VERSION "HINBNNNYYNNNYYNNNNNNNNNNNNYNNNYYYNNYNNNNNN/4//%%/4/'%**4NNN///"

NS_ :

BS_:

BU_: VirtualNMTMaster Master LadderDrive ControlPanel SupportFront SupportRear TTGateway

BO_ 1421 SSDO_013: 8 SupportRear
 SG_ supported_drive_modes_6502 m0 : 32|32@1+ (1,0) [0|4294967295] "" Vector__XXX
 SG_ SubIndex_6502 m25858M : 24|8@1+ (1,0) [0|0] "" Vector__XXX
 SG_ motor_service_period_6407 m0 : 32|32@1+ (1,0) [0|4294967295] "" Vector__XXX
 SG_ SubIndex_6407 m25607M : 24|8@1+ (1,0) [0|0] "" Vector__XXX
 SG_ motor_type_6402 m0 : 32|16@1+ (1,0) [0|65535] "" Vector__XXX
 SG_ SubIndex_6402 m25602M : 24|8@1+ (1,0) [0|0] "" Vector__XXX
 SG_ bitmask_60FE_02 m2 : 32|32@1+ (1,0) [0|4294967295] "" Vector__XXX
 SG_ physical_outputs_60FE_01 m1 : 32|32@1+ (1,0) [0|4294967295] "" Vector__XXX
 SG_ NrOfObjects_60FE_00 m0 : 32|8@1+ (1,0) [0|255] "" Vector__XXX
 SG_ SubIndex_60FE m24830M : 24|8@1+ (1,0) [0|2] "" Vector__XXX
 SG_ digital_inputs_60FD m0 : 32|32@1+ (1,0) [0|4294967295] "" Vector__XXX
 SG_ SubIndex_60FD m24829M : 24|8@1+ (1,0) [0|0] "" Vector__XXX
 SG_ polarity_607E m0 : 32|8@1+ (1,0) [0|255] "" Vector__XXX
 SG_ SubIndex_607E m24702M : 24|8@1+ (1,0) [0|0] "" Vector__XXX
 SG_ position_window_6067 m0 : 32|32@1+ (1,0) [0|4294967295] "" Vector__XXX
 SG_ SubIndex_6067 m24679M : 24|8@1+ (1,0) [0|0] "" Vector__XXX
 SG_ position_actual_value_6064 m0 : 32|32@1- (1,0) [-2147483648|2147483647] "" Vector__XXX
 SG_ SubIndex_6064 m24676M : 24|8@1+ (1,0) [0|0] "" Vector__XXX
 SG_ position_actual_value_6063 m0 : 32|32@1- (1,0) [-2147483648|2147483647] "" Vector__XXX
 SG_ SubIndex_6063 m24675M : 24|8@1+ (1,0) [0|0] "" Vector__XXX
 SG_ position_demand_value_6062 m0 : 32|32@1- (1,0) [-2147483648|2147483647] "" Vector__XXX
 SG_ SubIndex_6062 m24674M : 24|8@1+ (1,0) [0|0] "" Vector__XXX
 SG_ modes_of_operation_display_6061 m0 : 32|8@1- (1,0) [-128|127] "" Vector__XXX
 SG_ SubIndex_6061 m24673M : 24|8@1+ (1,0) [0|0] "" Vector__XXX
 SG_ modes_of_operation_6060 m0 : 32|8@1- (1,0) [-128|127] "" Vector__XXX
 SG_ SubIndex_6060 m24672M : 24|8@1+ (1,0) [0|0] "" Vector__XXX
 SG_ fault_reaction_option_code_605E m0 : 32|16@1- (1,0) [-32768|32767] "" Vector__XXX
 SG_ SubIndex_605E m24670M : 24|8@1+ (1,0) [0|0] "" Vector__XXX
 SG_ stop_option_code_605D m0 : 32|16@1- (1,0) [-32768|32767] "" Vector__XXX
 SG_ SubIndex_605D m24669M : 24|8@1+ (1,0) [0|0] "" Vector__XXX
 SG_ disable_operation_option_co_0003 m0 : 32|16@1- (1,0) [-32768|32767] "" Vector__XXX
 SG_ SubIndex_605C m24668M : 24|8@1+ (1,0) [0|0] "" Vector__XXX
 SG_ shutdown_option_code_605B m0 : 32|16@1- (1,0) [-32768|32767] "" Vector__XXX
 SG_ SubIndex_605B m24667M : 24|8@1+ (1,0) [0|0] "" Vector__XXX
 SG_ quick_stop_option_code_605A m0 : 32|16@1- (1,0) [-32768|32767] "" Vector__XXX
 SG_ SubIndex_605A m24666M : 24|8@1+ (1,0) [0|0] "" Vector__XXX
 SG_ delta_time_6049_02 m2 : 32|16@1+ (1,0) [0|65535] "" Vector__XXX
 SG_ delta_speed_6049_01 m1 : 32|32@1+ (1,0) [0|4294967295] "" Vector__XXX
 SG_ NrOfObjects_6049_00 m0 : 32|8@1+ (1,0) [0|255] "" Vector__XXX
 SG_ SubIndex_6049 m24649M : 24|8@1+ (1,0) [0|2] "" Vector__XXX
 SG_ delta_time_6048_02 m2 : 32|16@1+ (1,0) [0|65535] "" Vector__XXX
 SG_ delta_speed_6048_01 m1 : 32|32@1+ (1,0) [0|4294967295] "" Vector__XXX
 SG_ NrOfObjects_6048_00 m0 : 32|8@1+ (1,0) [0|255] "" Vector__XXX
 SG_ SubIndex_6048 m24648M : 24|8@1+ (1,0) [0|2] "" Vector__XXX
 SG_ vl_velocity_max_amount_6046_02 m2 : 32|32@1+ (1,0) [0|4294967295] "" Vector__XXX
 SG_ vl_velocity_min_amount_6046_01 m1 : 32|32@1+ (1,0) [0|4294967295] "" Vector__XXX
 SG_ vl_velocity_min_max_amount__0003 m0 : 32|8@1+ (1,0) [0|255] "" Vector__XXX
 SG_ SubIndex_6046 m24646M : 24|8@1+ (1,0) [0|2] "" Vector__XXX
 SG_ vl_control_effort_6044 m0 : 32|16@1- (1,0) [-32768|32767] "" Vector__XXX
 SG_ SubIndex_6044 m24644M : 24|8@1+ (1,0) [0|0] "" Vector__XXX
 SG_ vl_velocity_demand_6043 m0 : 32|16@1- (1,0) [-32768|32767] "" Vector__XXX
 SG_ SubIndex_6043 m24643M : 24|8@1+ (1,0) [0|0] "" Vector__XXX
 SG_ vl_target_velocity_6042 m0 : 32|16@1- (1,0) [-32768|32767] "" Vector__XXX
 SG_ SubIndex_6042 m24642M : 24|8@1+ (1,0) [0|0] "" Vector__XXX
 SG_ statusword_6041 m0 : 32|16@1+ (1,0) [0|65535] "" Vector__XXX
 SG_ SubIndex_6041 m24641M : 24|8@1+ (1,0) [0|0] "" Vector__XXX
 SG_ controlword_6040 m0 : 32|16@1+ (1,0) [0|65535] "" Vector__XXX
 SG_ SubIndex_6040 m24640M : 24|8@1+ (1,0) [0|0] "" Vector__XXX
 SG_ error_code_603F m0 : 32|16@1+ (1,0) [0|65535] "" Vector__XXX
 SG_ SubIndex_603F m24639M : 24|8@1+ (1,0) [0|0] "" Vector__XXX
 SG_ abort_connection_option_cod_0003 m0 : 32|16@1- (1,0) [-32768|3] "" Vector__XXX
 SG_ SubIndex_6007 m24583M : 24|8@1+ (1,0) [0|0] "" Vector__XXX
 SG_ NrOfMappedObjects_1A06_00 m0 : 32|8@1+ (1,0) [0|8] "" Vector__XXX
 SG_ SubIndex_1A06 m6662M : 24|8@1+ (1,0) [0|0] "" Vector__XXX
 SG_ NrOfMappedObjects_1A05_00 m0 : 32|8@1+ (1,0) [0|8] "" Vector__XXX
 SG_ SubIndex_1A05 m6661M : 24|8@1+ (1,0) [0|0] "" Vector__XXX
 SG_ NrOfMappedObjects_1A04_00 m0 : 32|8@1+ (1,0) [0|8] "" Vector__XXX
 SG_ SubIndex_1A04 m6660M : 24|8@1+ (1,0) [0|0] "" Vector__XXX
 SG_ NrOfMappedObjects_1A03_00 m0 : 32|8@1+ (1,0) [0|8] "" Vector__XXX
 SG_ SubIndex_1A03 m6659M : 24|8@1+ (1,0) [0|0] "" Vector__XXX
 SG_ NrOfMappedObjects_1A02_00 m0 : 32|8@1+ (1,0) [0|8] "" Vector__XXX
 SG_ SubIndex_1A02 m6658M : 24|8@1+ (1,0) [0|0] "" Vector__XXX
 SG_ NrOfMappedObjects_1A01_00 m0 : 32|8@1+ (1,0) [0|8] "" Vector__XXX
 SG_ SubIndex_1A01 m6657M : 24|8@1+ (1,0) [0|0] "" Vector__XXX
 SG_ mappedObj2_1A00_02 m2 : 32|32@1+ (1,0) [0|4294967295] "" Vector__XXX
 SG_ mappedObj1_1A00_01 m1 : 32|32@1+ (1,0) [0|4294967295] "" Vector__XXX
 SG_ NrOfMappedObjects_1A00_00 m0 : 32|8@1+ (1,0) [0|8] "" Vector__XXX
 SG_ SubIndex_1A00 m6656M : 24|8@1+ (1,0) [0|2] "" Vector__XXX
 SG_ EventTimer_1806_05 m5 : 32|16@1+ (1,0) [0|65535] "" Vector__XXX
 SG_ TransmissionType_1806_02 m2 : 32|8@1+ (1,0) [0|255] "" Vector__XXX
 SG_ COB_ID_1806_01 m1 : 32|32@1+ (1,0) [128|4294967295] "" Vector__XXX
 SG_ NrOfEntries_1806_00 m0 : 32|8@1+ (1,0) [2|5] "" Vector__XXX
 SG_ SubIndex_1806 m6150M : 24|8@1+ (1,0) [0|5] "" Vector__XXX
 SG_ EventTimer_1805_05 m5 : 32|16@1+ (1,0) [0|65535] "" Vector__XXX
 SG_ TransmissionType_1805_02 m2 : 32|8@1+ (1,0) [0|255] "" Vector__XXX
 SG_ COB_ID_1805_01 m1 : 32|32@1+ (1,0) [128|4294967295] "" Vector__XXX
 SG_ NrOfEntries_1805_00 m0 : 32|8@1+ (1,0) [2|5] "" Vector__XXX
 SG_ SubIndex_1805 m6149M : 24|8@1+ (1,0) [0|5] "" Vector__XXX
 SG_ EventTimer_1804_05 m5 : 32|16@1+ (1,0) [0|65535] "" Vector__XXX
 SG_ TransmissionType_1804_02 m2 : 32|8@1+ (1,0) [0|255] "" Vector__XXX
 SG_ COB_ID_1804_01 m1 : 32|32@1+ (1,0) [128|4294967295] "" Vector__XXX
 SG_ NrOfEntries_1804_00 m0 : 32|8@1+ (1,0) [2|5] "" Vector__XXX
 SG_ SubIndex_1804 m6148M : 24|8@1+ (1,0) [0|5] "" Vector__XXX
 SG_ EventTimer_1803_05 m5 : 32|16@1+ (1,0) [0|65535] "" Vector__XXX
 SG_ TransmissionType_1803_02 m2 : 32|8@1+ (1,0) [0|255] "" Vector__XXX
 SG_ COB_ID_1803_01 m1 : 32|32@1+ (1,0) [128|4294967295] "" Vector__XXX
 SG_ NrOfEntries_1803_00 m0 : 32|8@1+ (1,0) [2|5] "" Vector__XXX
 SG_ SubIndex_1803 m6147M : 24|8@1+ (1,0) [0|5] "" Vector__XXX
 SG_ EventTimer_1802_05 m5 : 32|16@1+ (1,0) [0|65535] "" Vector__XXX
 SG_ TransmissionType_1802_02 m2 : 32|8@1+ (1,0) [0|255] "" Vector__XXX
 SG_ COB_ID_1802_01 m1 : 32|32@1+ (1,0) [128|4294967295] "" Vector__XXX
 SG_ NrOfEntries_1802_00 m0 : 32|8@1+ (1,0) [2|5] "" Vector__XXX
 SG_ SubIndex_1802 m6146M : 24|8@1+ (1,0) [0|5] "" Vector__XXX
 SG_ EventTimer_1801_05 m5 : 32|16@1+ (1,0) [0|65535] "" Vector__XXX
 SG_ TransmissionType_1801_02 m2 : 32|8@1+ (1,0) [0|255] "" Vector__XXX
 SG_ COB_ID_1801_01 m1 : 32|32@1+ (1,0) [128|4294967295] "" Vector__XXX
 SG_ NrOfEntries_1801_00 m0 : 32|8@1+ (1,0) [2|5] "" Vector__XXX
 SG_ SubIndex_1801 m6145M : 24|8@1+ (1,0) [0|5] "" Vector__XXX
 SG_ EventTimer_1800_05 m5 : 32|16@1+ (1,0) [0|65535] "" Vector__XXX
 SG_ TransmissionType_1800_02 m2 : 32|8@1+ (1,0) [0|255] "" Vector__XXX
 SG_ COB_ID_1800_01 m1 : 32|32@1+ (1,0) [128|4294967295] "" Vector__XXX
 SG_ NrOfEntries_1800_00 m0 : 32|8@1+ (1,0) [2|5] "" Vector__XXX
 SG_ SubIndex_1800 m6144M : 24|8@1+ (1,0) [0|5] "" Vector__XXX
 SG_ NrOfMappedObjects_1607_00 m0 : 32|8@1+ (1,0) [0|8] "" Vector__XXX
 SG_ SubIndex_1607 m5639M : 24|8@1+ (1,0) [0|0] "" Vector__XXX
 SG_ NrOfMappedObjects_1606_00 m0 : 32|8@1+ (1,0) [0|8] "" Vector__XXX
 SG_ SubIndex_1606 m5638M : 24|8@1+ (1,0) [0|0] "" Vector__XXX
 SG_ NrOfMappedObjects_1605_00 m0 : 32|8@1+ (1,0) [0|8] "" Vector__XXX
 SG_ SubIndex_1605 m5637M : 24|8@1+ (1,0) [0|0] "" Vector__XXX
 SG_ NrOfMappedObjects_1604_00 m0 : 32|8@1+ (1,0) [0|8] "" Vector__XXX
 SG_ SubIndex_1604 m5636M : 24|8@1+ (1,0) [0|0] "" Vector__XXX
 SG_ NrOfMappedObjects_1603_00 m0 : 32|8@1+ (1,0) [0|8] "" Vector__XXX
 SG_ SubIndex_1603 m5635M : 24|8@1+ (1,0) [0|0] "" Vector__XXX
 SG_ NrOfMappedObjects_1602_00 m0 : 32|8@1+ (1,0) [0|8] "" Vector__XXX
 SG_ SubIndex_1602 m5634M : 24|8@1+ (1,0) [0|0] "" Vector__XXX
 SG_ NrOfMappedObjects_1601_00 m0 : 32|8@1+ (1,0) [0|8] "" Vector__XXX
 SG_ SubIndex_1601 m5633M : 24|8@1+ (1,0) [0|0] "" Vector__XXX
 SG_ mappedObj2_1600_02 m2 : 32|32@1+ (1,0) [0|4294967295] "" Vector__XXX
 SG_ mappedObj1_1600_01 m1 : 32|32@1+ (1,0) [0|4294967295] "" Vector__XXX
 SG_ NrOfMappedObjects_1600_00 m0 : 32|8@1+ (1,0) [0|8] "" Vector__XXX
 SG_ SubIndex_1600 m5632M : 24|8@1+ (1,0) [0|2] "" Vector__XXX
 SG_ TransmissionType_1407_02 m2 : 32|8@1+ (1,0) [0|255] "" Vector__XXX
 SG_ COB_ID_1407_01 m1 : 32|32@1+ (1,0) [128|4294967295] "" Vector__XXX
 SG_ NrOfEntries_1407_00 m0 : 32|8@1+ (1,0) [2|5] "" Vector__XXX
 SG_ SubIndex_1407 m5127M : 24|8@1+ (1,0) [0|2] "" Vector__XXX
 SG_ TransmissionType_1406_02 m2 : 32|8@1+ (1,0) [0|255] "" Vector__XXX
 SG_ COB_ID_1406_01 m1 : 32|32@1+ (1,0) [128|4294967295] "" Vector__XXX
 SG_ NrOfEntries_1406_00 m0 : 32|8@1+ (1,0) [2|5] "" Vector__XXX
 SG_ SubIndex_1406 m5126M : 24|8@1+ (1,0) [0|2] "" Vector__XXX
 SG_ TransmissionType_1405_02 m2 : 32|8@1+ (1,0) [0|255] "" Vector__XXX
 SG_ COB_ID_1405_01 m1 : 32|32@1+ (1,0) [128|4294967295] "" Vector__XXX
 SG_ NrOfEntries_1405_00 m0 : 32|8@1+ (1,0) [2|5] "" Vector__XXX
 SG_ SubIndex_1405 m5125M : 24|8@1+ (1,0) [0|2] "" Vector__XXX
 SG_ TransmissionType_1404_02 m2 : 32|8@1+ (1,0) [0|255] "" Vector__XXX
 SG_ COB_ID_1404_01 m1 : 32|32@1+ (1,0) [128|4294967295] "" Vector__XXX
 SG_ NrOfEntries_1404_00 m0 : 32|8@1+ (1,0) [2|5] "" Vector__XXX
 SG_ SubIndex_1404 m5124M : 24|8@1+ (1,0) [0|2] "" Vector__XXX
 SG_ TransmissionType_1403_02 m2 : 32|8@1+ (1,0) [0|255] "" Vector__XXX
 SG_ COB_ID_1403_01 m1 : 32|32@1+ (1,0) [128|4294967295] "" Vector__XXX
 SG_ NrOfEntries_1403_00 m0 : 32|8@1+ (1,0) [2|5] "" Vector__XXX
 SG_ SubIndex_1403 m5123M : 24|8@1+ (1,0) [0|2] "" Vector__XXX
 SG_ TransmissionType_1402_02 m2 : 32|8@1+ (1,0) [0|255] "" Vector__XXX
 SG_ COB_ID_1402_01 m1 : 32|32@1+ (1,0) [128|4294967295] "" Vector__XXX
 SG_ NrOfEntries_1402_00 m0 : 32|8@1+ (1,0) [2|5] "" Vector__XXX
 SG_ SubIndex_1402 m5122M : 24|8@1+ (1,0) [0|2] "" Vector__XXX
 SG_ TransmissionType_1401_02 m2 : 32|8@1+ (1,0) [0|255] "" Vector__XXX
 SG_ COB_ID_1401_01 m1 : 32|32@1+ (1,0) [128|4294967295] "" Vector__XXX
 SG_ NrOfEntries_1401_00 m0 : 32|8@1+ (1,0) [2|5] "" Vector__XXX
 SG_ SubIndex_1401 m5121M : 24|8@1+ (1,0) [0|2] "" Vector__XXX
 SG_ TransmissionType_1400_02 m2 : 32|8@1+ (1,0) [0|255] "" Vector__XXX
 SG_ COB_ID_1400_01 m1 : 32|32@1+ (1,0) [128|4294967295] "" Vector__XXX
 SG_ NrOfEntries_1400_00 m0 : 32|8@1+ (1,0) [2|5] "" Vector__XXX
 SG_ SubIndex_1400 m5120M : 24|8@1+ (1,0) [0|2] "" Vector__XXX
 SG_ Serial_number_1018_04 m4 : 32|32@1+ (1,0) [0|4294967295] "" Vector__XXX
 SG_ Revision_number_1018_03 m3 : 32|32@1+ (1,0) [0|4294967295] "" Vector__XXX
 SG_ Product_Code_1018_02 m2 : 32|32@1+ (1,0) [0|4294967295] "" Vector__XXX
 SG_ Vendor_Id_1018_01 m1 : 32|32@1+ (1,0) [0|4294967295] "" Vector__XXX
 SG_ number_of_entries_1018_00 m0 : 32|8@1+ (1,0) [1|4] "" Vector__XXX
 SG_ SubIndex_1018 m4120M : 24|8@1+ (1,0) [0|4] "" Vector__XXX
 SG_ Producer_Heartbeat_Time_1017 m0 : 32|16@1+ (1,0) [0|65535] "" Vector__XXX
 SG_ SubIndex_1017 m4119M : 24|8@1+ (1,0) [0|0] "" Vector__XXX
 SG_ Consumer_Heartbeat_Time126_1016_ m126 : 32|32@1+ (1,0) [0|4294967295] "" Vector__XXX
 SG_ Consumer_Heartbeat_Time125_1016_ m125 : 32|32@1+ (1,0) [0|4294967295] "" Vector__XXX
 SG_ Consumer_Heartbeat_Time124_1016_ m124 : 32|32@1+ (1,0) [0|4294967295] "" Vector__XXX
 SG_ Consumer_Heartbeat_Time123_1016_ m123 : 32|32@1+ (1,0) [0|4294967295] "" Vector__XXX
 SG_ Consumer_Heartbeat_Time122_1016_ m122 : 32|32@1+ (1,0) [0|4294967295] "" Vector__XXX
 SG_ Consumer_Heartbeat_Time121_1016_ m121 : 32|32@1+ (1,0) [0|4294967295] "" Vector__XXX
 SG_ Consumer_Heartbeat_Time120_1016_ m120 : 32|32@1+ (1,0) [0|4294967295] "" Vector__XXX
 SG_ Consumer_Heartbeat_Time119_1016_ m119 : 32|32@1+ (1,0) [0|4294967295] "" Vector__XXX
 SG_ Consumer_Heartbeat_Time118_1016_ m118 : 32|32@1+ (1,0) [0|4294967295] "" Vector__XXX
 SG_ Consumer_Heartbeat_Time117_1016_ m117 : 32|32@1+ (1,0) [0|4294967295] "" Vector__XXX
 SG_ Consumer_Heartbeat_Time116_1016_ m116 : 32|32@1+ (1,0) [0|4294967295] "" Vector__XXX
 SG_ Consumer_Heartbeat_Time115_1016_ m115 : 32|32@1+ (1,0) [0|4294967295] "" Vector__XXX
 SG_ Consumer_Heartbeat_Time114_1016_ m114 : 32|32@1+ (1,0) [0|4294967295] "" Vector__XXX
 SG_ Consumer_Heartbeat_Time113_1016_ m113 : 32|32@1+ (1,0) [0|4294967295] "" Vector__XXX
 SG_ Consumer_Heartbeat_Time112_1016_ m112 : 32|32@1+ (1,0) [0|4294967295] "" Vector__XXX
 SG_ Consumer_Heartbeat_Time111_1016_ m111 : 32|32@1+ (1,0) [0|4294967295] "" Vector__XXX
 SG_ Consumer_Heartbeat_Time110_1016_ m110 : 32|32@1+ (1,0) [0|4294967295] "" Vector__XXX
 SG_ Consumer_Heartbeat_Time109_1016_ m109 : 32|32@1+ (1,0) [0|4294967295] "" Vector__XXX
 SG_ Consumer_Heartbeat_Time108_1016_ m108 : 32|32@1+ (1,0) [0|4294967295] "" Vector__XXX
 SG_ Consumer_Heartbeat_Time107_1016_ m107 : 32|32@1+ (1,0) [0|4294967295] "" Vector__XXX
 SG_ Consumer_Heartbeat_Time106_1016_ m106 : 32|32@1+ (1,0) [0|4294967295] "" Vector__XXX
 SG_ Consumer_Heartbeat_Time105_1016_ m105 : 32|32@1+ (1,0) [0|4294967295] "" Vector__XXX
 SG_ Consumer_Heartbeat_Time104_1016_ m104 : 32|32@1+ (1,0) [0|4294967295] "" Vector__XXX
 SG_ Consumer_Heartbeat_Time103_1016_ m103 : 32|32@1+ (1,0) [0|4294967295] "" Vector__XXX
 SG_ Consumer_Heartbeat_Time102_1016_ m102 : 32|32@1+ (1,0) [0|4294967295] "" Vector__XXX
 SG_ Consumer_Heartbeat_Time101_1016_ m101 : 32|32@1+ (1,0) [0|4294967295] "" Vector__XXX
 SG_ Consumer_Heartbeat_Time100_1016_ m100 : 32|32@1+ (1,0) [0|4294967295] "" Vector__XXX
 SG_ Consumer_Heartbeat_Time99_1016_6 m99 : 32|32@1+ (1,0) [0|4294967295] "" Vector__XXX
 SG_ Consumer_Heartbeat_Time98_1016_6 m98 : 32|32@1+ (1,0) [0|4294967295] "" Vector__XXX
 SG_ Consumer_Heartbeat_Time97_1016_6 m97 : 32|32@1+ (1,0) [0|4294967295] "" Vector__XXX
 SG_ Consumer_Heartbeat_Time96_1016_6 m96 : 32|32@1+ (1,0) [0|4294967295] "" Vector__XXX
 SG_ Consumer_Heartbeat_Time95_1016_5 m95 : 32|32@1+ (1,0) [0|4294967295] "" Vector__XXX
 SG_ Consumer_Heartbeat_Time94_1016_5 m94 : 32|32@1+ (1,0) [0|4294967295] "" Vector__XXX
 SG_ Consumer_Heartbeat_Time93_1016_5 m93 : 32|32@1+ (1,0) [0|4294967295] "" Vector__XXX
 SG_ Consumer_Heartbeat_Time92_1016_5 m92 : 32|32@1+ (1,0) [0|4294967295] "" Vector__XXX
 SG_ Consumer_Heartbeat_Time91_1016_5 m91 : 32|32@1+ (1,0) [0|4294967295] "" Vector__XXX
 SG_ Consumer_Heartbeat_Time90_1016_5 m90 : 32|32@1+ (1,0) [0|4294967295] "" Vector__XXX
 SG_ Consumer_Heartbeat_Time89_1016_5 m89 : 32|32@1+ (1,0) [0|4294967295] "" Vector__XXX
 SG_ Consumer_Heartbeat_Time88_1016_5 m88 : 32|32@1+ (1,0) [0|4294967295] "" Vector__XXX
 SG_ Consumer_Heartbeat_Time87_1016_5 m87 : 32|32@1+ (1,0) [0|4294967295] "" Vector__XXX
 SG_ Consumer_Heartbeat_Time86_1016_5 m86 : 32|32@1+ (1,0) [0|4294967295] "" Vector__XXX
 SG_ Consumer_Heartbeat_Time85_1016_5 m85 : 32|32@1+ (1,0) [0|4294967295] "" Vector__XXX
 SG_ Consumer_Heartbeat_Time84_1016_5 m84 : 32|32@1+ (1,0) [0|4294967295] "" Vector__XXX
 SG_ Consumer_Heartbeat_Time83_1016_5 m83 : 32|32@1+ (1,0) [0|4294967295] "" Vector__XXX
 SG_ Consumer_Heartbeat_Time82_1016_5 m82 : 32|32@1+ (1,0) [0|4294967295] "" Vector__XXX
 SG_ Consumer_Heartbeat_Time81_1016_5 m81 : 32|32@1+ (1,0) [0|4294967295] "" Vector__XXX
 SG_ Consumer_Heartbeat_Time80_1016_5 m80 : 32|32@1+ (1,0) [0|4294967295] "" Vector__XXX
 SG_ Consumer_Heartbeat_Time79_1016_4 m79 : 32|32@1+ (1,0) [0|4294967295] "" Vector__XXX
 SG_ Consumer_Heartbeat_Time78_1016_4 m78 : 32|32@1+ (1,0) [0|4294967295] "" Vector__XXX
 SG_ Consumer_Heartbeat_Time77_1016_4 m77 : 32|32@1+ (1,0) [0|4294967295] "" Vector__XXX
 SG_ Consumer_Heartbeat_Time76_1016_4 m76 : 32|32@1+ (1,0) [0|4294967295] "" Vector__XXX
 SG_ Consumer_Heartbeat_Time75_1016_4 m75 : 32|32@1+ (1,0) [0|4294967295] "" Vector__XXX
 SG_ Consumer_Heartbeat_Time74_1016_4 m74 : 32|32@1+ (1,0) [0|4294967295] "" Vector__XXX
 SG_ Consumer_Heartbeat_Time73_1016_4 m73 : 32|32@1+ (1,0) [0|4294967295] "" Vector__XXX
 SG_ Consumer_Heartbeat_Time72_1016_4 m72 : 32|32@1+ (1,0) [0|4294967295] "" Vector__XXX
 SG_ Consumer_Heartbeat_Time71_1016_4 m71 : 32|32@1+ (1,0) [0|4294967295] "" Vector__XXX
 SG_ Consumer_Heartbeat_Time70_1016_4 m70 : 32|32@1+ (1,0) [0|4294967295] "" Vector__XXX
 SG_ Consumer_Heartbeat_Time69_1016_4 m69 : 32|32@1+ (1,0) [0|4294967295] "" Vector__XXX
 SG_ Consumer_Heartbeat_Time68_1016_4 m68 : 32|32@1+ (1,0) [0|4294967295] "" Vector__XXX
 SG_ Consumer_Heartbeat_Time67_1016_4 m67 : 32|32@1+ (1,0) [0|4294967295] "" Vector__XXX
 SG_ Consumer_Heartbeat_Time66_1016_4 m66 : 32|32@1+ (1,0) [0|4294967295] "" Vector__XXX
 SG_ Consumer_Heartbeat_Time65_1016_4 m65 : 32|32@1+ (1,0) [0|4294967295] "" Vector__XXX
 SG_ Consumer_Heartbeat_Time64_1016_4 m64 : 32|32@1+ (1,0) [0|4294967295] "" Vector__XXX
 SG_ Consumer_Heartbeat_Time63_1016_3 m63 : 32|32@1+ (1,0) [0|4294967295] "" Vector__XXX
 SG_ Consumer_Heartbeat_Time62_1016_3 m62 : 32|32@1+ (1,0) [0|4294967295] "" Vector__XXX
 SG_ Consumer_Heartbeat_Time61_1016_3 m61 : 32|32@1+ (1,0) [0|4294967295] "" Vector__XXX
 SG_ Consumer_Heartbeat_Time60_1016_3 m60 : 32|32@1+ (1,0) [0|4294967295] "" Vector__XXX
 SG_ Consumer_Heartbeat_Time59_1016_3 m59 : 32|32@1+ (1,0) [0|4294967295] "" Vector__XXX
 SG_ Consumer_Heartbeat_Time58_1016_3 m58 : 32|32@1+ (1,0) [0|4294967295] "" Vector__XXX
 SG_ Consumer_Heartbeat_Time57_1016_3 m57 : 32|32@1+ (1,0) [0|4294967295] "" Vector__XXX
 SG_ Consumer_Heartbeat_Time56_1016_3 m56 : 32|32@1+ (1,0) [0|4294967295] "" Vector__XXX
 SG_ Consumer_Heartbeat_Time55_1016_3 m55 : 32|32@1+ (1,0) [0|4294967295] "" Vector__XXX
 SG_ Consumer_Heartbeat_Time54_1016_3 m54 : 32|32@1+ (1,0) [0|4294967295] "" Vector__XXX
 SG_ Consumer_Heartbeat_Time53_1016_3 m53 : 32|32@1+ (1,0) [0|4294967295] "" Vector__XXX
 SG_ Consumer_Heartbeat_Time52_1016_3 m52 : 32|32@1+ (1,0) [0|4294967295] "" Vector__XXX
 SG_ Consumer_Heartbeat_Time51_1016_3 m51 : 32|32@1+ (1,0) [0|4294967295] "" Vector__XXX
 SG_ Consumer_Heartbeat_Time50_1016_3 m50 : 32|32@1+ (1,0) [0|4294967295] "" Vector__XXX
 SG_ Consumer_Heartbeat_Time49_1016_3 m49 : 32|32@1+ (1,0) [0|4294967295] "" Vector__XXX
 SG_ Consumer_Heartbeat_Time48_1016_3 m48 : 32|32@1+ (1,0) [0|4294967295] "" Vector__XXX
 SG_ Consumer_Heartbeat_Time47_1016_2 m47 : 32|32@1+ (1,0) [0|4294967295] "" Vector__XXX
 SG_ Consumer_Heartbeat_Time46_1016_2 m46 : 32|32@1+ (1,0) [0|4294967295] "" Vector__XXX
 SG_ Consumer_Heartbeat_Time45_1016_2 m45 : 32|32@1+ (1,0) [0|4294967295] "" Vector__XXX
 SG_ Consumer_Heartbeat_Time44_1016_2 m44 : 32|32@1+ (1,0) [0|4294967295] "" Vector__XXX
 SG_ Consumer_Heartbeat_Time43_1016_2 m43 : 32|32@1+ (1,0) [0|4294967295] "" Vector__XXX
 SG_ Consumer_Heartbeat_Time42_1016_2 m42 : 32|32@1+ (1,0) [0|4294967295] "" Vector__XXX
 SG_ Consumer_Heartbeat_Time41_1016_2 m41 : 32|32@1+ (1,0) [0|4294967295] "" Vector__XXX
 SG_ Consumer_Heartbeat_Time40_1016_2 m40 : 32|32@1+ (1,0) [0|4294967295] "" Vector__XXX
 SG_ Consumer_Heartbeat_Time39_1016_2 m39 : 32|32@1+ (1,0) [0|4294967295] "" Vector__XXX
 SG_ Consumer_Heartbeat_Time38_1016_2 m38 : 32|32@1+ (1,0) [0|4294967295] "" Vector__XXX
 SG_ Consumer_Heartbeat_Time37_1016_2 m37 : 32|32@1+ (1,0) [0|4294967295] "" Vector__XXX
 SG_ Consumer_Heartbeat_Time36_1016_2 m36 : 32|32@1+ (1,0) [0|4294967295] "" Vector__XXX
 SG_ Consumer_Heartbeat_Time35_1016_2 m35 : 32|32@1+ (1,0) [0|4294967295] "" Vector__XXX
 SG_ Consumer_Heartbeat_Time34_1016_2 m34 : 32|32@1+ (1,0) [0|4294967295] "" Vector__XXX
 SG_ Consumer_Heartbeat_Time33_1016_2 m33 : 32|32@1+ (1,0) [0|4294967295] "" Vector__XXX
 SG_ Consumer_Heartbeat_Time32_1016_2 m32 : 32|32@1+ (1,0) [0|4294967295] "" Vector__XXX
 SG_ Consumer_Heartbeat_Time31_1016_1 m31 : 32|32@1+ (1,0) [0|4294967295] "" Vector__XXX
 SG_ Consumer_Heartbeat_Time30_1016_1 m30 : 32|32@1+ (1,0) [0|4294967295] "" Vector__XXX
 SG_ Consumer_Heartbeat_Time29_1016_1 m29 : 32|32@1+ (1,0) [0|4294967295] "" Vector__XXX
 SG_ Consumer_Heartbeat_Time28_1016_1 m28 : 32|32@1+ (1,0) [0|4294967295] "" Vector__XXX
 SG_ Consumer_Heartbeat_Time27_1016_1 m27 : 32|32@1+ (1,0) [0|4294967295] "" Vector__XXX
 SG_ Consumer_Heartbeat_Time26_1016_1 m26 : 32|32@1+ (1,0) [0|4294967295] "" Vector__XXX
 SG_ Consumer_Heartbeat_Time25_1016_1 m25 : 32|32@1+ (1,0) [0|4294967295] "" Vector__XXX
 SG_ Consumer_Heartbeat_Time24_1016_1 m24 : 32|32@1+ (1,0) [0|4294967295] "" Vector__XXX
 SG_ Consumer_Heartbeat_Time23_1016_1 m23 : 32|32@1+ (1,0) [0|4294967295] "" Vector__XXX
 SG_ Consumer_Heartbeat_Time22_1016_1 m22 : 32|32@1+ (1,0) [0|4294967295] "" Vector__XXX
 SG_ Consumer_Heartbeat_Time21_1016_1 m21 : 32|32@1+ (1,0) [0|4294967295] "" Vector__XXX
 SG_ Consumer_Heartbeat_Time20_1016_1 m20 : 32|32@1+ (1,0) [0|4294967295] "" Vector__XXX
 SG_ Consumer_Heartbeat_Time19_1016_1 m19 : 32|32@1+ (1,0) [0|4294967295] "" Vector__XXX
 SG_ Consumer_Heartbeat_Time18_1016_1 m18 : 32|32@1+ (1,0) [0|4294967295] "" Vector__XXX
 SG_ Consumer_Heartbeat_Time17_1016_1 m17 : 32|32@1+ (1,0) [0|4294967295] "" Vector__XXX
 SG_ Consumer_Heartbeat_Time16_1016_1 m16 : 32|32@1+ (1,0) [0|4294967295] "" Vector__XXX
 SG_ Consumer_Heartbeat_Time15_1016_0 m15 : 32|32@1+ (1,0) [0|4294967295] "" Vector__XXX
 SG_ Consumer_Heartbeat_Time14_1016_0 m14 : 32|32@1+ (1,0) [0|4294967295] "" Vector__XXX
 SG_ Consumer_Heartbeat_Time13_1016_0 m13 : 32|32@1+ (1,0) [0|4294967295] "" Vector__XXX
 SG_ Consumer_Heartbeat_Time12_1016_0 m12 : 32|32@1+ (1,0) [0|4294967295] "" Vector__XXX
 SG_ Consumer_Heartbeat_Time11_1016_0 m11 : 32|32@1+ (1,0) [0|4294967295] "" Vector__XXX
 SG_ Consumer_Heartbeat_Time10_1016_0 m10 : 32|32@1+ (1,0) [0|4294967295] "" Vector__XXX
 SG_ Consumer_Heartbeat_Time_1016_09 m9 : 32|32@1+ (1,0) [0|4294967295] "" Vector__XXX
 SG_ Consumer_Heartbeat_Time_1016_08 m8 : 32|32@1+ (1,0) [0|4294967295] "" Vector__XXX
 SG_ Consumer_Heartbeat_Time_1016_07 m7 : 32|32@1+ (1,0) [0|4294967295] "" Vector__XXX
 SG_ Consumer_Heartbeat_Time_1016_06 m6 : 32|32@1+ (1,0) [0|4294967295] "" Vector__XXX
 SG_ Consumer_Heartbeat_Time_1016_05 m5 : 32|32@1+ (1,0) [0|4294967295] "" Vector__XXX
 SG_ Consumer_Heartbeat_Time_1016_04 m4 : 32|32@1+ (1,0) [0|4294967295] "" Vector__XXX
 SG_ Consumer_Heartbeat_Time_1016_03 m3 : 32|32@1+ (1,0) [0|4294967295] "" Vector__XXX
 SG_ Consumer_Heartbeat_Time_1016_02 m2 : 32|32@1+ (1,0) [0|4294967295] "" Vector__XXX
 SG_ Consumer_Heartbeat_Time_1016_01 m1 : 32|32@1+ (1,0) [0|4294967295] "" Vector__XXX
 SG_ NrOfObjects_1016_00 m0 : 32|8@1+ (1,0) [0|255] "" Vector__XXX
 SG_ SubIndex_1016 m4118M : 24|8@1+ (1,0) [0|126] "" Vector__XXX
 SG_ Save_all_Parameters_1010_01 m1 : 32|32@1+ (1,0) [0|4294967295] "" Vector__XXX
 SG_ Number_of_Entries_1010_00 m0 : 32|8@1+ (1,0) [0|255] "" Vector__XXX
 SG_ SubIndex_1010 m4112M : 24|8@1+ (1,0) [0|1] "" Vector__XXX
 SG_ Life_Time_Factor_100D m0 : 32|8@1+ (1,0) [0|255] "" Vector__XXX
 SG_ SubIndex_100D m4109M : 24|8@1+ (1,0) [0|0] "" Vector__XXX
 SG_ Guard_Time_100C m0 : 32|16@1+ (1,0) [0|65535] "" Vector__XXX
 SG_ SubIndex_100C m4108M : 24|8@1+ (1,0) [0|0] "" Vector__XXX
 SG_ Sync_Window_Length_1007 m0 : 32|32@1+ (1,0) [0|4294967295] "" Vector__XXX
 SG_ SubIndex_1007 m4103M : 24|8@1+ (1,0) [0|0] "" Vector__XXX
 SG_ Communication_Cycle_Period_1006 m0 : 32|32@1+ (1,0) [0|4294967295] "" Vector__XXX
 SG_ SubIndex_1006 m4102M : 24|8@1+ (1,0) [0|0] "" Vector__XXX
 SG_ COB_ID_SYNC_1005 m0 : 32|32@1+ (1,0) [128|4294967295] "" Vector__XXX
 SG_ SubIndex_1005 m4101M : 24|8@1+ (1,0) [0|0] "" Vector__XXX
 SG_ Manufacturer_Status_Registe_0007 m0 : 32|32@1+ (1,0) [0|4294967295] "" Vector__XXX
 SG_ SubIndex_1002 m4098M : 24|8@1+ (1,0) [0|0] "" Vector__XXX
 SG_ Error_Register_1001 m0 : 32|8@1+ (1,0) [0|255] "" Vector__XXX
 SG_ SubIndex_1001 m4097M : 24|8@1+ (1,0) [0|0] "" Vector__XXX
 SG_ Device_Type_1000 m0 : 32|32@1+ (1,0) [0|4294967295] "" Vector__XXX
 SG_ SubIndex_1000 m4096M : 24|8@1+ (1,0) [0|0] "" Vector__XXX
 SG_ Index m1M : 8|16@1+ (1,0) [4096|25861] "" Vector__XXX
 SG_ TransferType m1M : 1|1@1+ (1,0) [0|1] "" Vector__XXX
 SG_ NotUsedBytes m1 : 2|2@1+ (1,0) [0|3] "" Vector__XXX
 SG_ SizeIndicator m1 : 0|1@1+ (1,0) [0|1] "" Vector__XXX
 SG_ SCS M : 5|3@1+ (1,0) [0|6] "" Vector__XXX

BO_ 1549 CSDO_013: 8 Vector__XXX
 SG_ supported_drive_modes_6502 m0 : 32|32@1+ (1,0) [0|4294967295] ""  SupportRear
 SG_ SubIndex_6502 m25858M : 24|8@1+ (1,0) [0|0] ""  SupportRear
 SG_ motor_service_period_6407 m0 : 32|32@1+ (1,0) [0|4294967295] ""  SupportRear
 SG_ SubIndex_6407 m25607M : 24|8@1+ (1,0) [0|0] ""  SupportRear
 SG_ motor_type_6402 m0 : 32|16@1+ (1,0) [0|65535] ""  SupportRear
 SG_ SubIndex_6402 m25602M : 24|8@1+ (1,0) [0|0] ""  SupportRear
 SG_ bitmask_60FE_02 m2 : 32|32@1+ (1,0) [0|4294967295] ""  SupportRear
 SG_ physical_outputs_60FE_01 m1 : 32|32@1+ (1,0) [0|4294967295] ""  SupportRear
 SG_ NrOfObjects_60FE_00 m0 : 32|8@1+ (1,0) [0|255] ""  SupportRear
 SG_ SubIndex_60FE m24830M : 24|8@1+ (1,0) [0|2] ""  SupportRear
 SG_ digital_inputs_60FD m0 : 32|32@1+ (1,0) [0|4294967295] ""  SupportRear
 SG_ SubIndex_60FD m24829M : 24|8@1+ (1,0) [0|0] ""  SupportRear
 SG_ polarity_607E m0 : 32|8@1+ (1,0) [0|255] ""  SupportRear
 SG_ SubIndex_607E m24702M : 24|8@1+ (1,0) [0|0] ""  SupportRear
 SG_ position_window_6067 m0 : 32|32@1+ (1,0) [0|4294967295] ""  SupportRear
 SG_ SubIndex_6067 m24679M : 24|8@1+ (1,0) [0|0] ""  SupportRear
 SG_ position_actual_value_6064 m0 : 32|32@1- (1,0) [-2147483648|2147483647] ""  SupportRear
 SG_ SubIndex_6064 m24676M : 24|8@1+ (1,0) [0|0] ""  SupportRear
 SG_ position_actual_value_6063 m0 : 32|32@1- (1,0) [-2147483648|2147483647] ""  SupportRear
 SG_ SubIndex_6063 m24675M : 24|8@1+ (1,0) [0|0] ""  SupportRear
 SG_ position_demand_value_6062 m0 : 32|32@1- (1,0) [-2147483648|2147483647] ""  SupportRear
 SG_ SubIndex_6062 m24674M : 24|8@1+ (1,0) [0|0] ""  SupportRear
 SG_ modes_of_operation_display_6061 m0 : 32|8@1- (1,0) [-128|127] ""  SupportRear
 SG_ SubIndex_6061 m24673M : 24|8@1+ (1,0) [0|0] ""  SupportRear
 SG_ modes_of_operation_6060 m0 : 32|8@1- (1,0) [-128|127] ""  SupportRear
 SG_ SubIndex_6060 m24672M : 24|8@1+ (1,0) [0|0] ""  SupportRear
 SG_ fault_reaction_option_code_605E m0 : 32|16@1- (1,0) [-32768|32767] ""  SupportRear
 SG_ SubIndex_605E m24670M : 24|8@1+ (1,0) [0|0] ""  SupportRear
 SG_ stop_option_code_605D m0 : 32|16@1- (1,0) [-32768|32767] ""  SupportRear
 SG_ SubIndex_605D m24669M : 24|8@1+ (1,0) [0|0] ""  SupportRear
 SG_ disable_operation_option_co_0004 m0 : 32|16@1- (1,0) [-32768|32767] ""  SupportRear
 SG_ SubIndex_605C m24668M : 24|8@1+ (1,0) [0|0] ""  SupportRear
 SG_ shutdown_option_code_605B m0 : 32|16@1- (1,0) [-32768|32767] ""  SupportRear
 SG_ SubIndex_605B m24667M : 24|8@1+ (1,0) [0|0] ""  SupportRear
 SG_ quick_stop_option_code_605A m0 : 32|16@1- (1,0) [-32768|32767] ""  SupportRear
 SG_ SubIndex_605A m24666M : 24|8@1+ (1,0) [0|0] ""  SupportRear
 SG_ delta_time_6049_02 m2 : 32|16@1+ (1,0) [0|65535] ""  SupportRear
 SG_ delta_speed_6049_01 m1 : 32|32@1+ (1,0) [0|4294967295] ""  SupportRear
 SG_ NrOfObjects_6049_00 m0 : 32|8@1+ (1,0) [0|255] ""  SupportRear
 SG_ SubIndex_6049 m24649M : 24|8@1+ (1,0) [0|2] ""  SupportRear
 SG_ delta_time_6048_02 m2 : 32|16@1+ (1,0) [0|65535] ""  SupportRear
 SG_ delta_speed_6048_01 m1 : 32|32@1+ (1,0) [0|4294967295] ""  SupportRear
 SG_ NrOfObjects_6048_00 m0 : 32|8@1+ (1,0) [0|255] ""  SupportRear
 SG_ SubIndex_6048 m24648M : 24|8@1+ (1,0) [0|2] ""  SupportRear
 SG_ vl_velocity_max_amount_6046_02 m2 : 32|32@1+ (1,0) [0|4294967295] ""  SupportRear
 SG_ vl_velocity_min_amount_6046_01 m1 : 32|32@1+ (1,0) [0|4294967295] ""  SupportRear
 SG_ vl_velocity_min_max_amount__0004 m0 : 32|8@1+ (1,0) [0|255] ""  SupportRear
 SG_ SubIndex_6046 m24646M : 24|8@1+ (1,0) [0|2] ""  SupportRear
 SG_ vl_control_effort_6044 m0 : 32|16@1- (1,0) [-32768|32767] ""  SupportRear
 SG_ SubIndex_6044 m24644M : 24|8@1+ (1,0) [0|0] ""  SupportRear
 SG_ vl_velocity_demand_6043 m0 : 32|16@1- (1,0) [-32768|32767] ""  SupportRear
 SG_ SubIndex_6043 m24643M : 24|8@1+ (1,0) [0|0] ""  SupportRear
 SG_ vl_target_velocity_6042 m0 : 32|16@1- (1,0) [-32768|32767] ""  SupportRear
 SG_ SubIndex_6042 m24642M : 24|8@1+ (1,0) [0|0] ""  SupportRear
 SG_ statusword_6041 m0 : 32|16@1+ (1,0) [0|65535] ""  SupportRear
 SG_ SubIndex_6041 m24641M : 24|8@1+ (1,0) [0|0] ""  SupportRear
 SG_ controlword_6040 m0 : 32|16@1+ (1,0) [0|65535] ""  SupportRear
 SG_ SubIndex_6040 m24640M : 24|8@1+ (1,0) [0|0] ""  SupportRear
 SG_ error_code_603F m0 : 32|16@1+ (1,0) [0|65535] ""  SupportRear
 SG_ SubIndex_603F m24639M : 24|8@1+ (1,0) [0|0] ""  SupportRear
 SG_ abort_connection_option_cod_0004 m0 : 32|16@1- (1,0) [-32768|3] ""  SupportRear
 SG_ SubIndex_6007 m24583M : 24|8@1+ (1,0) [0|0] ""  SupportRear
 SG_ NrOfMappedObjects_1A06_00 m0 : 32|8@1+ (1,0) [0|8] ""  SupportRear
 SG_ SubIndex_1A06 m6662M : 24|8@1+ (1,0) [0|0] ""  SupportRear
 SG_ NrOfMappedObjects_1A05_00 m0 : 32|8@1+ (1,0) [0|8] ""  SupportRear
 SG_ SubIndex_1A05 m6661M : 24|8@1+ (1,0) [0|0] ""  SupportRear
 SG_ NrOfMappedObjects_1A04_00 m0 : 32|8@1+ (1,0) [0|8] ""  SupportRear
 SG_ SubIndex_1A04 m6660M : 24|8@1+ (1,0) [0|0] ""  SupportRear
 SG_ NrOfMappedObjects_1A03_00 m0 : 32|8@1+ (1,0) [0|8] ""  SupportRear
 SG_ SubIndex_1A03 m6659M : 24|8@1+ (1,0) [0|0] ""  SupportRear
 SG_ NrOfMappedObjects_1A02_00 m0 : 32|8@1+ (1,0) [0|8] ""  SupportRear
 SG_ SubIndex_1A02 m6658M : 24|8@1+ (1,0) [0|0] ""  SupportRear
 SG_ NrOfMappedObjects_1A01_00 m0 : 32|8@1+ (1,0) [0|8] ""  SupportRear
 SG_ SubIndex_1A01 m6657M : 24|8@1+ (1,0) [0|0] ""  SupportRear
 SG_ mappedObj2_1A00_02 m2 : 32|32@1+ (1,0) [0|4294967295] ""  SupportRear
 SG_ mappedObj1_1A00_01 m1 : 32|32@1+ (1,0) [0|4294967295] ""  SupportRear
 SG_ NrOfMappedObjects_1A00_00 m0 : 32|8@1+ (1,0) [0|8] ""  SupportRear
 SG_ SubIndex_1A00 m6656M : 24|8@1+ (1,0) [0|2] ""  SupportRear
 SG_ EventTimer_1806_05 m5 : 32|16@1+ (1,0) [0|65535] ""  SupportRear
 SG_ TransmissionType_1806_02 m2 : 32|8@1+ (1,0) [0|255] ""  SupportRear
 SG_ COB_ID_1806_01 m1 : 32|32@1+ (1,0) [128|4294967295] ""  SupportRear
 SG_ NrOfEntries_1806_00 m0 : 32|8@1+ (1,0) [2|5] ""  SupportRear
 SG_ SubIndex_1806 m6150M : 24|8@1+ (1,0) [0|5] ""  SupportRear
 SG_ EventTimer_1805_05 m5 : 32|16@1+ (1,0) [0|65535] ""  SupportRear
 SG_ TransmissionType_1805_02 m2 : 32|8@1+ (1,0) [0|255] ""  SupportRear
 SG_ COB_ID_1805_01 m1 : 32|32@1+ (1,0) [128|4294967295] ""  SupportRear
 SG_ NrOfEntries_1805_00 m0 : 32|8@1+ (1,0) [2|5] ""  SupportRear
 SG_ SubIndex_1805 m6149M : 24|8@1+ (1,0) [0|5] ""  SupportRear
 SG_ EventTimer_1804_05 m5 : 32|16@1+ (1,0) [0|65535] ""  SupportRear
 SG_ TransmissionType_1804_02 m2 : 32|8@1+ (1,0) [0|255] ""  SupportRear
 SG_ COB_ID_1804_01 m1 : 32|32@1+ (1,0) [128|4294967295] ""  SupportRear
 SG_ NrOfEntries_1804_00 m0 : 32|8@1+ (1,0) [2|5] ""  SupportRear
 SG_ SubIndex_1804 m6148M : 24|8@1+ (1,0) [0|5] ""  SupportRear
 SG_ EventTimer_1803_05 m5 : 32|16@1+ (1,0) [0|65535] ""  SupportRear
 SG_ TransmissionType_1803_02 m2 : 32|8@1+ (1,0) [0|255] ""  SupportRear
 SG_ COB_ID_1803_01 m1 : 32|32@1+ (1,0) [128|4294967295] ""  SupportRear
 SG_ NrOfEntries_1803_00 m0 : 32|8@1+ (1,0) [2|5] ""  SupportRear
 SG_ SubIndex_1803 m6147M : 24|8@1+ (1,0) [0|5] ""  SupportRear
 SG_ EventTimer_1802_05 m5 : 32|16@1+ (1,0) [0|65535] ""  SupportRear
 SG_ TransmissionType_1802_02 m2 : 32|8@1+ (1,0) [0|255] ""  SupportRear
 SG_ COB_ID_1802_01 m1 : 32|32@1+ (1,0) [128|4294967295] ""  SupportRear
 SG_ NrOfEntries_1802_00 m0 : 32|8@1+ (1,0) [2|5] ""  SupportRear
 SG_ SubIndex_1802 m6146M : 24|8@1+ (1,0) [0|5] ""  SupportRear
 SG_ EventTimer_1801_05 m5 : 32|16@1+ (1,0) [0|65535] ""  SupportRear
 SG_ TransmissionType_1801_02 m2 : 32|8@1+ (1,0) [0|255] ""  SupportRear
 SG_ COB_ID_1801_01 m1 : 32|32@1+ (1,0) [128|4294967295] ""  SupportRear
 SG_ NrOfEntries_1801_00 m0 : 32|8@1+ (1,0) [2|5] ""  SupportRear
 SG_ SubIndex_1801 m6145M : 24|8@1+ (1,0) [0|5] ""  SupportRear
 SG_ EventTimer_1800_05 m5 : 32|16@1+ (1,0) [0|65535] ""  SupportRear
 SG_ TransmissionType_1800_02 m2 : 32|8@1+ (1,0) [0|255] ""  SupportRear
 SG_ COB_ID_1800_01 m1 : 32|32@1+ (1,0) [128|4294967295] ""  SupportRear
 SG_ NrOfEntries_1800_00 m0 : 32|8@1+ (1,0) [2|5] ""  SupportRear
 SG_ SubIndex_1800 m6144M : 24|8@1+ (1,0) [0|5] ""  SupportRear
 SG_ NrOfMappedObjects_1607_00 m0 : 32|8@1+ (1,0) [0|8] ""  SupportRear
 SG_ SubIndex_1607 m5639M : 24|8@1+ (1,0) [0|0] ""  SupportRear
 SG_ NrOfMappedObjects_1606_00 m0 : 32|8@1+ (1,0) [0|8] ""  SupportRear
 SG_ SubIndex_1606 m5638M : 24|8@1+ (1,0) [0|0] ""  SupportRear
 SG_ NrOfMappedObjects_1605_00 m0 : 32|8@1+ (1,0) [0|8] ""  SupportRear
 SG_ SubIndex_1605 m5637M : 24|8@1+ (1,0) [0|0] ""  SupportRear
 SG_ NrOfMappedObjects_1604_00 m0 : 32|8@1+ (1,0) [0|8] ""  SupportRear
 SG_ SubIndex_1604 m5636M : 24|8@1+ (1,0) [0|0] ""  SupportRear
 SG_ NrOfMappedObjects_1603_00 m0 : 32|8@1+ (1,0) [0|8] ""  SupportRear
 SG_ SubIndex_1603 m5635M : 24|8@1+ (1,0) [0|0] ""  SupportRear
 SG_ NrOfMappedObjects_1602_00 m0 : 32|8@1+ (1,0) [0|8] ""  SupportRear
 SG_ SubIndex_1602 m5634M : 24|8@1+ (1,0) [0|0] ""  SupportRear
 SG_ NrOfMappedObjects_1601_00 m0 : 32|8@1+ (1,0) [0|8] ""  SupportRear
 SG_ SubIndex_1601 m5633M : 24|8@1+ (1,0) [0|0] ""  SupportRear
 SG_ mappedObj2_1600_02 m2 : 32|32@1+ (1,0) [0|4294967295] ""  SupportRear
 SG_ mappedObj1_1600_01 m1 : 32|32@1+ (1,0) [0|4294967295] ""  SupportRear
 SG_ NrOfMappedObjects_1600_00 m0 : 32|8@1+ (1,0) [0|8] ""  SupportRear
 SG_ SubIndex_1600 m5632M : 24|8@1+ (1,0) [0|2] ""  SupportRear
 SG_ TransmissionType_1407_02 m2 : 32|8@1+ (1,0) [0|255] ""  SupportRear
 SG_ COB_ID_1407_01 m1 : 32|32@1+ (1,0) [128|4294967295] ""  SupportRear
 SG_ NrOfEntries_1407_00 m0 : 32|8@1+ (1,0) [2|5] ""  SupportRear
 SG_ SubIndex_1407 m5127M : 24|8@1+ (1,0) [0|2] ""  SupportRear
 SG_ TransmissionType_1406_02 m2 : 32|8@1+ (1,0) [0|255] ""  SupportRear
 SG_ COB_ID_1406_01 m1 : 32|32@1+ (1,0) [128|4294967295] ""  SupportRear
 SG_ NrOfEntries_1406_00 m0 : 32|8@1+ (1,0) [2|5] ""  SupportRear
 SG_ SubIndex_1406 m5126M : 24|8@1+ (1,0) [0|2] ""  SupportRear
 SG_ TransmissionType_1405_02 m2 : 32|8@1+ (1,0) [0|255] ""  SupportRear
 SG_ COB_ID_1405_01 m1 : 32|32@1+ (1,0) [128|4294967295] ""  SupportRear
 SG_ NrOfEntries_1405_00 m0 : 32|8@1+ (1,0) [2|5] ""  SupportRear
 SG_ SubIndex_1405 m5125M : 24|8@1+ (1,0) [0|2] ""  SupportRear
 SG_ TransmissionType_1404_02 m2 : 32|8@1+ (1,0) [0|255] ""  SupportRear
 SG_ COB_ID_1404_01 m1 : 32|32@1+ (1,0) [128|4294967295] ""  SupportRear
 SG_ NrOfEntries_1404_00 m0 : 32|8@1+ (1,0) [2|5] ""  SupportRear
 SG_ SubIndex_1404 m5124M : 24|8@1+ (1,0) [0|2] ""  SupportRear
 SG_ TransmissionType_1403_02 m2 : 32|8@1+ (1,0) [0|255] ""  SupportRear
 SG_ COB_ID_1403_01 m1 : 32|32@1+ (1,0) [128|4294967295] ""  SupportRear
 SG_ NrOfEntries_1403_00 m0 : 32|8@1+ (1,0) [2|5] ""  SupportRear
 SG_ SubIndex_1403 m5123M : 24|8@1+ (1,0) [0|2] ""  SupportRear
 SG_ TransmissionType_1402_02 m2 : 32|8@1+ (1,0) [0|255] ""  SupportRear
 SG_ COB_ID_1402_01 m1 : 32|32@1+ (1,0) [128|4294967295] ""  SupportRear
 SG_ NrOfEntries_1402_00 m0 : 32|8@1+ (1,0) [2|5] ""  SupportRear
 SG_ SubIndex_1402 m5122M : 24|8@1+ (1,0) [0|2] ""  SupportRear
 SG_ TransmissionType_1401_02 m2 : 32|8@1+ (1,0) [0|255] ""  SupportRear
 SG_ COB_ID_1401_01 m1 : 32|32@1+ (1,0) [128|4294967295] ""  SupportRear
 SG_ NrOfEntries_1401_00 m0 : 32|8@1+ (1,0) [2|5] ""  SupportRear
 SG_ SubIndex_1401 m5121M : 24|8@1+ (1,0) [0|2] ""  SupportRear
 SG_ TransmissionType_1400_02 m2 : 32|8@1+ (1,0) [0|255] ""  SupportRear
 SG_ COB_ID_1400_01 m1 : 32|32@1+ (1,0) [128|4294967295] ""  SupportRear
 SG_ NrOfEntries_1400_00 m0 : 32|8@1+ (1,0) [2|5] ""  SupportRear
 SG_ SubIndex_1400 m5120M : 24|8@1+ (1,0) [0|2] ""  SupportRear
 SG_ Serial_number_1018_04 m4 : 32|32@1+ (1,0) [0|4294967295] ""  SupportRear
 SG_ Revision_number_1018_03 m3 : 32|32@1+ (1,0) [0|4294967295] ""  SupportRear
 SG_ Product_Code_1018_02 m2 : 32|32@1+ (1,0) [0|4294967295] ""  SupportRear
 SG_ Vendor_Id_1018_01 m1 : 32|32@1+ (1,0) [0|4294967295] ""  SupportRear
 SG_ number_of_entries_1018_00 m0 : 32|8@1+ (1,0) [1|4] ""  SupportRear
 SG_ SubIndex_1018 m4120M : 24|8@1+ (1,0) [0|4] ""  SupportRear
 SG_ Producer_Heartbeat_Time_1017 m0 : 32|16@1+ (1,0) [0|65535] ""  SupportRear
 SG_ SubIndex_1017 m4119M : 24|8@1+ (1,0) [0|0] ""  SupportRear
 SG_ Consumer_Heartbeat_Time126__0000 m126 : 32|32@1+ (1,0) [0|4294967295] ""  SupportRear
 SG_ Consumer_Heartbeat_Time125__0000 m125 : 32|32@1+ (1,0) [0|4294967295] ""  SupportRear
 SG_ Consumer_Heartbeat_Time124__0000 m124 : 32|32@1+ (1,0) [0|4294967295] ""  SupportRear
 SG_ Consumer_Heartbeat_Time123__0000 m123 : 32|32@1+ (1,0) [0|4294967295] ""  SupportRear
 SG_ Consumer_Heartbeat_Time122__0000 m122 : 32|32@1+ (1,0) [0|4294967295] ""  SupportRear
 SG_ Consumer_Heartbeat_Time121__0000 m121 : 32|32@1+ (1,0) [0|4294967295] ""  SupportRear
 SG_ Consumer_Heartbeat_Time120__0000 m120 : 32|32@1+ (1,0) [0|4294967295] ""  SupportRear
 SG_ Consumer_Heartbeat_Time119__0000 m119 : 32|32@1+ (1,0) [0|4294967295] ""  SupportRear
 SG_ Consumer_Heartbeat_Time118__0000 m118 : 32|32@1+ (1,0) [0|4294967295] ""  SupportRear
 SG_ Consumer_Heartbeat_Time117__0000 m117 : 32|32@1+ (1,0) [0|4294967295] ""  SupportRear
 SG_ Consumer_Heartbeat_Time116__0000 m116 : 32|32@1+ (1,0) [0|4294967295] ""  SupportRear
 SG_ Consumer_Heartbeat_Time115__0000 m115 : 32|32@1+ (1,0) [0|4294967295] ""  SupportRear
 SG_ Consumer_Heartbeat_Time114__0000 m114 : 32|32@1+ (1,0) [0|4294967295] ""  SupportRear
 SG_ Consumer_Heartbeat_Time113__0000 m113 : 32|32@1+ (1,0) [0|4294967295] ""  SupportRear
 SG_ Consumer_Heartbeat_Time112__0000 m112 : 32|32@1+ (1,0) [0|4294967295] ""  SupportRear
 SG_ Consumer_Heartbeat_Time111__0000 m111 : 32|32@1+ (1,0) [0|4294967295] ""  SupportRear
 SG_ Consumer_Heartbeat_Time110__0000 m110 : 32|32@1+ (1,0) [0|4294967295] ""  SupportRear
 SG_ Consumer_Heartbeat_Time109__0000 m109 : 32|32@1+ (1,0) [0|4294967295] ""  SupportRear
 SG_ Consumer_Heartbeat_Time108__0000 m108 : 32|32@1+ (1,0) [0|4294967295] ""  SupportRear
 SG_ Consumer_Heartbeat_Time107__0000 m107 : 32|32@1+ (1,0) [0|4294967295] ""  SupportRear
 SG_ Consumer_Heartbeat_Time106__0000 m106 : 32|32@1+ (1,0) [0|4294967295] ""  SupportRear
 SG_ Consumer_Heartbeat_Time105__0000 m105 : 32|32@1+ (1,0) [0|4294967295] ""  SupportRear
 SG_ Consumer_Heartbeat_Time104__0000 m104 : 32|32@1+ (1,0) [0|4294967295] ""  SupportRear
 SG_ Consumer_Heartbeat_Time103__0000 m103 : 32|32@1+ (1,0) [0|4294967295] ""  SupportRear
 SG_ Consumer_Heartbeat_Time102__0000 m102 : 32|32@1+ (1,0) [0|4294967295] ""  SupportRear
 SG_ Consumer_Heartbeat_Time101__0000 m101 : 32|32@1+ (1,0) [0|4294967295] ""  SupportRear
 SG_ Consumer_Heartbeat_Time100__0000 m100 : 32|32@1+ (1,0) [0|4294967295] ""  SupportRear
 SG_ Consumer_Heartbeat_Time99_1_0000 m99 : 32|32@1+ (1,0) [0|4294967295] ""  SupportRear
 SG_ Consumer_Heartbeat_Time98_1_0000 m98 : 32|32@1+ (1,0) [0|4294967295] ""  SupportRear
 SG_ Consumer_Heartbeat_Time97_1_0000 m97 : 32|32@1+ (1,0) [0|4294967295] ""  SupportRear
 SG_ Consumer_Heartbeat_Time96_1_0000 m96 : 32|32@1+ (1,0) [0|4294967295] ""  SupportRear
 SG_ Consumer_Heartbeat_Time95_1_0000 m95 : 32|32@1+ (1,0) [0|4294967295] ""  SupportRear
 SG_ Consumer_Heartbeat_Time94_1_0000 m94 : 32|32@1+ (1,0) [0|4294967295] ""  SupportRear
 SG_ Consumer_Heartbeat_Time93_1_0000 m93 : 32|32@1+ (1,0) [0|4294967295] ""  SupportRear
 SG_ Consumer_Heartbeat_Time92_1_0000 m92 : 32|32@1+ (1,0) [0|4294967295] ""  SupportRear
 SG_ Consumer_Heartbeat_Time91_1_0000 m91 : 32|32@1+ (1,0) [0|4294967295] ""  SupportRear
 SG_ Consumer_Heartbeat_Time90_1_0000 m90 : 32|32@1+ (1,0) [0|4294967295] ""  SupportRear
 SG_ Consumer_Heartbeat_Time89_1_0000 m89 : 32|32@1+ (1,0) [0|4294967295] ""  SupportRear
 SG_ Consumer_Heartbeat_Time88_1_0000 m88 : 32|32@1+ (1,0) [0|4294967295] ""  SupportRear
 SG_ Consumer_Heartbeat_Time87_1_0000 m87 : 32|32@1+ (1,0) [0|4294967295] ""  SupportRear
 SG_ Consumer_Heartbeat_Time86_1_0000 m86 : 32|32@1+ (1,0) [0|4294967295] ""  SupportRear
 SG_ Consumer_Heartbeat_Time85_1_0000 m85 : 32|32@1+ (1,0) [0|4294967295] ""  SupportRear
 SG_ Consumer_Heartbeat_Time84_1_0000 m84 : 32|32@1+ (1,0) [0|4294967295] ""  SupportRear
 SG_ Consumer_Heartbeat_Time83_1_0000 m83 : 32|32@1+ (1,0) [0|4294967295] ""  SupportRear
 SG_ Consumer_Heartbeat_Time82_1_0000 m82 : 32|32@1+ (1,0) [0|4294967295] ""  SupportRear
 SG_ Consumer_Heartbeat_Time81_1_0000 m81 : 32|32@1+ (1,0) [0|4294967295] ""  SupportRear
 SG_ Consumer_Heartbeat_Time80_1_0000 m80 : 32|32@1+ (1,0) [0|4294967295] ""  SupportRear
 SG_ Consumer_Heartbeat_Time79_1_0000 m79 : 32|32@1+ (1,0) [0|4294967295] ""  SupportRear
 SG_ Consumer_Heartbeat_Time78_1_0000 m78 : 32|32@1+ (1,0) [0|4294967295] ""  SupportRear
 SG_ Consumer_Heartbeat_Time77_1_0000 m77 : 32|32@1+ (1,0) [0|4294967295] ""  SupportRear
 SG_ Consumer_Heartbeat_Time76_1_0000 m76 : 32|32@1+ (1,0) [0|4294967295] ""  SupportRear
 SG_ Consumer_Heartbeat_Time75_1_0000 m75 : 32|32@1+ (1,0) [0|4294967295] ""  SupportRear
 SG_ Consumer_Heartbeat_Time74_1_0000 m74 : 32|32@1+ (1,0) [0|4294967295] ""  SupportRear
 SG_ Consumer_Heartbeat_Time73_1_0000 m73 : 32|32@1+ (1,0) [0|4294967295] ""  SupportRear
 SG_ Consumer_Heartbeat_Time72_1_0000 m72 : 32|32@1+ (1,0) [0|4294967295] ""  SupportRear
 SG_ Consumer_Heartbeat_Time71_1_0000 m71 : 32|32@1+ (1,0) [0|4294967295] ""  SupportRear
 SG_ Consumer_Heartbeat_Time70_1_0000 m70 : 32|32@1+ (1,0) [0|4294967295] ""  SupportRear
 SG_ Consumer_Heartbeat_Time69_1_0000 m69 : 32|32@1+ (1,0) [0|4294967295] ""  SupportRear
 SG_ Consumer_Heartbeat_Time68_1_0000 m68 : 32|32@1+ (1,0) [0|4294967295] ""  SupportRear
 SG_ Consumer_Heartbeat_Time67_1_0000 m67 : 32|32@1+ (1,0) [0|4294967295] ""  SupportRear
 SG_ Consumer_Heartbeat_Time66_1_0000 m66 : 32|32@1+ (1,0) [0|4294967295] ""  SupportRear
 SG_ Consumer_Heartbeat_Time65_1_0000 m65 : 32|32@1+ (1,0) [0|4294967295] ""  SupportRear
 SG_ Consumer_Heartbeat_Time64_1_0000 m64 : 32|32@1+ (1,0) [0|4294967295] ""  SupportRear
 SG_ Consumer_Heartbeat_Time63_1_0000 m63 : 32|32@1+ (1,0) [0|4294967295] ""  SupportRear
 SG_ Consumer_Heartbeat_Time62_1_0000 m62 : 32|32@1+ (1,0) [0|4294967295] ""  SupportRear
 SG_ Consumer_Heartbeat_Time61_1_0000 m61 : 32|32@1+ (1,0) [0|4294967295] ""  SupportRear
 SG_ Consumer_Heartbeat_Time60_1_0000 m60 : 32|32@1+ (1,0) [0|4294967295] ""  SupportRear
 SG_ Consumer_Heartbeat_Time59_1_0000 m59 : 32|32@1+ (1,0) [0|4294967295] ""  SupportRear
 SG_ Consumer_Heartbeat_Time58_1_0000 m58 : 32|32@1+ (1,0) [0|4294967295] ""  SupportRear
 SG_ Consumer_Heartbeat_Time57_1_0000 m57 : 32|32@1+ (1,0) [0|4294967295] ""  SupportRear
 SG_ Consumer_Heartbeat_Time56_1_0000 m56 : 32|32@1+ (1,0) [0|4294967295] ""  SupportRear
 SG_ Consumer_Heartbeat_Time55_1_0000 m55 : 32|32@1+ (1,0) [0|4294967295] ""  SupportRear
 SG_ Consumer_Heartbeat_Time54_1_0000 m54 : 32|32@1+ (1,0) [0|4294967295] ""  SupportRear
 SG_ Consumer_Heartbeat_Time53_1_0000 m53 : 32|32@1+ (1,0) [0|4294967295] ""  SupportRear
 SG_ Consumer_Heartbeat_Time52_1_0000 m52 : 32|32@1+ (1,0) [0|4294967295] ""  SupportRear
 SG_ Consumer_Heartbeat_Time51_1_0000 m51 : 32|32@1+ (1,0) [0|4294967295] ""  SupportRear
 SG_ Consumer_Heartbeat_Time50_1_0000 m50 : 32|32@1+ (1,0) [0|4294967295] ""  SupportRear
 SG_ Consumer_Heartbeat_Time49_1_0000 m49 : 32|32@1+ (1,0) [0|4294967295] ""  SupportRear
 SG_ Consumer_Heartbeat_Time48_1_0000 m48 : 32|32@1+ (1,0) [0|4294967295] ""  SupportRear
 SG_ Consumer_Heartbeat_Time47_1_0000 m47 : 32|32@1+ (1,0) [0|4294967295] ""  SupportRear
 SG_ Consumer_Heartbeat_Time46_1_0000 m46 : 32|32@1+ (1,0) [0|4294967295] ""  SupportRear
 SG_ Consumer_Heartbeat_Time45_1_0000 m45 : 32|32@1+ (1,0) [0|4294967295] ""  SupportRear
 SG_ Consumer_Heartbeat_Time44_1_0000 m44 : 32|32@1+ (1,0) [0|4294967295] ""  SupportRear
 SG_ Consumer_Heartbeat_Time43_1_0000 m43 : 32|32@1+ (1,0) [0|4294967295] ""  SupportRear
 SG_ Consumer_Heartbeat_Time42_1_0000 m42 : 32|32@1+ (1,0) [0|4294967295] ""  SupportRear
 SG_ Consumer_Heartbeat_Time41_1_0000 m41 : 32|32@1+ (1,0) [0|4294967295] ""  SupportRear
 SG_ Consumer_Heartbeat_Time40_1_0000 m40 : 32|32@1+ (1,0) [0|4294967295] ""  SupportRear
 SG_ Consumer_Heartbeat_Time39_1_0000 m39 : 32|32@1+ (1,0) [0|4294967295] ""  SupportRear
 SG_ Consumer_Heartbeat_Time38_1_0000 m38 : 32|32@1+ (1,0) [0|4294967295] ""  SupportRear
 SG_ Consumer_Heartbeat_Time37_1_0000 m37 : 32|32@1+ (1,0) [0|4294967295] ""  SupportRear
 SG_ Consumer_Heartbeat_Time36_1_0000 m36 : 32|32@1+ (1,0) [0|4294967295] ""  SupportRear
 SG_ Consumer_Heartbeat_Time35_1_0000 m35 : 32|32@1+ (1,0) [0|4294967295] ""  SupportRear
 SG_ Consumer_Heartbeat_Time34_1_0000 m34 : 32|32@1+ (1,0) [0|4294967295] ""  SupportRear
 SG_ Consumer_Heartbeat_Time33_1_0000 m33 : 32|32@1+ (1,0) [0|4294967295] ""  SupportRear
 SG_ Consumer_Heartbeat_Time32_1_0000 m32 : 32|32@1+ (1,0) [0|4294967295] ""  SupportRear
 SG_ Consumer_Heartbeat_Time31_1_0000 m31 : 32|32@1+ (1,0) [0|4294967295] ""  SupportRear
 SG_ Consumer_Heartbeat_Time30_1_0000 m30 : 32|32@1+ (1,0) [0|4294967295] ""  SupportRear
 SG_ Consumer_Heartbeat_Time29_1_0000 m29 : 32|32@1+ (1,0) [0|4294967295] ""  SupportRear
 SG_ Consumer_Heartbeat_Time28_1_0000 m28 : 32|32@1+ (1,0) [0|4294967295] ""  SupportRear
 SG_ Consumer_Heartbeat_Time27_1_0000 m27 : 32|32@1+ (1,0) [0|4294967295] ""  SupportRear
 SG_ Consumer_Heartbeat_Time26_1_0000 m26 : 32|32@1+ (1,0) [0|4294967295] ""  SupportRear
 SG_ Consumer_Heartbeat_Time25_1_0000 m25 : 32|32@1+ (1,0) [0|4294967295] ""  SupportRear
 SG_ Consumer_Heartbeat_Time24_1_0000 m24 : 32|32@1+ (1,0) [0|4294967295] ""  SupportRear
 SG_ Consumer_Heartbeat_Time23_1_0000 m23 : 32|32@1+ (1,0) [0|4294967295] ""  SupportRear
 SG_ Consumer_Heartbeat_Time22_1_0000 m22 : 32|32@1+ (1,0) [0|4294967295] ""  SupportRear
 SG_ Consumer_Heartbeat_Time21_1_0000 m21 : 32|32@1+ (1,0) [0|4294967295] ""  SupportRear
 SG_ Consumer_Heartbeat_Time20_1_0000 m20 : 32|32@1+ (1,0) [0|4294967295] ""  SupportRear
 SG_ Consumer_Heartbeat_Time19_1_0000 m19 : 32|32@1+ (1,0) [0|4294967295] ""  SupportRear
 SG_ Consumer_Heartbeat_Time18_1_0000 m18 : 32|32@1+ (1,0) [0|4294967295] ""  SupportRear
 SG_ Consumer_Heartbeat_Time17_1_0000 m17 : 32|32@1+ (1,0) [0|4294967295] ""  SupportRear
 SG_ Consumer_Heartbeat_Time16_1_0000 m16 : 32|32@1+ (1,0) [0|4294967295] ""  SupportRear
 SG_ Consumer_Heartbeat_Time15_1_0000 m15 : 32|32@1+ (1,0) [0|4294967295] ""  SupportRear
 SG_ Consumer_Heartbeat_Time14_1_0000 m14 : 32|32@1+ (1,0) [0|4294967295] ""  SupportRear
 SG_ Consumer_Heartbeat_Time13_1_0000 m13 : 32|32@1+ (1,0) [0|4294967295] ""  SupportRear
 SG_ Consumer_Heartbeat_Time12_1_0000 m12 : 32|32@1+ (1,0) [0|4294967295] ""  SupportRear
 SG_ Consumer_Heartbeat_Time11_1_0000 m11 : 32|32@1+ (1,0) [0|4294967295] ""  SupportRear
 SG_ Consumer_Heartbeat_Time10_1_0000 m10 : 32|32@1+ (1,0) [0|4294967295] ""  SupportRear
 SG_ Consumer_Heartbeat_Time_1016_09 m9 : 32|32@1+ (1,0) [0|4294967295] ""  SupportRear
 SG_ Consumer_Heartbeat_Time_1016_08 m8 : 32|32@1+ (1,0) [0|4294967295] ""  SupportRear
 SG_ Consumer_Heartbeat_Time_1016_07 m7 : 32|32@1+ (1,0) [0|4294967295] ""  SupportRear
 SG_ Consumer_Heartbeat_Time_1016_06 m6 : 32|32@1+ (1,0) [0|4294967295] ""  SupportRear
 SG_ Consumer_Heartbeat_Time_1016_05 m5 : 32|32@1+ (1,0) [0|4294967295] ""  SupportRear
 SG_ Consumer_Heartbeat_Time_1016_04 m4 : 32|32@1+ (1,0) [0|4294967295] ""  SupportRear
 SG_ Consumer_Heartbeat_Time_1016_03 m3 : 32|32@1+ (1,0) [0|4294967295] ""  SupportRear
 SG_ Consumer_Heartbeat_Time_1016_02 m2 : 32|32@1+ (1,0) [0|4294967295] ""  SupportRear
 SG_ Consumer_Heartbeat_Time_1016_01 m1 : 32|32@1+ (1,0) [0|4294967295] ""  SupportRear
 SG_ NrOfObjects_1016_00 m0 : 32|8@1+ (1,0) [0|255] ""  SupportRear
 SG_ SubIndex_1016 m4118M : 24|8@1+ (1,0) [0|126] ""  SupportRear
 SG_ Save_all_Parameters_1010_01 m1 : 32|32@1+ (1,0) [0|4294967295] ""  SupportRear
 SG_ Number_of_Entries_1010_00 m0 : 32|8@1+ (1,0) [0|255] ""  SupportRear
 SG_ SubIndex_1010 m4112M : 24|8@1+ (1,0) [0|1] ""  SupportRear
 SG_ Life_Time_Factor_100D m0 : 32|8@1+ (1,0) [0|255] ""  SupportRear
 SG_ SubIndex_100D m4109M : 24|8@1+ (1,0) [0|0] ""  SupportRear
 SG_ Guard_Time_100C m0 : 32|16@1+ (1,0) [0|65535] ""  SupportRear
 SG_ SubIndex_100C m4108M : 24|8@1+ (1,0) [0|0] ""  SupportRear
 SG_ Sync_Window_Length_1007 m0 : 32|32@1+ (1,0) [0|4294967295] ""  SupportRear
 SG_ SubIndex_1007 m4103M : 24|8@1+ (1,0) [0|0] ""  SupportRear
 SG_ Communication_Cycle_Period_1006 m0 : 32|32@1+ (1,0) [0|4294967295] ""  SupportRear
 SG_ SubIndex_1006 m4102M : 24|8@1+ (1,0) [0|0] ""  SupportRear
 SG_ COB_ID_SYNC_1005 m0 : 32|32@1+ (1,0) [128|4294967295] ""  SupportRear
 SG_ SubIndex_1005 m4101M : 24|8@1+ (1,0) [0|0] ""  SupportRear
 SG_ Manufacturer_Status_Registe_0008 m0 : 32|32@1+ (1,0) [0|4294967295] ""  SupportRear
 SG_ SubIndex_1002 m4098M : 24|8@1+ (1,0) [0|0] ""  SupportRear
 SG_ Error_Register_1001 m0 : 32|8@1+ (1,0) [0|255] ""  SupportRear
 SG_ SubIndex_1001 m4097M : 24|8@1+ (1,0) [0|0] ""  SupportRear
 SG_ Device_Type_1000 m0 : 32|32@1+ (1,0) [0|4294967295] ""  SupportRear
 SG_ SubIndex_1000 m4096M : 24|8@1+ (1,0) [0|0] ""  SupportRear
 SG_ Index m1M : 8|16@1+ (1,0) [4096|25861] ""  SupportRear
 SG_ TransferType m1M : 1|1@1+ (1,0) [0|1] ""  SupportRear
 SG_ NotUsedBytes m1 : 2|2@1+ (1,0) [0|3] ""  SupportRear
 SG_ SizeIndicator m1 : 0|1@1+ (1,0) [0|1] ""  SupportRear
 SG_ CCS M : 5|3@1+ (1,0) [0|6] ""  SupportRear

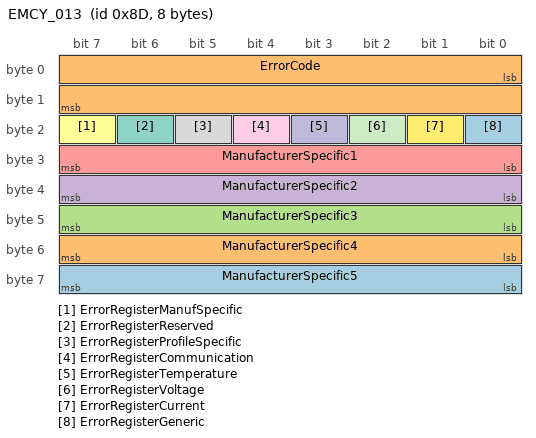
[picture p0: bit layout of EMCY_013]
BO_ 141 EMCY_013: 8 SupportRear
 SG_ ManufacturerSpecific5 : 56|8@1+ (1,0) [0|0] "" Vector__XXX
 SG_ ManufacturerSpecific4 : 48|8@1+ (1,0) [0|0] "" Vector__XXX
 SG_ ManufacturerSpecific3 : 40|8@1+ (1,0) [0|0] "" Vector__XXX
 SG_ ManufacturerSpecific2 : 32|8@1+ (1,0) [0|0] "" Vector__XXX
 SG_ ManufacturerSpecific1 : 24|8@1+ (1,0) [0|0] "" Vector__XXX
 SG_ ErrorRegisterManufSpecific : 23|1@1+ (1,0) [0|0] "" Vector__XXX
 SG_ ErrorRegisterReserved : 22|1@1+ (1,0) [0|0] "" Vector__XXX
 SG_ ErrorRegisterProfileSpecific : 21|1@1+ (1,0) [0|0] "" Vector__XXX
 SG_ ErrorRegisterCommunication : 20|1@1+ (1,0) [0|0] "" Vector__XXX
 SG_ ErrorRegisterTemperature : 19|1@1+ (1,0) [0|0] "" Vector__XXX
 SG_ ErrorRegisterVoltage : 18|1@1+ (1,0) [0|0] "" Vector__XXX
 SG_ ErrorRegisterCurrent : 17|1@1+ (1,0) [0|0] "" Vector__XXX
 SG_ ErrorRegisterGeneric : 16|1@1+ (1,0) [0|0] "" Vector__XXX
 SG_ ErrorCode : 0|16@1+ (1,0) [0|0] "" Vector__XXX

BO_ 1794 HBGuard_002: 1 TTGateway
 SG_ Toggle : 7|1@1+ (1,0) [0|0] "" Vector__XXX
 SG_ State : 0|7@1+ (1,0) [0|0] "" Vector__XXX

BA_DEF_ BO_  "GenMsgSendType" ENUM  "Cyclic","SendType1","SendType2","SendType3","SendType4","SendType5","SendType6","SendType7","SendType8","SendType9";
BA_DEF_ BO_  "GenMsgCycleTime" INT 0 0;
BA_DEF_ SG_  "GenSigStartValue" INT 0 0;
BA_DEF_ BO_  "CO_MsgCategory" INT 0 0;
BA_DEF_ SG_  "SystemSignalLongSymbol" STRING ;
BA_DEF_DEF_  "GenMsgSendType" "";
BA_DEF_DEF_  "GenMsgCycleTime" 0;
BA_DEF_DEF_  "GenSigStartValue" 0;
BA_DEF_DEF_  "CO_MsgCategory" 0;
BA_DEF_DEF_  "SystemSignalLongSymbol" "";
BA_ "CO_MsgCategory" BO_ 1421 410;
BA_ "CO_MsgCategory" BO_ 1549 405;
BA_ "CO_MsgCategory" BO_ 141 205;
BA_ "CO_MsgCategory" BO_ 1794 505;
BA_ "GenSigStartValue" SG_ 1421 supported_drive_modes_6502 2;
BA_ "GenSigStartValue" SG_ 1421 motor_service_period_6407 1000;
BA_ "GenSigStartValue" SG_ 1421 NrOfObjects_60FE_00 2;
BA_ "SystemSignalLongSymbol" SG_ 1421 disable_operation_option_co_0003 "disable_operation_option_code_605C";
BA_ "GenSigStartValue" SG_ 1421 delta_time_6049_02 1;
BA_ "GenSigStartValue" SG_ 1421 delta_speed_6049_01 1000;
BA_ "GenSigStartValue" SG_ 1421 NrOfObjects_6049_00 2;
BA_ "GenSigStartValue" SG_ 1421 delta_time_6048_02 1;
BA_ "GenSigStartValue" SG_ 1421 delta_speed_6048_01 500;
BA_ "GenSigStartValue" SG_ 1421 NrOfObjects_6048_00 2;
BA_ "GenSigStartValue" SG_ 1421 vl_velocity_max_amount_6046_02 1000;
BA_ "GenSigStartValue" SG_ 1421 vl_velocity_min_max_amount__0003 2;
BA_ "SystemSignalLongSymbol" SG_ 1421 vl_velocity_min_max_amount__0003 "vl_velocity_min_max_amount_highest_subindex_6046_00";
BA_ "SystemSignalLongSymbol" SG_ 1421 abort_connection_option_cod_0003 "abort_connection_option_code_6007";
BA_ "GenSigStartValue" SG_ 1421 mappedObj2_1A00_02 1615003664;
BA_ "GenSigStartValue" SG_ 1421 mappedObj1_1A00_01 1614872592;
BA_ "GenSigStartValue" SG_ 1421 NrOfMappedObjects_1A00_00 2;
BA_ "GenSigStartValue" SG_ 1421 TransmissionType_1806_02 255;
BA_ "GenSigStartValue" SG_ 1421 COB_ID_1806_01 2147484959;
BA_ "GenSigStartValue" SG_ 1421 NrOfEntries_1806_00 5;
BA_ "GenSigStartValue" SG_ 1421 TransmissionType_1805_02 255;
BA_ "GenSigStartValue" SG_ 1421 COB_ID_1805_01 2147484960;
BA_ "GenSigStartValue" SG_ 1421 NrOfEntries_1805_00 5;
BA_ "GenSigStartValue" SG_ 1421 TransmissionType_1804_02 255;
BA_ "GenSigStartValue" SG_ 1421 COB_ID_1804_01 2147484961;
BA_ "GenSigStartValue" SG_ 1421 NrOfEntries_1804_00 5;
BA_ "GenSigStartValue" SG_ 1421 TransmissionType_1803_02 255;
BA_ "GenSigStartValue" SG_ 1421 COB_ID_1803_01 2147484813;
BA_ "GenSigStartValue" SG_ 1421 NrOfEntries_1803_00 5;
BA_ "GenSigStartValue" SG_ 1421 TransmissionType_1802_02 255;
BA_ "GenSigStartValue" SG_ 1421 COB_ID_1802_01 2147484557;
BA_ "GenSigStartValue" SG_ 1421 NrOfEntries_1802_00 5;
BA_ "GenSigStartValue" SG_ 1421 TransmissionType_1801_02 255;
BA_ "GenSigStartValue" SG_ 1421 COB_ID_1801_01 2147484301;
BA_ "GenSigStartValue" SG_ 1421 NrOfEntries_1801_00 5;
BA_ "GenSigStartValue" SG_ 1421 TransmissionType_1800_02 255;
BA_ "GenSigStartValue" SG_ 1421 COB_ID_1800_01 1281;
BA_ "GenSigStartValue" SG_ 1421 NrOfEntries_1800_00 5;
BA_ "GenSigStartValue" SG_ 1421 mappedObj2_1600_02 1614807056;
BA_ "GenSigStartValue" SG_ 1421 mappedObj1_1600_01 1614938128;
BA_ "GenSigStartValue" SG_ 1421 NrOfMappedObjects_1600_00 2;
BA_ "GenSigStartValue" SG_ 1421 TransmissionType_1407_02 255;
BA_ "GenSigStartValue" SG_ 1421 COB_ID_1407_01 2147484955;
BA_ "GenSigStartValue" SG_ 1421 NrOfEntries_1407_00 2;
BA_ "GenSigStartValue" SG_ 1421 TransmissionType_1406_02 255;
BA_ "GenSigStartValue" SG_ 1421 COB_ID_1406_01 2147484956;
BA_ "GenSigStartValue" SG_ 1421 NrOfEntries_1406_00 2;
BA_ "GenSigStartValue" SG_ 1421 TransmissionType_1405_02 255;
BA_ "GenSigStartValue" SG_ 1421 COB_ID_1405_01 2147484957;
BA_ "GenSigStartValue" SG_ 1421 NrOfEntries_1405_00 2;
BA_ "GenSigStartValue" SG_ 1421 TransmissionType_1404_02 255;
BA_ "GenSigStartValue" SG_ 1421 COB_ID_1404_01 2147484958;
BA_ "GenSigStartValue" SG_ 1421 NrOfEntries_1404_00 2;
BA_ "GenSigStartValue" SG_ 1421 TransmissionType_1403_02 255;
BA_ "GenSigStartValue" SG_ 1421 COB_ID_1403_01 2147484941;
BA_ "GenSigStartValue" SG_ 1421 NrOfEntries_1403_00 2;
BA_ "GenSigStartValue" SG_ 1421 TransmissionType_1402_02 255;
BA_ "GenSigStartValue" SG_ 1421 COB_ID_1402_01 2147484685;
BA_ "GenSigStartValue" SG_ 1421 NrOfEntries_1402_00 2;
BA_ "GenSigStartValue" SG_ 1421 TransmissionType_1401_02 255;
BA_ "GenSigStartValue" SG_ 1421 COB_ID_1401_01 2147484429;
BA_ "GenSigStartValue" SG_ 1421 NrOfEntries_1401_00 2;
BA_ "GenSigStartValue" SG_ 1421 TransmissionType_1400_02 255;
BA_ "GenSigStartValue" SG_ 1421 COB_ID_1400_01 897;
BA_ "GenSigStartValue" SG_ 1421 NrOfEntries_1400_00 2;
BA_ "GenSigStartValue" SG_ 1421 Serial_number_1018_04 1;
BA_ "GenSigStartValue" SG_ 1421 Revision_number_1018_03 1;
BA_ "GenSigStartValue" SG_ 1421 Product_Code_1018_02 1565;
BA_ "GenSigStartValue" SG_ 1421 Vendor_Id_1018_01 5;
BA_ "GenSigStartValue" SG_ 1421 number_of_entries_1018_00 4;
BA_ "GenSigStartValue" SG_ 1421 Producer_Heartbeat_Time_1017 1000;
BA_ "SystemSignalLongSymbol" SG_ 1421 Consumer_Heartbeat_Time126_1016_ "Consumer_Heartbeat_Time126_1016_7E";
BA_ "SystemSignalLongSymbol" SG_ 1421 Consumer_Heartbeat_Time125_1016_ "Consumer_Heartbeat_Time125_1016_7D";
BA_ "SystemSignalLongSymbol" SG_ 1421 Consumer_Heartbeat_Time124_1016_ "Consumer_Heartbeat_Time124_1016_7C";
BA_ "SystemSignalLongSymbol" SG_ 1421 Consumer_Heartbeat_Time123_1016_ "Consumer_Heartbeat_Time123_1016_7B";
BA_ "SystemSignalLongSymbol" SG_ 1421 Consumer_Heartbeat_Time122_1016_ "Consumer_Heartbeat_Time122_1016_7A";
BA_ "SystemSignalLongSymbol" SG_ 1421 Consumer_Heartbeat_Time121_1016_ "Consumer_Heartbeat_Time121_1016_79";
BA_ "SystemSignalLongSymbol" SG_ 1421 Consumer_Heartbeat_Time120_1016_ "Consumer_Heartbeat_Time120_1016_78";
BA_ "SystemSignalLongSymbol" SG_ 1421 Consumer_Heartbeat_Time119_1016_ "Consumer_Heartbeat_Time119_1016_77";
BA_ "SystemSignalLongSymbol" SG_ 1421 Consumer_Heartbeat_Time118_1016_ "Consumer_Heartbeat_Time118_1016_76";
BA_ "SystemSignalLongSymbol" SG_ 1421 Consumer_Heartbeat_Time117_1016_ "Consumer_Heartbeat_Time117_1016_75";
BA_ "SystemSignalLongSymbol" SG_ 1421 Consumer_Heartbeat_Time116_1016_ "Consumer_Heartbeat_Time116_1016_74";
BA_ "SystemSignalLongSymbol" SG_ 1421 Consumer_Heartbeat_Time115_1016_ "Consumer_Heartbeat_Time115_1016_73";
BA_ "SystemSignalLongSymbol" SG_ 1421 Consumer_Heartbeat_Time114_1016_ "Consumer_Heartbeat_Time114_1016_72";
BA_ "SystemSignalLongSymbol" SG_ 1421 Consumer_Heartbeat_Time113_1016_ "Consumer_Heartbeat_Time113_1016_71";
BA_ "SystemSignalLongSymbol" SG_ 1421 Consumer_Heartbeat_Time112_1016_ "Consumer_Heartbeat_Time112_1016_70";
BA_ "SystemSignalLongSymbol" SG_ 1421 Consumer_Heartbeat_Time111_1016_ "Consumer_Heartbeat_Time111_1016_6F";
BA_ "SystemSignalLongSymbol" SG_ 1421 Consumer_Heartbeat_Time110_1016_ "Consumer_Heartbeat_Time110_1016_6E";
BA_ "SystemSignalLongSymbol" SG_ 1421 Consumer_Heartbeat_Time109_1016_ "Consumer_Heartbeat_Time109_1016_6D";
BA_ "SystemSignalLongSymbol" SG_ 1421 Consumer_Heartbeat_Time108_1016_ "Consumer_Heartbeat_Time108_1016_6C";
BA_ "SystemSignalLongSymbol" SG_ 1421 Consumer_Heartbeat_Time107_1016_ "Consumer_Heartbeat_Time107_1016_6B";
BA_ "SystemSignalLongSymbol" SG_ 1421 Consumer_Heartbeat_Time106_1016_ "Consumer_Heartbeat_Time106_1016_6A";
BA_ "SystemSignalLongSymbol" SG_ 1421 Consumer_Heartbeat_Time105_1016_ "Consumer_Heartbeat_Time105_1016_69";
BA_ "SystemSignalLongSymbol" SG_ 1421 Consumer_Heartbeat_Time104_1016_ "Consumer_Heartbeat_Time104_1016_68";
BA_ "SystemSignalLongSymbol" SG_ 1421 Consumer_Heartbeat_Time103_1016_ "Consumer_Heartbeat_Time103_1016_67";
BA_ "SystemSignalLongSymbol" SG_ 1421 Consumer_Heartbeat_Time102_1016_ "Consumer_Heartbeat_Time102_1016_66";
BA_ "SystemSignalLongSymbol" SG_ 1421 Consumer_Heartbeat_Time101_1016_ "Consumer_Heartbeat_Time101_1016_65";
BA_ "SystemSignalLongSymbol" SG_ 1421 Consumer_Heartbeat_Time100_1016_ "Consumer_Heartbeat_Time100_1016_64";
BA_ "SystemSignalLongSymbol" SG_ 1421 Consumer_Heartbeat_Time99_1016_6 "Consumer_Heartbeat_Time99_1016_63";
BA_ "SystemSignalLongSymbol" SG_ 1421 Consumer_Heartbeat_Time98_1016_6 "Consumer_Heartbeat_Time98_1016_62";
BA_ "SystemSignalLongSymbol" SG_ 1421 Consumer_Heartbeat_Time97_1016_6 "Consumer_Heartbeat_Time97_1016_61";
BA_ "SystemSignalLongSymbol" SG_ 1421 Consumer_Heartbeat_Time96_1016_6 "Consumer_Heartbeat_Time96_1016_60";
BA_ "SystemSignalLongSymbol" SG_ 1421 Consumer_Heartbeat_Time95_1016_5 "Consumer_Heartbeat_Time95_1016_5F";
BA_ "SystemSignalLongSymbol" SG_ 1421 Consumer_Heartbeat_Time94_1016_5 "Consumer_Heartbeat_Time94_1016_5E";
BA_ "SystemSignalLongSymbol" SG_ 1421 Consumer_Heartbeat_Time93_1016_5 "Consumer_Heartbeat_Time93_1016_5D";
BA_ "SystemSignalLongSymbol" SG_ 1421 Consumer_Heartbeat_Time92_1016_5 "Consumer_Heartbeat_Time92_1016_5C";
BA_ "SystemSignalLongSymbol" SG_ 1421 Consumer_Heartbeat_Time91_1016_5 "Consumer_Heartbeat_Time91_1016_5B";
BA_ "SystemSignalLongSymbol" SG_ 1421 Consumer_Heartbeat_Time90_1016_5 "Consumer_Heartbeat_Time90_1016_5A";
BA_ "SystemSignalLongSymbol" SG_ 1421 Consumer_Heartbeat_Time89_1016_5 "Consumer_Heartbeat_Time89_1016_59";
BA_ "SystemSignalLongSymbol" SG_ 1421 Consumer_Heartbeat_Time88_1016_5 "Consumer_Heartbeat_Time88_1016_58";
BA_ "SystemSignalLongSymbol" SG_ 1421 Consumer_Heartbeat_Time87_1016_5 "Consumer_Heartbeat_Time87_1016_57";
BA_ "SystemSignalLongSymbol" SG_ 1421 Consumer_Heartbeat_Time86_1016_5 "Consumer_Heartbeat_Time86_1016_56";
BA_ "SystemSignalLongSymbol" SG_ 1421 Consumer_Heartbeat_Time85_1016_5 "Consumer_Heartbeat_Time85_1016_55";
BA_ "SystemSignalLongSymbol" SG_ 1421 Consumer_Heartbeat_Time84_1016_5 "Consumer_Heartbeat_Time84_1016_54";
BA_ "SystemSignalLongSymbol" SG_ 1421 Consumer_Heartbeat_Time83_1016_5 "Consumer_Heartbeat_Time83_1016_53";
BA_ "SystemSignalLongSymbol" SG_ 1421 Consumer_Heartbeat_Time82_1016_5 "Consumer_Heartbeat_Time82_1016_52";
BA_ "SystemSignalLongSymbol" SG_ 1421 Consumer_Heartbeat_Time81_1016_5 "Consumer_Heartbeat_Time81_1016_51";
BA_ "SystemSignalLongSymbol" SG_ 1421 Consumer_Heartbeat_Time80_1016_5 "Consumer_Heartbeat_Time80_1016_50";
BA_ "SystemSignalLongSymbol" SG_ 1421 Consumer_Heartbeat_Time79_1016_4 "Consumer_Heartbeat_Time79_1016_4F";
BA_ "SystemSignalLongSymbol" SG_ 1421 Consumer_Heartbeat_Time78_1016_4 "Consumer_Heartbeat_Time78_1016_4E";
BA_ "SystemSignalLongSymbol" SG_ 1421 Consumer_Heartbeat_Time77_1016_4 "Consumer_Heartbeat_Time77_1016_4D";
BA_ "SystemSignalLongSymbol" SG_ 1421 Consumer_Heartbeat_Time76_1016_4 "Consumer_Heartbeat_Time76_1016_4C";
BA_ "SystemSignalLongSymbol" SG_ 1421 Consumer_Heartbeat_Time75_1016_4 "Consumer_Heartbeat_Time75_1016_4B";
BA_ "SystemSignalLongSymbol" SG_ 1421 Consumer_Heartbeat_Time74_1016_4 "Consumer_Heartbeat_Time74_1016_4A";
BA_ "SystemSignalLongSymbol" SG_ 1421 Consumer_Heartbeat_Time73_1016_4 "Consumer_Heartbeat_Time73_1016_49";
BA_ "SystemSignalLongSymbol" SG_ 1421 Consumer_Heartbeat_Time72_1016_4 "Consumer_Heartbeat_Time72_1016_48";
BA_ "SystemSignalLongSymbol" SG_ 1421 Consumer_Heartbeat_Time71_1016_4 "Consumer_Heartbeat_Time71_1016_47";
BA_ "SystemSignalLongSymbol" SG_ 1421 Consumer_Heartbeat_Time70_1016_4 "Consumer_Heartbeat_Time70_1016_46";
BA_ "SystemSignalLongSymbol" SG_ 1421 Consumer_Heartbeat_Time69_1016_4 "Consumer_Heartbeat_Time69_1016_45";
BA_ "SystemSignalLongSymbol" SG_ 1421 Consumer_Heartbeat_Time68_1016_4 "Consumer_Heartbeat_Time68_1016_44";
BA_ "SystemSignalLongSymbol" SG_ 1421 Consumer_Heartbeat_Time67_1016_4 "Consumer_Heartbeat_Time67_1016_43";
BA_ "SystemSignalLongSymbol" SG_ 1421 Consumer_Heartbeat_Time66_1016_4 "Consumer_Heartbeat_Time66_1016_42";
BA_ "SystemSignalLongSymbol" SG_ 1421 Consumer_Heartbeat_Time65_1016_4 "Consumer_Heartbeat_Time65_1016_41";
BA_ "SystemSignalLongSymbol" SG_ 1421 Consumer_Heartbeat_Time64_1016_4 "Consumer_Heartbeat_Time64_1016_40";
BA_ "SystemSignalLongSymbol" SG_ 1421 Consumer_Heartbeat_Time63_1016_3 "Consumer_Heartbeat_Time63_1016_3F";
BA_ "SystemSignalLongSymbol" SG_ 1421 Consumer_Heartbeat_Time62_1016_3 "Consumer_Heartbeat_Time62_1016_3E";
BA_ "SystemSignalLongSymbol" SG_ 1421 Consumer_Heartbeat_Time61_1016_3 "Consumer_Heartbeat_Time61_1016_3D";
BA_ "SystemSignalLongSymbol" SG_ 1421 Consumer_Heartbeat_Time60_1016_3 "Consumer_Heartbeat_Time60_1016_3C";
BA_ "SystemSignalLongSymbol" SG_ 1421 Consumer_Heartbeat_Time59_1016_3 "Consumer_Heartbeat_Time59_1016_3B";
BA_ "SystemSignalLongSymbol" SG_ 1421 Consumer_Heartbeat_Time58_1016_3 "Consumer_Heartbeat_Time58_1016_3A";
BA_ "SystemSignalLongSymbol" SG_ 1421 Consumer_Heartbeat_Time57_1016_3 "Consumer_Heartbeat_Time57_1016_39";
BA_ "SystemSignalLongSymbol" SG_ 1421 Consumer_Heartbeat_Time56_1016_3 "Consumer_Heartbeat_Time56_1016_38";
BA_ "SystemSignalLongSymbol" SG_ 1421 Consumer_Heartbeat_Time55_1016_3 "Consumer_Heartbeat_Time55_1016_37";
BA_ "SystemSignalLongSymbol" SG_ 1421 Consumer_Heartbeat_Time54_1016_3 "Consumer_Heartbeat_Time54_1016_36";
BA_ "SystemSignalLongSymbol" SG_ 1421 Consumer_Heartbeat_Time53_1016_3 "Consumer_Heartbeat_Time53_1016_35";
BA_ "SystemSignalLongSymbol" SG_ 1421 Consumer_Heartbeat_Time52_1016_3 "Consumer_Heartbeat_Time52_1016_34";
BA_ "SystemSignalLongSymbol" SG_ 1421 Consumer_Heartbeat_Time51_1016_3 "Consumer_Heartbeat_Time51_1016_33";
BA_ "SystemSignalLongSymbol" SG_ 1421 Consumer_Heartbeat_Time50_1016_3 "Consumer_Heartbeat_Time50_1016_32";
BA_ "SystemSignalLongSymbol" SG_ 1421 Consumer_Heartbeat_Time49_1016_3 "Consumer_Heartbeat_Time49_1016_31";
BA_ "SystemSignalLongSymbol" SG_ 1421 Consumer_Heartbeat_Time48_1016_3 "Consumer_Heartbeat_Time48_1016_30";
BA_ "SystemSignalLongSymbol" SG_ 1421 Consumer_Heartbeat_Time47_1016_2 "Consumer_Heartbeat_Time47_1016_2F";
BA_ "SystemSignalLongSymbol" SG_ 1421 Consumer_Heartbeat_Time46_1016_2 "Consumer_Heartbeat_Time46_1016_2E";
BA_ "SystemSignalLongSymbol" SG_ 1421 Consumer_Heartbeat_Time45_1016_2 "Consumer_Heartbeat_Time45_1016_2D";
BA_ "SystemSignalLongSymbol" SG_ 1421 Consumer_Heartbeat_Time44_1016_2 "Consumer_Heartbeat_Time44_1016_2C";
BA_ "SystemSignalLongSymbol" SG_ 1421 Consumer_Heartbeat_Time43_1016_2 "Consumer_Heartbeat_Time43_1016_2B";
BA_ "SystemSignalLongSymbol" SG_ 1421 Consumer_Heartbeat_Time42_1016_2 "Consumer_Heartbeat_Time42_1016_2A";
BA_ "SystemSignalLongSymbol" SG_ 1421 Consumer_Heartbeat_Time41_1016_2 "Consumer_Heartbeat_Time41_1016_29";
BA_ "SystemSignalLongSymbol" SG_ 1421 Consumer_Heartbeat_Time40_1016_2 "Consumer_Heartbeat_Time40_1016_28";
BA_ "SystemSignalLongSymbol" SG_ 1421 Consumer_Heartbeat_Time39_1016_2 "Consumer_Heartbeat_Time39_1016_27";
BA_ "SystemSignalLongSymbol" SG_ 1421 Consumer_Heartbeat_Time38_1016_2 "Consumer_Heartbeat_Time38_1016_26";
BA_ "SystemSignalLongSymbol" SG_ 1421 Consumer_Heartbeat_Time37_1016_2 "Consumer_Heartbeat_Time37_1016_25";
BA_ "SystemSignalLongSymbol" SG_ 1421 Consumer_Heartbeat_Time36_1016_2 "Consumer_Heartbeat_Time36_1016_24";
BA_ "SystemSignalLongSymbol" SG_ 1421 Consumer_Heartbeat_Time35_1016_2 "Consumer_Heartbeat_Time35_1016_23";
BA_ "SystemSignalLongSymbol" SG_ 1421 Consumer_Heartbeat_Time34_1016_2 "Consumer_Heartbeat_Time34_1016_22";
BA_ "SystemSignalLongSymbol" SG_ 1421 Consumer_Heartbeat_Time33_1016_2 "Consumer_Heartbeat_Time33_1016_21";
BA_ "SystemSignalLongSymbol" SG_ 1421 Consumer_Heartbeat_Time32_1016_2 "Consumer_Heartbeat_Time32_1016_20";
BA_ "SystemSignalLongSymbol" SG_ 1421 Consumer_Heartbeat_Time31_1016_1 "Consumer_Heartbeat_Time31_1016_1F";
BA_ "SystemSignalLongSymbol" SG_ 1421 Consumer_Heartbeat_Time30_1016_1 "Consumer_Heartbeat_Time30_1016_1E";
BA_ "SystemSignalLongSymbol" SG_ 1421 Consumer_Heartbeat_Time29_1016_1 "Consumer_Heartbeat_Time29_1016_1D";
BA_ "SystemSignalLongSymbol" SG_ 1421 Consumer_Heartbeat_Time28_1016_1 "Consumer_Heartbeat_Time28_1016_1C";
BA_ "SystemSignalLongSymbol" SG_ 1421 Consumer_Heartbeat_Time27_1016_1 "Consumer_Heartbeat_Time27_1016_1B";
BA_ "SystemSignalLongSymbol" SG_ 1421 Consumer_Heartbeat_Time26_1016_1 "Consumer_Heartbeat_Time26_1016_1A";
BA_ "SystemSignalLongSymbol" SG_ 1421 Consumer_Heartbeat_Time25_1016_1 "Consumer_Heartbeat_Time25_1016_19";
BA_ "SystemSignalLongSymbol" SG_ 1421 Consumer_Heartbeat_Time24_1016_1 "Consumer_Heartbeat_Time24_1016_18";
BA_ "SystemSignalLongSymbol" SG_ 1421 Consumer_Heartbeat_Time23_1016_1 "Consumer_Heartbeat_Time23_1016_17";
BA_ "SystemSignalLongSymbol" SG_ 1421 Consumer_Heartbeat_Time22_1016_1 "Consumer_Heartbeat_Time22_1016_16";
BA_ "SystemSignalLongSymbol" SG_ 1421 Consumer_Heartbeat_Time21_1016_1 "Consumer_Heartbeat_Time21_1016_15";
BA_ "SystemSignalLongSymbol" SG_ 1421 Consumer_Heartbeat_Time20_1016_1 "Consumer_Heartbeat_Time20_1016_14";
BA_ "SystemSignalLongSymbol" SG_ 1421 Consumer_Heartbeat_Time19_1016_1 "Consumer_Heartbeat_Time19_1016_13";
BA_ "SystemSignalLongSymbol" SG_ 1421 Consumer_Heartbeat_Time18_1016_1 "Consumer_Heartbeat_Time18_1016_12";
BA_ "SystemSignalLongSymbol" SG_ 1421 Consumer_Heartbeat_Time17_1016_1 "Consumer_Heartbeat_Time17_1016_11";
BA_ "SystemSignalLongSymbol" SG_ 1421 Consumer_Heartbeat_Time16_1016_1 "Consumer_Heartbeat_Time16_1016_10";
BA_ "SystemSignalLongSymbol" SG_ 1421 Consumer_Heartbeat_Time15_1016_0 "Consumer_Heartbeat_Time15_1016_0F";
BA_ "SystemSignalLongSymbol" SG_ 1421 Consumer_Heartbeat_Time14_1016_0 "Consumer_Heartbeat_Time14_1016_0E";
BA_ "SystemSignalLongSymbol" SG_ 1421 Consumer_Heartbeat_Time13_1016_0 "Consumer_Heartbeat_Time13_1016_0D";
BA_ "SystemSignalLongSymbol" SG_ 1421 Consumer_Heartbeat_Time12_1016_0 "Consumer_Heartbeat_Time12_1016_0C";
BA_ "SystemSignalLongSymbol" SG_ 1421 Consumer_Heartbeat_Time11_1016_0 "Consumer_Heartbeat_Time11_1016_0B";
BA_ "SystemSignalLongSymbol" SG_ 1421 Consumer_Heartbeat_Time10_1016_0 "Consumer_Heartbeat_Time10_1016_0A";
BA_ "GenSigStartValue" SG_ 1421 NrOfObjects_1016_00 126;
BA_ "GenSigStartValue" SG_ 1421 Number_of_Entries_1010_00 1;
BA_ "GenSigStartValue" SG_ 1421 Sync_Window_Length_1007 100;
BA_ "GenSigStartValue" SG_ 1421 Communication_Cycle_Period_1006 200000;
BA_ "GenSigStartValue" SG_ 1421 COB_ID_SYNC_1005 2147483776;
BA_ "SystemSignalLongSymbol" SG_ 1421 Manufacturer_Status_Registe_0007 "Manufacturer_Status_Register_1002";
BA_ "GenSigStartValue" SG_ 1421 Device_Type_1000 402;
BA_ "GenSigStartValue" SG_ 1421 Index 4096;
BA_ "GenSigStartValue" SG_ 1549 supported_drive_modes_6502 2;
BA_ "GenSigStartValue" SG_ 1549 motor_service_period_6407 1000;
BA_ "GenSigStartValue" SG_ 1549 NrOfObjects_60FE_00 2;
BA_ "SystemSignalLongSymbol" SG_ 1549 disable_operation_option_co_0004 "disable_operation_option_code_605C";
BA_ "GenSigStartValue" SG_ 1549 delta_time_6049_02 1;
BA_ "GenSigStartValue" SG_ 1549 delta_speed_6049_01 1000;
BA_ "GenSigStartValue" SG_ 1549 NrOfObjects_6049_00 2;
BA_ "GenSigStartValue" SG_ 1549 delta_time_6048_02 1;
BA_ "GenSigStartValue" SG_ 1549 delta_speed_6048_01 500;
BA_ "GenSigStartValue" SG_ 1549 NrOfObjects_6048_00 2;
BA_ "GenSigStartValue" SG_ 1549 vl_velocity_max_amount_6046_02 1000;
BA_ "GenSigStartValue" SG_ 1549 vl_velocity_min_max_amount__0004 2;
BA_ "SystemSignalLongSymbol" SG_ 1549 vl_velocity_min_max_amount__0004 "vl_velocity_min_max_amount_highest_subindex_6046_00";
BA_ "SystemSignalLongSymbol" SG_ 1549 abort_connection_option_cod_0004 "abort_connection_option_code_6007";
BA_ "GenSigStartValue" SG_ 1549 mappedObj2_1A00_02 1615003664;
BA_ "GenSigStartValue" SG_ 1549 mappedObj1_1A00_01 1614872592;
BA_ "GenSigStartValue" SG_ 1549 NrOfMappedObjects_1A00_00 2;
BA_ "GenSigStartValue" SG_ 1549 TransmissionType_1806_02 255;
BA_ "GenSigStartValue" SG_ 1549 COB_ID_1806_01 2147484959;
BA_ "GenSigStartValue" SG_ 1549 NrOfEntries_1806_00 5;
BA_ "GenSigStartValue" SG_ 1549 TransmissionType_1805_02 255;
BA_ "GenSigStartValue" SG_ 1549 COB_ID_1805_01 2147484960;
BA_ "GenSigStartValue" SG_ 1549 NrOfEntries_1805_00 5;
BA_ "GenSigStartValue" SG_ 1549 TransmissionType_1804_02 255;
BA_ "GenSigStartValue" SG_ 1549 COB_ID_1804_01 2147484961;
BA_ "GenSigStartValue" SG_ 1549 NrOfEntries_1804_00 5;
BA_ "GenSigStartValue" SG_ 1549 TransmissionType_1803_02 255;
BA_ "GenSigStartValue" SG_ 1549 COB_ID_1803_01 2147484813;
BA_ "GenSigStartValue" SG_ 1549 NrOfEntries_1803_00 5;
BA_ "GenSigStartValue" SG_ 1549 TransmissionType_1802_02 255;
BA_ "GenSigStartValue" SG_ 1549 COB_ID_1802_01 2147484557;
BA_ "GenSigStartValue" SG_ 1549 NrOfEntries_1802_00 5;
BA_ "GenSigStartValue" SG_ 1549 TransmissionType_1801_02 255;
BA_ "GenSigStartValue" SG_ 1549 COB_ID_1801_01 2147484301;
BA_ "GenSigStartValue" SG_ 1549 NrOfEntries_1801_00 5;
BA_ "GenSigStartValue" SG_ 1549 TransmissionType_1800_02 255;
BA_ "GenSigStartValue" SG_ 1549 COB_ID_1800_01 1281;
BA_ "GenSigStartValue" SG_ 1549 NrOfEntries_1800_00 5;
BA_ "GenSigStartValue" SG_ 1549 mappedObj2_1600_02 1614807056;
BA_ "GenSigStartValue" SG_ 1549 mappedObj1_1600_01 1614938128;
BA_ "GenSigStartValue" SG_ 1549 NrOfMappedObjects_1600_00 2;
BA_ "GenSigStartValue" SG_ 1549 TransmissionType_1407_02 255;
BA_ "GenSigStartValue" SG_ 1549 COB_ID_1407_01 2147484955;
BA_ "GenSigStartValue" SG_ 1549 NrOfEntries_1407_00 2;
BA_ "GenSigStartValue" SG_ 1549 TransmissionType_1406_02 255;
BA_ "GenSigStartValue" SG_ 1549 COB_ID_1406_01 2147484956;
BA_ "GenSigStartValue" SG_ 1549 NrOfEntries_1406_00 2;
BA_ "GenSigStartValue" SG_ 1549 TransmissionType_1405_02 255;
BA_ "GenSigStartValue" SG_ 1549 COB_ID_1405_01 2147484957;
BA_ "GenSigStartValue" SG_ 1549 NrOfEntries_1405_00 2;
BA_ "GenSigStartValue" SG_ 1549 TransmissionType_1404_02 255;
BA_ "GenSigStartValue" SG_ 1549 COB_ID_1404_01 2147484958;
BA_ "GenSigStartValue" SG_ 1549 NrOfEntries_1404_00 2;
BA_ "GenSigStartValue" SG_ 1549 TransmissionType_1403_02 255;
BA_ "GenSigStartValue" SG_ 1549 COB_ID_1403_01 2147484941;
BA_ "GenSigStartValue" SG_ 1549 NrOfEntries_1403_00 2;
BA_ "GenSigStartValue" SG_ 1549 TransmissionType_1402_02 255;
BA_ "GenSigStartValue" SG_ 1549 COB_ID_1402_01 2147484685;
BA_ "GenSigStartValue" SG_ 1549 NrOfEntries_1402_00 2;
BA_ "GenSigStartValue" SG_ 1549 TransmissionType_1401_02 255;
BA_ "GenSigStartValue" SG_ 1549 COB_ID_1401_01 2147484429;
BA_ "GenSigStartValue" SG_ 1549 NrOfEntries_1401_00 2;
BA_ "GenSigStartValue" SG_ 1549 TransmissionType_1400_02 255;
BA_ "GenSigStartValue" SG_ 1549 COB_ID_1400_01 897;
BA_ "GenSigStartValue" SG_ 1549 NrOfEntries_1400_00 2;
BA_ "GenSigStartValue" SG_ 1549 Serial_number_1018_04 1;
BA_ "GenSigStartValue" SG_ 1549 Revision_number_1018_03 1;
BA_ "GenSigStartValue" SG_ 1549 Product_Code_1018_02 1565;
BA_ "GenSigStartValue" SG_ 1549 Vendor_Id_1018_01 5;
BA_ "GenSigStartValue" SG_ 1549 number_of_entries_1018_00 4;
BA_ "GenSigStartValue" SG_ 1549 Producer_Heartbeat_Time_1017 1000;
BA_ "SystemSignalLongSymbol" SG_ 1549 Consumer_Heartbeat_Time126__0000 "Consumer_Heartbeat_Time126_1016_7E";
BA_ "SystemSignalLongSymbol" SG_ 1549 Consumer_Heartbeat_Time125__0000 "Consumer_Heartbeat_Time125_1016_7D";
BA_ "SystemSignalLongSymbol" SG_ 1549 Consumer_Heartbeat_Time124__0000 "Consumer_Heartbeat_Time124_1016_7C";
BA_ "SystemSignalLongSymbol" SG_ 1549 Consumer_Heartbeat_Time123__0000 "Consumer_Heartbeat_Time123_1016_7B";
BA_ "SystemSignalLongSymbol" SG_ 1549 Consumer_Heartbeat_Time122__0000 "Consumer_Heartbeat_Time122_1016_7A";
BA_ "SystemSignalLongSymbol" SG_ 1549 Consumer_Heartbeat_Time121__0000 "Consumer_Heartbeat_Time121_1016_79";
BA_ "SystemSignalLongSymbol" SG_ 1549 Consumer_Heartbeat_Time120__0000 "Consumer_Heartbeat_Time120_1016_78";
BA_ "SystemSignalLongSymbol" SG_ 1549 Consumer_Heartbeat_Time119__0000 "Consumer_Heartbeat_Time119_1016_77";
BA_ "SystemSignalLongSymbol" SG_ 1549 Consumer_Heartbeat_Time118__0000 "Consumer_Heartbeat_Time118_1016_76";
BA_ "SystemSignalLongSymbol" SG_ 1549 Consumer_Heartbeat_Time117__0000 "Consumer_Heartbeat_Time117_1016_75";
BA_ "SystemSignalLongSymbol" SG_ 1549 Consumer_Heartbeat_Time116__0000 "Consumer_Heartbeat_Time116_1016_74";
BA_ "SystemSignalLongSymbol" SG_ 1549 Consumer_Heartbeat_Time115__0000 "Consumer_Heartbeat_Time115_1016_73";
BA_ "SystemSignalLongSymbol" SG_ 1549 Consumer_Heartbeat_Time114__0000 "Consumer_Heartbeat_Time114_1016_72";
BA_ "SystemSignalLongSymbol" SG_ 1549 Consumer_Heartbeat_Time113__0000 "Consumer_Heartbeat_Time113_1016_71";
BA_ "SystemSignalLongSymbol" SG_ 1549 Consumer_Heartbeat_Time112__0000 "Consumer_Heartbeat_Time112_1016_70";
BA_ "SystemSignalLongSymbol" SG_ 1549 Consumer_Heartbeat_Time111__0000 "Consumer_Heartbeat_Time111_1016_6F";
BA_ "SystemSignalLongSymbol" SG_ 1549 Consumer_Heartbeat_Time110__0000 "Consumer_Heartbeat_Time110_1016_6E";
BA_ "SystemSignalLongSymbol" SG_ 1549 Consumer_Heartbeat_Time109__0000 "Consumer_Heartbeat_Time109_1016_6D";
BA_ "SystemSignalLongSymbol" SG_ 1549 Consumer_Heartbeat_Time108__0000 "Consumer_Heartbeat_Time108_1016_6C";
BA_ "SystemSignalLongSymbol" SG_ 1549 Consumer_Heartbeat_Time107__0000 "Consumer_Heartbeat_Time107_1016_6B";
BA_ "SystemSignalLongSymbol" SG_ 1549 Consumer_Heartbeat_Time106__0000 "Consumer_Heartbeat_Time106_1016_6A";
BA_ "SystemSignalLongSymbol" SG_ 1549 Consumer_Heartbeat_Time105__0000 "Consumer_Heartbeat_Time105_1016_69";
BA_ "SystemSignalLongSymbol" SG_ 1549 Consumer_Heartbeat_Time104__0000 "Consumer_Heartbeat_Time104_1016_68";
BA_ "SystemSignalLongSymbol" SG_ 1549 Consumer_Heartbeat_Time103__0000 "Consumer_Heartbeat_Time103_1016_67";
BA_ "SystemSignalLongSymbol" SG_ 1549 Consumer_Heartbeat_Time102__0000 "Consumer_Heartbeat_Time102_1016_66";
BA_ "SystemSignalLongSymbol" SG_ 1549 Consumer_Heartbeat_Time101__0000 "Consumer_Heartbeat_Time101_1016_65";
BA_ "SystemSignalLongSymbol" SG_ 1549 Consumer_Heartbeat_Time100__0000 "Consumer_Heartbeat_Time100_1016_64";
BA_ "SystemSignalLongSymbol" SG_ 1549 Consumer_Heartbeat_Time99_1_0000 "Consumer_Heartbeat_Time99_1016_63";
BA_ "SystemSignalLongSymbol" SG_ 1549 Consumer_Heartbeat_Time98_1_0000 "Consumer_Heartbeat_Time98_1016_62";
BA_ "SystemSignalLongSymbol" SG_ 1549 Consumer_Heartbeat_Time97_1_0000 "Consumer_Heartbeat_Time97_1016_61";
BA_ "SystemSignalLongSymbol" SG_ 1549 Consumer_Heartbeat_Time96_1_0000 "Consumer_Heartbeat_Time96_1016_60";
BA_ "SystemSignalLongSymbol" SG_ 1549 Consumer_Heartbeat_Time95_1_0000 "Consumer_Heartbeat_Time95_1016_5F";
BA_ "SystemSignalLongSymbol" SG_ 1549 Consumer_Heartbeat_Time94_1_0000 "Consumer_Heartbeat_Time94_1016_5E";
BA_ "SystemSignalLongSymbol" SG_ 1549 Consumer_Heartbeat_Time93_1_0000 "Consumer_Heartbeat_Time93_1016_5D";
BA_ "SystemSignalLongSymbol" SG_ 1549 Consumer_Heartbeat_Time92_1_0000 "Consumer_Heartbeat_Time92_1016_5C";
BA_ "SystemSignalLongSymbol" SG_ 1549 Consumer_Heartbeat_Time91_1_0000 "Consumer_Heartbeat_Time91_1016_5B";
BA_ "SystemSignalLongSymbol" SG_ 1549 Consumer_Heartbeat_Time90_1_0000 "Consumer_Heartbeat_Time90_1016_5A";
BA_ "SystemSignalLongSymbol" SG_ 1549 Consumer_Heartbeat_Time89_1_0000 "Consumer_Heartbeat_Time89_1016_59";
BA_ "SystemSignalLongSymbol" SG_ 1549 Consumer_Heartbeat_Time88_1_0000 "Consumer_Heartbeat_Time88_1016_58";
BA_ "SystemSignalLongSymbol" SG_ 1549 Consumer_Heartbeat_Time87_1_0000 "Consumer_Heartbeat_Time87_1016_57";
BA_ "SystemSignalLongSymbol" SG_ 1549 Consumer_Heartbeat_Time86_1_0000 "Consumer_Heartbeat_Time86_1016_56";
BA_ "SystemSignalLongSymbol" SG_ 1549 Consumer_Heartbeat_Time85_1_0000 "Consumer_Heartbeat_Time85_1016_55";
BA_ "SystemSignalLongSymbol" SG_ 1549 Consumer_Heartbeat_Time84_1_0000 "Consumer_Heartbeat_Time84_1016_54";
BA_ "SystemSignalLongSymbol" SG_ 1549 Consumer_Heartbeat_Time83_1_0000 "Consumer_Heartbeat_Time83_1016_53";
BA_ "SystemSignalLongSymbol" SG_ 1549 Consumer_Heartbeat_Time82_1_0000 "Consumer_Heartbeat_Time82_1016_52";
BA_ "SystemSignalLongSymbol" SG_ 1549 Consumer_Heartbeat_Time81_1_0000 "Consumer_Heartbeat_Time81_1016_51";
BA_ "SystemSignalLongSymbol" SG_ 1549 Consumer_Heartbeat_Time80_1_0000 "Consumer_Heartbeat_Time80_1016_50";
BA_ "SystemSignalLongSymbol" SG_ 1549 Consumer_Heartbeat_Time79_1_0000 "Consumer_Heartbeat_Time79_1016_4F";
BA_ "SystemSignalLongSymbol" SG_ 1549 Consumer_Heartbeat_Time78_1_0000 "Consumer_Heartbeat_Time78_1016_4E";
BA_ "SystemSignalLongSymbol" SG_ 1549 Consumer_Heartbeat_Time77_1_0000 "Consumer_Heartbeat_Time77_1016_4D";
BA_ "SystemSignalLongSymbol" SG_ 1549 Consumer_Heartbeat_Time76_1_0000 "Consumer_Heartbeat_Time76_1016_4C";
BA_ "SystemSignalLongSymbol" SG_ 1549 Consumer_Heartbeat_Time75_1_0000 "Consumer_Heartbeat_Time75_1016_4B";
BA_ "SystemSignalLongSymbol" SG_ 1549 Consumer_Heartbeat_Time74_1_0000 "Consumer_Heartbeat_Time74_1016_4A";
BA_ "SystemSignalLongSymbol" SG_ 1549 Consumer_Heartbeat_Time73_1_0000 "Consumer_Heartbeat_Time73_1016_49";
BA_ "SystemSignalLongSymbol" SG_ 1549 Consumer_Heartbeat_Time72_1_0000 "Consumer_Heartbeat_Time72_1016_48";
BA_ "SystemSignalLongSymbol" SG_ 1549 Consumer_Heartbeat_Time71_1_0000 "Consumer_Heartbeat_Time71_1016_47";
BA_ "SystemSignalLongSymbol" SG_ 1549 Consumer_Heartbeat_Time70_1_0000 "Consumer_Heartbeat_Time70_1016_46";
BA_ "SystemSignalLongSymbol" SG_ 1549 Consumer_Heartbeat_Time69_1_0000 "Consumer_Heartbeat_Time69_1016_45";
BA_ "SystemSignalLongSymbol" SG_ 1549 Consumer_Heartbeat_Time68_1_0000 "Consumer_Heartbeat_Time68_1016_44";
BA_ "SystemSignalLongSymbol" SG_ 1549 Consumer_Heartbeat_Time67_1_0000 "Consumer_Heartbeat_Time67_1016_43";
BA_ "SystemSignalLongSymbol" SG_ 1549 Consumer_Heartbeat_Time66_1_0000 "Consumer_Heartbeat_Time66_1016_42";
BA_ "SystemSignalLongSymbol" SG_ 1549 Consumer_Heartbeat_Time65_1_0000 "Consumer_Heartbeat_Time65_1016_41";
BA_ "SystemSignalLongSymbol" SG_ 1549 Consumer_Heartbeat_Time64_1_0000 "Consumer_Heartbeat_Time64_1016_40";
BA_ "SystemSignalLongSymbol" SG_ 1549 Consumer_Heartbeat_Time63_1_0000 "Consumer_Heartbeat_Time63_1016_3F";
BA_ "SystemSignalLongSymbol" SG_ 1549 Consumer_Heartbeat_Time62_1_0000 "Consumer_Heartbeat_Time62_1016_3E";
BA_ "SystemSignalLongSymbol" SG_ 1549 Consumer_Heartbeat_Time61_1_0000 "Consumer_Heartbeat_Time61_1016_3D";
BA_ "SystemSignalLongSymbol" SG_ 1549 Consumer_Heartbeat_Time60_1_0000 "Consumer_Heartbeat_Time60_1016_3C";
BA_ "SystemSignalLongSymbol" SG_ 1549 Consumer_Heartbeat_Time59_1_0000 "Consumer_Heartbeat_Time59_1016_3B";
BA_ "SystemSignalLongSymbol" SG_ 1549 Consumer_Heartbeat_Time58_1_0000 "Consumer_Heartbeat_Time58_1016_3A";
BA_ "SystemSignalLongSymbol" SG_ 1549 Consumer_Heartbeat_Time57_1_0000 "Consumer_Heartbeat_Time57_1016_39";
BA_ "SystemSignalLongSymbol" SG_ 1549 Consumer_Heartbeat_Time56_1_0000 "Consumer_Heartbeat_Time56_1016_38";
BA_ "SystemSignalLongSymbol" SG_ 1549 Consumer_Heartbeat_Time55_1_0000 "Consumer_Heartbeat_Time55_1016_37";
BA_ "SystemSignalLongSymbol" SG_ 1549 Consumer_Heartbeat_Time54_1_0000 "Consumer_Heartbeat_Time54_1016_36";
BA_ "SystemSignalLongSymbol" SG_ 1549 Consumer_Heartbeat_Time53_1_0000 "Consumer_Heartbeat_Time53_1016_35";
BA_ "SystemSignalLongSymbol" SG_ 1549 Consumer_Heartbeat_Time52_1_0000 "Consumer_Heartbeat_Time52_1016_34";
BA_ "SystemSignalLongSymbol" SG_ 1549 Consumer_Heartbeat_Time51_1_0000 "Consumer_Heartbeat_Time51_1016_33";
BA_ "SystemSignalLongSymbol" SG_ 1549 Consumer_Heartbeat_Time50_1_0000 "Consumer_Heartbeat_Time50_1016_32";
BA_ "SystemSignalLongSymbol" SG_ 1549 Consumer_Heartbeat_Time49_1_0000 "Consumer_Heartbeat_Time49_1016_31";
BA_ "SystemSignalLongSymbol" SG_ 1549 Consumer_Heartbeat_Time48_1_0000 "Consumer_Heartbeat_Time48_1016_30";
BA_ "SystemSignalLongSymbol" SG_ 1549 Consumer_Heartbeat_Time47_1_0000 "Consumer_Heartbeat_Time47_1016_2F";
BA_ "SystemSignalLongSymbol" SG_ 1549 Consumer_Heartbeat_Time46_1_0000 "Consumer_Heartbeat_Time46_1016_2E";
BA_ "SystemSignalLongSymbol" SG_ 1549 Consumer_Heartbeat_Time45_1_0000 "Consumer_Heartbeat_Time45_1016_2D";
BA_ "SystemSignalLongSymbol" SG_ 1549 Consumer_Heartbeat_Time44_1_0000 "Consumer_Heartbeat_Time44_1016_2C";
BA_ "SystemSignalLongSymbol" SG_ 1549 Consumer_Heartbeat_Time43_1_0000 "Consumer_Heartbeat_Time43_1016_2B";
BA_ "SystemSignalLongSymbol" SG_ 1549 Consumer_Heartbeat_Time42_1_0000 "Consumer_Heartbeat_Time42_1016_2A";
BA_ "SystemSignalLongSymbol" SG_ 1549 Consumer_Heartbeat_Time41_1_0000 "Consumer_Heartbeat_Time41_1016_29";
BA_ "SystemSignalLongSymbol" SG_ 1549 Consumer_Heartbeat_Time40_1_0000 "Consumer_Heartbeat_Time40_1016_28";
BA_ "SystemSignalLongSymbol" SG_ 1549 Consumer_Heartbeat_Time39_1_0000 "Consumer_Heartbeat_Time39_1016_27";
BA_ "SystemSignalLongSymbol" SG_ 1549 Consumer_Heartbeat_Time38_1_0000 "Consumer_Heartbeat_Time38_1016_26";
BA_ "SystemSignalLongSymbol" SG_ 1549 Consumer_Heartbeat_Time37_1_0000 "Consumer_Heartbeat_Time37_1016_25";
BA_ "SystemSignalLongSymbol" SG_ 1549 Consumer_Heartbeat_Time36_1_0000 "Consumer_Heartbeat_Time36_1016_24";
BA_ "SystemSignalLongSymbol" SG_ 1549 Consumer_Heartbeat_Time35_1_0000 "Consumer_Heartbeat_Time35_1016_23";
BA_ "SystemSignalLongSymbol" SG_ 1549 Consumer_Heartbeat_Time34_1_0000 "Consumer_Heartbeat_Time34_1016_22";
BA_ "SystemSignalLongSymbol" SG_ 1549 Consumer_Heartbeat_Time33_1_0000 "Consumer_Heartbeat_Time33_1016_21";
BA_ "SystemSignalLongSymbol" SG_ 1549 Consumer_Heartbeat_Time32_1_0000 "Consumer_Heartbeat_Time32_1016_20";
BA_ "SystemSignalLongSymbol" SG_ 1549 Consumer_Heartbeat_Time31_1_0000 "Consumer_Heartbeat_Time31_1016_1F";
BA_ "SystemSignalLongSymbol" SG_ 1549 Consumer_Heartbeat_Time30_1_0000 "Consumer_Heartbeat_Time30_1016_1E";
BA_ "SystemSignalLongSymbol" SG_ 1549 Consumer_Heartbeat_Time29_1_0000 "Consumer_Heartbeat_Time29_1016_1D";
BA_ "SystemSignalLongSymbol" SG_ 1549 Consumer_Heartbeat_Time28_1_0000 "Consumer_Heartbeat_Time28_1016_1C";
BA_ "SystemSignalLongSymbol" SG_ 1549 Consumer_Heartbeat_Time27_1_0000 "Consumer_Heartbeat_Time27_1016_1B";
BA_ "SystemSignalLongSymbol" SG_ 1549 Consumer_Heartbeat_Time26_1_0000 "Consumer_Heartbeat_Time26_1016_1A";
BA_ "SystemSignalLongSymbol" SG_ 1549 Consumer_Heartbeat_Time25_1_0000 "Consumer_Heartbeat_Time25_1016_19";
BA_ "SystemSignalLongSymbol" SG_ 1549 Consumer_Heartbeat_Time24_1_0000 "Consumer_Heartbeat_Time24_1016_18";
BA_ "SystemSignalLongSymbol" SG_ 1549 Consumer_Heartbeat_Time23_1_0000 "Consumer_Heartbeat_Time23_1016_17";
BA_ "SystemSignalLongSymbol" SG_ 1549 Consumer_Heartbeat_Time22_1_0000 "Consumer_Heartbeat_Time22_1016_16";
BA_ "SystemSignalLongSymbol" SG_ 1549 Consumer_Heartbeat_Time21_1_0000 "Consumer_Heartbeat_Time21_1016_15";
BA_ "SystemSignalLongSymbol" SG_ 1549 Consumer_Heartbeat_Time20_1_0000 "Consumer_Heartbeat_Time20_1016_14";
BA_ "SystemSignalLongSymbol" SG_ 1549 Consumer_Heartbeat_Time19_1_0000 "Consumer_Heartbeat_Time19_1016_13";
BA_ "SystemSignalLongSymbol" SG_ 1549 Consumer_Heartbeat_Time18_1_0000 "Consumer_Heartbeat_Time18_1016_12";
BA_ "SystemSignalLongSymbol" SG_ 1549 Consumer_Heartbeat_Time17_1_0000 "Consumer_Heartbeat_Time17_1016_11";
BA_ "SystemSignalLongSymbol" SG_ 1549 Consumer_Heartbeat_Time16_1_0000 "Consumer_Heartbeat_Time16_1016_10";
BA_ "SystemSignalLongSymbol" SG_ 1549 Consumer_Heartbeat_Time15_1_0000 "Consumer_Heartbeat_Time15_1016_0F";
BA_ "SystemSignalLongSymbol" SG_ 1549 Consumer_Heartbeat_Time14_1_0000 "Consumer_Heartbeat_Time14_1016_0E";
BA_ "SystemSignalLongSymbol" SG_ 1549 Consumer_Heartbeat_Time13_1_0000 "Consumer_Heartbeat_Time13_1016_0D";
BA_ "SystemSignalLongSymbol" SG_ 1549 Consumer_Heartbeat_Time12_1_0000 "Consumer_Heartbeat_Time12_1016_0C";
BA_ "SystemSignalLongSymbol" SG_ 1549 Consumer_Heartbeat_Time11_1_0000 "Consumer_Heartbeat_Time11_1016_0B";
BA_ "SystemSignalLongSymbol" SG_ 1549 Consumer_Heartbeat_Time10_1_0000 "Consumer_Heartbeat_Time10_1016_0A";
BA_ "GenSigStartValue" SG_ 1549 NrOfObjects_1016_00 126;
BA_ "GenSigStartValue" SG_ 1549 Number_of_Entries_1010_00 1;
BA_ "GenSigStartValue" SG_ 1549 Sync_Window_Length_1007 100;
BA_ "GenSigStartValue" SG_ 1549 Communication_Cycle_Period_1006 200000;
BA_ "GenSigStartValue" SG_ 1549 COB_ID_SYNC_1005 2147483776;
BA_ "SystemSignalLongSymbol" SG_ 1549 Manufacturer_Status_Registe_0008 "Manufacturer_Status_Register_1002";
BA_ "GenSigStartValue" SG_ 1549 Device_Type_1000 402;
BA_ "GenSigStartValue" SG_ 1549 Index 4096;
VAL_ 1421 SubIndex_6502 0 "supported_drive_modes" ;
VAL_ 1421 SubIndex_6407 0 "motor_service_period" ;
VAL_ 1421 SubIndex_6402 0 "motor_type" ;
VAL_ 1421 SubIndex_60FE 2 "bitmask" 1 "physical_outputs" 0 "NrOfObjects" ;
VAL_ 1421 SubIndex_60FD 0 "digital_inputs" ;
VAL_ 1421 SubIndex_607E 0 "polarity" ;
VAL_ 1421 SubIndex_6067 0 "position_window" ;
VAL_ 1421 SubIndex_6064 0 "position_actual_value" ;
VAL_ 1421 SubIndex_6063 0 "position_actual_value" ;
VAL_ 1421 SubIndex_6062 0 "position_demand_value" ;
VAL_ 1421 SubIndex_6061 0 "modes_of_operation_display" ;
VAL_ 1421 SubIndex_6060 0 "modes_of_operation" ;
VAL_ 1421 SubIndex_605E 0 "fault_reaction_option_code" ;
VAL_ 1421 SubIndex_605D 0 "stop_option_code" ;
VAL_ 1421 SubIndex_605C 0 "disable_operation_option_code" ;
VAL_ 1421 SubIndex_605B 0 "shutdown_option_code" ;
VAL_ 1421 SubIndex_605A 0 "quick_stop_option_code" ;
VAL_ 1421 SubIndex_6049 2 "delta_time" 1 "delta_speed" 0 "NrOfObjects" ;
VAL_ 1421 SubIndex_6048 2 "delta_time" 1 "delta_speed" 0 "NrOfObjects" ;
VAL_ 1421 SubIndex_6046 2 "vl_velocity_max_amount" 1 "vl_velocity_min_amount" 0 "vl_velocity_min_max_amount_highest_subindex" ;
VAL_ 1421 SubIndex_6044 0 "vl_control_effort" ;
VAL_ 1421 SubIndex_6043 0 "vl_velocity_demand" ;
VAL_ 1421 SubIndex_6042 0 "vl_target_velocity" ;
VAL_ 1421 SubIndex_6041 0 "statusword" ;
VAL_ 1421 SubIndex_6040 0 "controlword" ;
VAL_ 1421 SubIndex_603F 0 "error_code" ;
VAL_ 1421 SubIndex_6007 0 "abort_connection_option_code" ;
VAL_ 1421 SubIndex_1A06 0 "NrOfMappedObjects" ;
VAL_ 1421 SubIndex_1A05 0 "NrOfMappedObjects" ;
VAL_ 1421 SubIndex_1A04 0 "NrOfMappedObjects" ;
VAL_ 1421 SubIndex_1A03 0 "NrOfMappedObjects" ;
VAL_ 1421 SubIndex_1A02 0 "NrOfMappedObjects" ;
VAL_ 1421 SubIndex_1A01 0 "NrOfMappedObjects" ;
VAL_ 1421 SubIndex_1A00 2 "mappedObj2" 1 "mappedObj1" 0 "NrOfMappedObjects" ;
VAL_ 1421 SubIndex_1806 5 "EventTimer" 2 "TransmissionType" 1 "COB-ID" 0 "NrOfEntries" ;
VAL_ 1421 SubIndex_1805 5 "EventTimer" 2 "TransmissionType" 1 "COB-ID" 0 "NrOfEntries" ;
VAL_ 1421 SubIndex_1804 5 "EventTimer" 2 "TransmissionType" 1 "COB-ID" 0 "NrOfEntries" ;
VAL_ 1421 SubIndex_1803 5 "EventTimer" 2 "TransmissionType" 1 "COB-ID" 0 "NrOfEntries" ;
VAL_ 1421 SubIndex_1802 5 "EventTimer" 2 "TransmissionType" 1 "COB-ID" 0 "NrOfEntries" ;
VAL_ 1421 SubIndex_1801 5 "EventTimer" 2 "TransmissionType" 1 "COB-ID" 0 "NrOfEntries" ;
VAL_ 1421 SubIndex_1800 5 "EventTimer" 2 "TransmissionType" 1 "COB-ID" 0 "NrOfEntries" ;
VAL_ 1421 SubIndex_1607 0 "NrOfMappedObjects" ;
VAL_ 1421 SubIndex_1606 0 "NrOfMappedObjects" ;
VAL_ 1421 SubIndex_1605 0 "NrOfMappedObjects" ;
VAL_ 1421 SubIndex_1604 0 "NrOfMappedObjects" ;
VAL_ 1421 SubIndex_1603 0 "NrOfMappedObjects" ;
VAL_ 1421 SubIndex_1602 0 "NrOfMappedObjects" ;
VAL_ 1421 SubIndex_1601 0 "NrOfMappedObjects" ;
VAL_ 1421 SubIndex_1600 2 "mappedObj2" 1 "mappedObj1" 0 "NrOfMappedObjects" ;
VAL_ 1421 SubIndex_1407 2 "TransmissionType" 1 "COB-ID" 0 "NrOfEntries" ;
VAL_ 1421 SubIndex_1406 2 "TransmissionType" 1 "COB-ID" 0 "NrOfEntries" ;
VAL_ 1421 SubIndex_1405 2 "TransmissionType" 1 "COB-ID" 0 "NrOfEntries" ;
VAL_ 1421 SubIndex_1404 2 "TransmissionType" 1 "COB-ID" 0 "NrOfEntries" ;
VAL_ 1421 SubIndex_1403 2 "TransmissionType" 1 "COB-ID" 0 "NrOfEntries" ;
VAL_ 1421 SubIndex_1402 2 "TransmissionType" 1 "COB-ID" 0 "NrOfEntries" ;
VAL_ 1421 SubIndex_1401 2 "TransmissionType" 1 "COB-ID" 0 "NrOfEntries" ;
VAL_ 1421 SubIndex_1400 2 "TransmissionType" 1 "COB-ID" 0 "NrOfEntries" ;
VAL_ 1421 SubIndex_1018 4 "Serial number" 3 "Revision number" 2 "Product Code" 1 "Vendor Id" 0 "number of entries" ;
VAL_ 1421 SubIndex_1017 0 "Producer Heartbeat Time" ;
VAL_ 1421 SubIndex_1016 126 "Consumer Heartbeat Time126" 125 "Consumer Heartbeat Time125" 124 "Consumer Heartbeat Time124" 123 "Consumer Heartbeat Time123" 122 "Consumer Heartbeat Time122" 121 "Consumer Heartbeat Time121" 120 "Consumer Heartbeat Time120" 119 "Consumer Heartbeat Time119" 118 "Consumer Heartbeat Time118" 117 "Consumer Heartbeat Time117" 116 "Consumer Heartbeat Time116" 115 "Consumer Heartbeat Time115" 114 "Consumer Heartbeat Time114" 113 "Consumer Heartbeat Time113" 112 "Consumer Heartbeat Time112" 111 "Consumer Heartbeat Time111" 110 "Consumer Heartbeat Time110" 109 "Consumer Heartbeat Time109" 108 "Consumer Heartbeat Time108" 107 "Consumer Heartbeat Time107" 106 "Consumer Heartbeat Time106" 105 "Consumer Heartbeat Time105" 104 "Consumer Heartbeat Time104" 103 "Consumer Heartbeat Time103" 102 "Consumer Heartbeat Time102" 101 "Consumer Heartbeat Time101" 100 "Consumer Heartbeat Time100" 99 "Consumer Heartbeat Time99" 98 "Consumer Heartbeat Time98" 97 "Consumer Heartbeat Time97" 96 "Consumer Heartbeat Time96" 95 "Consumer Heartbeat Time95" 94 "Consumer Heartbeat Time94" 93 "Consumer Heartbeat Time93" 92 "Consumer Heartbeat Time92" 91 "Consumer Heartbeat Time91" 90 "Consumer Heartbeat Time90" 89 "Consumer Heartbeat Time89" 88 "Consumer Heartbeat Time88" 87 "Consumer Heartbeat Time87" 86 "Consumer Heartbeat Time86" 85 "Consumer Heartbeat Time85" 84 "Consumer Heartbeat Time84" 83 "Consumer Heartbeat Time83" 82 "Consumer Heartbeat Time82" 81 "Consumer Heartbeat Time81" 80 "Consumer Heartbeat Time80" 79 "Consumer Heartbeat Time79" 78 "Consumer Heartbeat Time78" 77 "Consumer Heartbeat Time77" 76 "Consumer Heartbeat Time76" 75 "Consumer Heartbeat Time75" 74 "Consumer Heartbeat Time74" 73 "Consumer Heartbeat Time73" 72 "Consumer Heartbeat Time72" 71 "Consumer Heartbeat Time71" 70 "Consumer Heartbeat Time70" 69 "Consumer Heartbeat Time69" 68 "Consumer Heartbeat Time68" 67 "Consumer Heartbeat Time67" 66 "Consumer Heartbeat Time66" 65 "Consumer Heartbeat Time65" 64 "Consumer Heartbeat Time64" 63 "Consumer Heartbeat Time63" 62 "Consumer Heartbeat Time62" 61 "Consumer Heartbeat Time61" 60 "Consumer Heartbeat Time60" 59 "Consumer Heartbeat Time59" 58 "Consumer Heartbeat Time58" 57 "Consumer Heartbeat Time57" 56 "Consumer Heartbeat Time56" 55 "Consumer Heartbeat Time55" 54 "Consumer Heartbeat Time54" 53 "Consumer Heartbeat Time53" 52 "Consumer Heartbeat Time52" 51 "Consumer Heartbeat Time51" 50 "Consumer Heartbeat Time50" 49 "Consumer Heartbeat Time49" 48 "Consumer Heartbeat Time48" 47 "Consumer Heartbeat Time47" 46 "Consumer Heartbeat Time46" 45 "Consumer Heartbeat Time45" 44 "Consumer Heartbeat Time44" 43 "Consumer Heartbeat Time43" 42 "Consumer Heartbeat Time42" 41 "Consumer Heartbeat Time41" 40 "Consumer Heartbeat Time40" 39 "Consumer Heartbeat Time39" 38 "Consumer Heartbeat Time38" 37 "Consumer Heartbeat Time37" 36 "Consumer Heartbeat Time36" 35 "Consumer Heartbeat Time35" 34 "Consumer Heartbeat Time34" 33 "Consumer Heartbeat Time33" 32 "Consumer Heartbeat Time32" 31 "Consumer Heartbeat Time31" 30 "Consumer Heartbeat Time30" 29 "Consumer Heartbeat Time29" 28 "Consumer Heartbeat Time28" 27 "Consumer Heartbeat Time27" 26 "Consumer Heartbeat Time26" 25 "Consumer Heartbeat Time25" 24 "Consumer Heartbeat Time24" 23 "Consumer Heartbeat Time23" 22 "Consumer Heartbeat Time22" 21 "Consumer Heartbeat Time21" 20 "Consumer Heartbeat Time20" 19 "Consumer Heartbeat Time19" 18 "Consumer Heartbeat Time18" 17 "Consumer Heartbeat Time17" 16 "Consumer Heartbeat Time16" 15 "Consumer Heartbeat Time15" 14 "Consumer Heartbeat Time14" 13 "Consumer Heartbeat Time13" 12 "Consumer Heartbeat Time12" 11 "Consumer Heartbeat Time11" 10 "Consumer Heartbeat Time10" 9 "Consumer Heartbeat Time" 8 "Consumer Heartbeat Time" 7 "Consumer Heartbeat Time" 6 "Consumer Heartbeat Time" 5 "Consumer Heartbeat Time" 4 "Consumer Heartbeat Time" 3 "Consumer Heartbeat Time" 2 "Consumer Heartbeat Time" 1 "Consumer Heartbeat Time" 0 "NrOfObjects" ;
VAL_ 1421 SubIndex_1010 1 "Save all Parameters" 0 "Number of Entries" ;
VAL_ 1421 SubIndex_100D 0 "Life Time Factor" ;
VAL_ 1421 SubIndex_100C 0 "Guard Time" ;
VAL_ 1421 SubIndex_1007 0 "Sync_Window Length" ;
VAL_ 1421 SubIndex_1006 0 "Communication Cycle Period" ;
VAL_ 1421 SubIndex_1005 0 "COB-ID SYNC" ;
VAL_ 1421 SubIndex_1002 0 "Manufacturer Status Register" ;
VAL_ 1421 SubIndex_1001 0 "Error Register" ;
VAL_ 1421 SubIndex_1000 0 "Device Type" ;
VAL_ 1421 Index 25858 "supported_drive_modes" 25607 "motor_service_period" 25602 "motor_type" 24830 "digital_outputs" 24829 "digital_inputs" 24702 "polarity" 24679 "position_window" 24676 "position_actual_value" 24675 "position_actual_value" 24674 "position_demand_value" 24673 "modes_of_operation_display" 24672 "modes_of_operation" 24670 "fault_reaction_option_code" 24669 "stop_option_code" 24668 "disable_operation_option_code" 24667 "shutdown_option_code" 24666 "quick_stop_option_code" 24649 "vl_velocity_deceleration" 24648 "vl_velocity_acceleration" 24646 "vl_velocity_min_max_amount" 24644 "vl_control_effort" 24643 "vl_velocity_demand" 24642 "vl_target_velocity" 24641 "statusword" 24640 "controlword" 24639 "error_code" 24583 "abort_connection_option_code" 6662 "TxPDOMapping" 6661 "TxPDOMapping" 6660 "TxPDOMapping" 6659 "TxPDOMapping" 6658 "TxPDOMapping" 6657 "TxPDOMapping" 6656 "TxPDOMapping" 6150 "TxPDOComPar" 6149 "TxPDOComPar" 6148 "TxPDOComPar" 6147 "TxPDOComPar" 6146 "TxPDOComPar" 6145 "TxPDOComPar" 6144 "TxPDOComPar" 5639 "RxPDOMapping" 5638 "RxPDOMapping" 5637 "RxPDOMapping" 5636 "RxPDOMapping" 5635 "RxPDOMapping" 5634 "RxPDOMapping" 5633 "RxPDOMapping" 5632 "RxPDOMapping" 5127 "RxPDOComPar" 5126 "RxPDOComPar" 5125 "RxPDOComPar" 5124 "RxPDOComPar" 5123 "RxPDOComPar" 5122 "RxPDOComPar" 5121 "RxPDOComPar" 5120 "RxPDOComPar" 4120 "Identity Object" 4119 "Producer Heartbeat Time" 4118 "Consumer Heartbeat Time" 4112 "Store Parameter Field" 4109 "Life Time Factor" 4108 "Guard Time" 4103 "Sync_Window Length" 4102 "Communication Cycle Period" 4101 "COB-ID SYNC" 4098 "Manufacturer Status Register" 4097 "Error Register" 4096 "Device Type" ;
VAL_ 1421 TransferType 1 "Expedited transfer" 0 "Normal transfer" ;
VAL_ 1421 SizeIndicator 1 "Size is indicated" 0 "Size is not indicated" ;
VAL_ 1421 SCS 2 "Upload" 1 "Download" ;
VAL_ 1549 SubIndex_6502 0 "supported_drive_modes" ;
VAL_ 1549 SubIndex_6407 0 "motor_service_period" ;
VAL_ 1549 SubIndex_6402 0 "motor_type" ;
VAL_ 1549 SubIndex_60FE 2 "bitmask" 1 "physical_outputs" 0 "NrOfObjects" ;
VAL_ 1549 SubIndex_60FD 0 "digital_inputs" ;
VAL_ 1549 SubIndex_607E 0 "polarity" ;
VAL_ 1549 SubIndex_6067 0 "position_window" ;
VAL_ 1549 SubIndex_6064 0 "position_actual_value" ;
VAL_ 1549 SubIndex_6063 0 "position_actual_value" ;
VAL_ 1549 SubIndex_6062 0 "position_demand_value" ;
VAL_ 1549 SubIndex_6061 0 "modes_of_operation_display" ;
VAL_ 1549 SubIndex_6060 0 "modes_of_operation" ;
VAL_ 1549 SubIndex_605E 0 "fault_reaction_option_code" ;
VAL_ 1549 SubIndex_605D 0 "stop_option_code" ;
VAL_ 1549 SubIndex_605C 0 "disable_operation_option_code" ;
VAL_ 1549 SubIndex_605B 0 "shutdown_option_code" ;
VAL_ 1549 SubIndex_605A 0 "quick_stop_option_code" ;
VAL_ 1549 SubIndex_6049 2 "delta_time" 1 "delta_speed" 0 "NrOfObjects" ;
VAL_ 1549 SubIndex_6048 2 "delta_time" 1 "delta_speed" 0 "NrOfObjects" ;
VAL_ 1549 SubIndex_6046 2 "vl_velocity_max_amount" 1 "vl_velocity_min_amount" 0 "vl_velocity_min_max_amount_highest_subindex" ;
VAL_ 1549 SubIndex_6044 0 "vl_control_effort" ;
VAL_ 1549 SubIndex_6043 0 "vl_velocity_demand" ;
VAL_ 1549 SubIndex_6042 0 "vl_target_velocity" ;
VAL_ 1549 SubIndex_6041 0 "statusword" ;
VAL_ 1549 SubIndex_6040 0 "controlword" ;
VAL_ 1549 SubIndex_603F 0 "error_code" ;
VAL_ 1549 SubIndex_6007 0 "abort_connection_option_code" ;
VAL_ 1549 SubIndex_1A06 0 "NrOfMappedObjects" ;
VAL_ 1549 SubIndex_1A05 0 "NrOfMappedObjects" ;
VAL_ 1549 SubIndex_1A04 0 "NrOfMappedObjects" ;
VAL_ 1549 SubIndex_1A03 0 "NrOfMappedObjects" ;
VAL_ 1549 SubIndex_1A02 0 "NrOfMappedObjects" ;
VAL_ 1549 SubIndex_1A01 0 "NrOfMappedObjects" ;
VAL_ 1549 SubIndex_1A00 2 "mappedObj2" 1 "mappedObj1" 0 "NrOfMappedObjects" ;
VAL_ 1549 SubIndex_1806 5 "EventTimer" 2 "TransmissionType" 1 "COB-ID" 0 "NrOfEntries" ;
VAL_ 1549 SubIndex_1805 5 "EventTimer" 2 "TransmissionType" 1 "COB-ID" 0 "NrOfEntries" ;
VAL_ 1549 SubIndex_1804 5 "EventTimer" 2 "TransmissionType" 1 "COB-ID" 0 "NrOfEntries" ;
VAL_ 1549 SubIndex_1803 5 "EventTimer" 2 "TransmissionType" 1 "COB-ID" 0 "NrOfEntries" ;
VAL_ 1549 SubIndex_1802 5 "EventTimer" 2 "TransmissionType" 1 "COB-ID" 0 "NrOfEntries" ;
VAL_ 1549 SubIndex_1801 5 "EventTimer" 2 "TransmissionType" 1 "COB-ID" 0 "NrOfEntries" ;
VAL_ 1549 SubIndex_1800 5 "EventTimer" 2 "TransmissionType" 1 "COB-ID" 0 "NrOfEntries" ;
VAL_ 1549 SubIndex_1607 0 "NrOfMappedObjects" ;
VAL_ 1549 SubIndex_1606 0 "NrOfMappedObjects" ;
VAL_ 1549 SubIndex_1605 0 "NrOfMappedObjects" ;
VAL_ 1549 SubIndex_1604 0 "NrOfMappedObjects" ;
VAL_ 1549 SubIndex_1603 0 "NrOfMappedObjects" ;
VAL_ 1549 SubIndex_1602 0 "NrOfMappedObjects" ;
VAL_ 1549 SubIndex_1601 0 "NrOfMappedObjects" ;
VAL_ 1549 SubIndex_1600 2 "mappedObj2" 1 "mappedObj1" 0 "NrOfMappedObjects" ;
VAL_ 1549 SubIndex_1407 2 "TransmissionType" 1 "COB-ID" 0 "NrOfEntries" ;
VAL_ 1549 SubIndex_1406 2 "TransmissionType" 1 "COB-ID" 0 "NrOfEntries" ;
VAL_ 1549 SubIndex_1405 2 "TransmissionType" 1 "COB-ID" 0 "NrOfEntries" ;
VAL_ 1549 SubIndex_1404 2 "TransmissionType" 1 "COB-ID" 0 "NrOfEntries" ;
VAL_ 1549 SubIndex_1403 2 "TransmissionType" 1 "COB-ID" 0 "NrOfEntries" ;
VAL_ 1549 SubIndex_1402 2 "TransmissionType" 1 "COB-ID" 0 "NrOfEntries" ;
VAL_ 1549 SubIndex_1401 2 "TransmissionType" 1 "COB-ID" 0 "NrOfEntries" ;
VAL_ 1549 SubIndex_1400 2 "TransmissionType" 1 "COB-ID" 0 "NrOfEntries" ;
VAL_ 1549 SubIndex_1018 4 "Serial number" 3 "Revision number" 2 "Product Code" 1 "Vendor Id" 0 "number of entries" ;
VAL_ 1549 SubIndex_1017 0 "Producer Heartbeat Time" ;
VAL_ 1549 SubIndex_1016 126 "Consumer Heartbeat Time126" 125 "Consumer Heartbeat Time125" 124 "Consumer Heartbeat Time124" 123 "Consumer Heartbeat Time123" 122 "Consumer Heartbeat Time122" 121 "Consumer Heartbeat Time121" 120 "Consumer Heartbeat Time120" 119 "Consumer Heartbeat Time119" 118 "Consumer Heartbeat Time118" 117 "Consumer Heartbeat Time117" 116 "Consumer Heartbeat Time116" 115 "Consumer Heartbeat Time115" 114 "Consumer Heartbeat Time114" 113 "Consumer Heartbeat Time113" 112 "Consumer Heartbeat Time112" 111 "Consumer Heartbeat Time111" 110 "Consumer Heartbeat Time110" 109 "Consumer Heartbeat Time109" 108 "Consumer Heartbeat Time108" 107 "Consumer Heartbeat Time107" 106 "Consumer Heartbeat Time106" 105 "Consumer Heartbeat Time105" 104 "Consumer Heartbeat Time104" 103 "Consumer Heartbeat Time103" 102 "Consumer Heartbeat Time102" 101 "Consumer Heartbeat Time101" 100 "Consumer Heartbeat Time100" 99 "Consumer Heartbeat Time99" 98 "Consumer Heartbeat Time98" 97 "Consumer Heartbeat Time97" 96 "Consumer Heartbeat Time96" 95 "Consumer Heartbeat Time95" 94 "Consumer Heartbeat Time94" 93 "Consumer Heartbeat Time93" 92 "Consumer Heartbeat Time92" 91 "Consumer Heartbeat Time91" 90 "Consumer Heartbeat Time90" 89 "Consumer Heartbeat Time89" 88 "Consumer Heartbeat Time88" 87 "Consumer Heartbeat Time87" 86 "Consumer Heartbeat Time86" 85 "Consumer Heartbeat Time85" 84 "Consumer Heartbeat Time84" 83 "Consumer Heartbeat Time83" 82 "Consumer Heartbeat Time82" 81 "Consumer Heartbeat Time81" 80 "Consumer Heartbeat Time80" 79 "Consumer Heartbeat Time79" 78 "Consumer Heartbeat Time78" 77 "Consumer Heartbeat Time77" 76 "Consumer Heartbeat Time76" 75 "Consumer Heartbeat Time75" 74 "Consumer Heartbeat Time74" 73 "Consumer Heartbeat Time73" 72 "Consumer Heartbeat Time72" 71 "Consumer Heartbeat Time71" 70 "Consumer Heartbeat Time70" 69 "Consumer Heartbeat Time69" 68 "Consumer Heartbeat Time68" 67 "Consumer Heartbeat Time67" 66 "Consumer Heartbeat Time66" 65 "Consumer Heartbeat Time65" 64 "Consumer Heartbeat Time64" 63 "Consumer Heartbeat Time63" 62 "Consumer Heartbeat Time62" 61 "Consumer Heartbeat Time61" 60 "Consumer Heartbeat Time60" 59 "Consumer Heartbeat Time59" 58 "Consumer Heartbeat Time58" 57 "Consumer Heartbeat Time57" 56 "Consumer Heartbeat Time56" 55 "Consumer Heartbeat Time55" 54 "Consumer Heartbeat Time54" 53 "Consumer Heartbeat Time53" 52 "Consumer Heartbeat Time52" 51 "Consumer Heartbeat Time51" 50 "Consumer Heartbeat Time50" 49 "Consumer Heartbeat Time49" 48 "Consumer Heartbeat Time48" 47 "Consumer Heartbeat Time47" 46 "Consumer Heartbeat Time46" 45 "Consumer Heartbeat Time45" 44 "Consumer Heartbeat Time44" 43 "Consumer Heartbeat Time43" 42 "Consumer Heartbeat Time42" 41 "Consumer Heartbeat Time41" 40 "Consumer Heartbeat Time40" 39 "Consumer Heartbeat Time39" 38 "Consumer Heartbeat Time38" 37 "Consumer Heartbeat Time37" 36 "Consumer Heartbeat Time36" 35 "Consumer Heartbeat Time35" 34 "Consumer Heartbeat Time34" 33 "Consumer Heartbeat Time33" 32 "Consumer Heartbeat Time32" 31 "Consumer Heartbeat Time31" 30 "Consumer Heartbeat Time30" 29 "Consumer Heartbeat Time29" 28 "Consumer Heartbeat Time28" 27 "Consumer Heartbeat Time27" 26 "Consumer Heartbeat Time26" 25 "Consumer Heartbeat Time25" 24 "Consumer Heartbeat Time24" 23 "Consumer Heartbeat Time23" 22 "Consumer Heartbeat Time22" 21 "Consumer Heartbeat Time21" 20 "Consumer Heartbeat Time20" 19 "Consumer Heartbeat Time19" 18 "Consumer Heartbeat Time18" 17 "Consumer Heartbeat Time17" 16 "Consumer Heartbeat Time16" 15 "Consumer Heartbeat Time15" 14 "Consumer Heartbeat Time14" 13 "Consumer Heartbeat Time13" 12 "Consumer Heartbeat Time12" 11 "Consumer Heartbeat Time11" 10 "Consumer Heartbeat Time10" 9 "Consumer Heartbeat Time" 8 "Consumer Heartbeat Time" 7 "Consumer Heartbeat Time" 6 "Consumer Heartbeat Time" 5 "Consumer Heartbeat Time" 4 "Consumer Heartbeat Time" 3 "Consumer Heartbeat Time" 2 "Consumer Heartbeat Time" 1 "Consumer Heartbeat Time" 0 "NrOfObjects" ;
VAL_ 1549 SubIndex_1010 1 "Save all Parameters" 0 "Number of Entries" ;
VAL_ 1549 SubIndex_100D 0 "Life Time Factor" ;
VAL_ 1549 SubIndex_100C 0 "Guard Time" ;
VAL_ 1549 SubIndex_1007 0 "Sync_Window Length" ;
VAL_ 1549 SubIndex_1006 0 "Communication Cycle Period" ;
VAL_ 1549 SubIndex_1005 0 "COB-ID SYNC" ;
VAL_ 1549 SubIndex_1002 0 "Manufacturer Status Register" ;
VAL_ 1549 SubIndex_1001 0 "Error Register" ;
VAL_ 1549 SubIndex_1000 0 "Device Type" ;
VAL_ 1549 Index 25858 "supported_drive_modes" 25607 "motor_service_period" 25602 "motor_type" 24830 "digital_outputs" 24829 "digital_inputs" 24702 "polarity" 24679 "position_window" 24676 "position_actual_value" 24675 "position_actual_value" 24674 "position_demand_value" 24673 "modes_of_operation_display" 24672 "modes_of_operation" 24670 "fault_reaction_option_code" 24669 "stop_option_code" 24668 "disable_operation_option_code" 24667 "shutdown_option_code" 24666 "quick_stop_option_code" 24649 "vl_velocity_deceleration" 24648 "vl_velocity_acceleration" 24646 "vl_velocity_min_max_amount" 24644 "vl_control_effort" 24643 "vl_velocity_demand" 24642 "vl_target_velocity" 24641 "statusword" 24640 "controlword" 24639 "error_code" 24583 "abort_connection_option_code" 6662 "TxPDOMapping" 6661 "TxPDOMapping" 6660 "TxPDOMapping" 6659 "TxPDOMapping" 6658 "TxPDOMapping" 6657 "TxPDOMapping" 6656 "TxPDOMapping" 6150 "TxPDOComPar" 6149 "TxPDOComPar" 6148 "TxPDOComPar" 6147 "TxPDOComPar" 6146 "TxPDOComPar" 6145 "TxPDOComPar" 6144 "TxPDOComPar" 5639 "RxPDOMapping" 5638 "RxPDOMapping" 5637 "RxPDOMapping" 5636 "RxPDOMapping" 5635 "RxPDOMapping" 5634 "RxPDOMapping" 5633 "RxPDOMapping" 5632 "RxPDOMapping" 5127 "RxPDOComPar" 5126 "RxPDOComPar" 5125 "RxPDOComPar" 5124 "RxPDOComPar" 5123 "RxPDOComPar" 5122 "RxPDOComPar" 5121 "RxPDOComPar" 5120 "RxPDOComPar" 4120 "Identity Object" 4119 "Producer Heartbeat Time" 4118 "Consumer Heartbeat Time" 4112 "Store Parameter Field" 4109 "Life Time Factor" 4108 "Guard Time" 4103 "Sync_Window Length" 4102 "Communication Cycle Period" 4101 "COB-ID SYNC" 4098 "Manufacturer Status Register" 4097 "Error Register" 4096 "Device Type" ;
VAL_ 1549 TransferType 1 "Expedited transfer" 0 "Normal transfer" ;
VAL_ 1549 SizeIndicator 1 "Size is indicated" 0 "Size is not indicated" ;
VAL_ 1549 CCS 2 "Upload" 1 "Download" ;
VAL_ 141 ErrorCode 61444 "(DS-402) Control error" 61443 "(DS-402) Control, stroke operation" 61442 "(DS-402) Control, sub-synchronous run" 61441 "(DS-402) Control, deceleration" 35328 "(DS-402) Control" 35072 "(DS-402) Winding controller - process data monitoring" 34816 "(DS-402) Winding controller" 34560 "(DS-402) Sync controller" 34322 "(DS-402) Positioning - reference limit" 34321 "(DS-402) Positioning - following error" 34304 "(DS-402) Positioning controller" 34048 "(DS-402) Position controller" 33792 "(DS-402) Velocity speed controller" 33585 "(DS-402) Torque fault" 33569 "(DS-402) Insufficient torque" 33555 "(DS-402) Standstill torque" 33554 "(DS-402) Difficult start up" 33553 "(DS-402) Excess torque" 33536 "(DS-402) Torque control" 30208 "(DS-402) Data storage (external)" 29984 "(DS-402) Serial interface no. 2" 29968 "(DS-402) Serial interface no. 1" 29952 "(DS-402) Communication" 29696 "(DS-402) Computation circuit" 29472 "(DS-402) Position" 29456 "(DS-402) Speed" 29447 "(DS-402) Incremental sensor 3 fault" 29446 "(DS-402) Incremental sensor 2 fault" 29445 "(DS-402) Incremental sensor 1 fault" 29444 "(DS-402) Resolver 2 fault" 29443 "(DS-402) Resolver 1 fault" 29442 "(DS-402) Tacho wrong polarity" 29441 "(DS-402) Tacho fault" 29440 "(DS-402) Sensor" 29184 "(DS-402) Measurement circuit  " 28963 "(DS-402) Motor tilted" 28962 "(DS-402) Motor error or commutation malfunction" 28961 "(DS-402) Motor blocked" 28960 "(DS-402) Motor" 28947 "(DS-402) Protective circuit brake chopper" 28946 "(DS-402) Over current brake chopper" 28945 "(DS-402) Failure brake chopper" 28944 "(DS-402) Brake chopper" 28928 "(DS-402) Power" 25376 "(DS-402) Parameter error" 25360 "(DS-402) Loss of parameters" 25359 "(DS-402) Reset watchdog - data record no. 15" 25358 "(DS-402) Reset watchdog - data record no. 14" 25357 "(DS-402) Reset watchdog - data record no. 13" 25356 "(DS-402) Reset watchdog - data record no. 12" 25355 "(DS-402) Reset watchdog - data record no. 11" 25354 "(DS-402) Reset watchdog - data record no. 10" 25353 "(DS-402) Reset watchdog - data record no. 9" 25352 "(DS-402) Reset watchdog - data record no. 8" 25351 "(DS-402) Reset watchdog - data record no. 7" 25350 "(DS-402) Reset watchdog - data record no. 6" 25349 "(DS-402) Reset watchdog - data record no. 5" 25348 "(DS-402) Reset watchdog - data record no. 4" 25347 "(DS-402) Reset watchdog - data record no. 3" 25346 "(DS-402) Reset watchdog - data record no. 2" 25345 "(DS-402) Reset watchdog - data record no. 1" 24592 "(DS-402) Software reset (watchdog)" 21808 "(DS-402) EEPROM" 21792 "(DS-402) ROM/EPROM" 21776 "(DS-402) RAM" 21760 "(DS-402) Hardware memory" 21593 "(DS-402) Fuses S9 = manufacturer-specific" 21592 "(DS-402) Fuses S8 = manufacturer-specific" 21591 "(DS-402) Fuses S7 = manufacturer-specific" 21590 "(DS-402) Fuses S6 = manufacturer-specific" 21589 "(DS-402) Fuses S5 = manufacturer-specific" 21588 "(DS-402) Fuses S4 = manufacturer-specific" 21587 "(DS-402) Fuses S3 = l3" 21586 "(DS-402) Fuses S2 = l2" 21585 "(DS-402) Fuses S1 = l1" 21584 "(DS-402) Fuses" 21573 "(DS-402) Contact 5 = manufacturer-specific" 21572 "(DS-402) Contact 4 = manufacturer-specific" 21571 "(DS-402) Contact 3 = manufacturer-specific" 21570 "(DS-402) Contact 2 = manufacturer-specific" 21569 "(DS-402) Contact 1 = manufacturer-specific" 21568 "(DS-402) Contacts" 21552 "(DS-402) Input stages" 21536 "(DS-402) Chopper" 21520 "(DS-402) Output stages" 21504 "(DS-402) Power section" 21248 "(DS-402) Operating unit" 21024 "(DS-402) Control, computing circuit" 21008 "(DS-402) Control, measurement circuit" 20992 "(DS-402) Control" 20768 "(DS-402) Supply intermediate circuit" 20761 "(DS-402) Supply low voltage U9 = manufacturer-specific" 20760 "(DS-402) Supply low voltage U8 = manufacturer-specific" 20759 "(DS-402) Supply low voltage U7 = manufacturer-specific" 20758 "(DS-402) Supply low voltage U6 = manufacturer-specific" 20757 "(DS-402) Supply low voltage U5 = manufacturer-specific" 20756 "(DS-402) Supply low voltage U4 = manufacturer-specific" 20755 "(DS-402) Supply low voltage U3 = supply +5 V" 20754 "(DS-402) Supply low voltage U2 = supply +24V" 20753 "(DS-402) Supply low voltage U1 = supply ±15V" 20752 "(DS-402) Supply low voltage" 20736 "(DS-402) Supply" 17440 "(DS-402) Too low temperature supply" 17424 "(DS-402) Excess temperature supply" 17408 "(DS-402) Temperature supply" 17184 "(DS-402) Too low temperature drive" 17168 "(DS-402) Excess temperature drive" 17152 "(DS-402) Temperature drive" 16928 "(DS-402) Field circ. interrupted, too low temperature device" 16912 "(DS-402) Field circ. interrupted, excess temperature device" 16704 "(DS-402) Field circ. interrupted, temperature air outlet" 16688 "(DS-402) Field circ. interrupted, temperature supply air" 16672 "(DS-402) Field circ. interrupted, too low ambient temperature" 16656 "(DS-402) Field circ. interrupted, Excess ambient temperature" 13105 "(DS-402) Field circuit interrupted" 13104 "(DS-402) Field circuit" 13089 "(DS-402) Armature circuit interrupted" 13088 "(DS-402) Armature circuit" 13075 "(DS-402) Output over-voltage phase W " 13074 "(DS-402) Output over-voltage phase V " 13073 "(DS-402) Output over-voltage phase U " 13072 "(DS-402) Output over-voltage" 12848 "(DS-402) Load error" 12834 "(DS-402) DC link under-voltage no. 2" 12833 "(DS-402) DC link under-voltage no. 1" 12832 "(DS-402) DC link under-voltage" 12818 "(DS-402) DC link over voltage no. 2" 12817 "(DS-402) DC link over-voltage no. 1" 12816 "(DS-402) DC link over-voltage" 12610 "(DS-402) Mains frequency too small" 12609 "(DS-402) Mains frequency too great" 12608 "(DS-402) Mains frequency" 12596 "(DS-402) Phase sequence" 12595 "(DS-402) Phase failure L3" 12594 "(DS-402) Phase failure L2" 12593 "(DS-402) Phase failure L1" 12592 "(DS-402) Phase failure" 12579 "(DS-402) Mains under-voltage phase L3" 12578 "(DS-402) Mains under-voltage phase L2" 12577 "(DS-402) Mains under-voltage phase L1" 12576 "(DS-402) Mains under-voltage" 12563 "(DS-402) Mains over-voltage phase L3 " 12562 "(DS-402) Mains over-voltage phase L2" 12561 "(DS-402) Mains over-voltage phase L1" 12560 "(DS-402) Mains over-voltage" 9041 "(DS-402) Load level warning (I2t, thermal state)" 9040 "(DS-402) Load level fault (I2t, thermal state)" 9027 "(DS-402) Earth leakage (motor-side) phase W-U" 9026 "(DS-402) Earth leakage (motor-side) phase V-W" 9025 "(DS-402) Short circuit (motor-side) phases U-V" 9024 "(DS-402) Short circuit (motor-side)" 9011 "(DS-402) Earth leakage (motor-side) phase W" 9010 "(DS-402) Earth leakage (motor-side) phase V" 9009 "(DS-402) Earth leakage (motor-side) phase U" 9008 "(DS-402) Earth leakage (motor-side)" 8992 "(DS-402) Short circuit/earth leakage (motor-side)" 8978 "(DS-402) Device internal, continuous over current no. 2" 8977 "(DS-402) Device internal, continuous over current no. 1" 8976 "(DS-402) Device internal, continuous over current" 8784 "(DS-402) Short circuit (device internal) " 8768 "(DS-402) Earth leakage (device internal)" 8752 "(DS-402) Short circuit/earth leakage (device internal)" 8738 "(DS-402) Continuous over current no.2" 8737 "(DS-402) Continuous over current no.1" 8736 "(DS-402) Continuous over current (device internal)" 8724 "(DS-402) Short circuit (input), over-current in the sequence" 8723 "(DS-402) Short circuit (input), over-current in ramp function" 8722 "(DS-402) Short circuit (input), internal current no.2" 8721 "(DS-402) Short circuit (input), internal current no.1" 8499 "(DS-402) Short circuit phases (input) L3-L1" 8498 "(DS-402) Short circuit phases (input) L2-L3" 8497 "(DS-402) Short circuit phases (input) L1-L2" 8496 "(DS-402) Short circuit (input)" 8483 "(DS-402) Earth leakage (input) phase L3" 8482 "(DS-402) Earth leakage (input) phase L2" 8481 "(DS-402) Earth leakage (input) phase L1" 8480 "(DS-402) Earth leakage (input)" 8464 "(DS-402) Short circuit/earth leakage (input)" 33360 "RPDO timeout" 33344 "Unexpected SYNC data length" 33328 "DAM MPDO not processed, destination object not available" 33312 "PDO length exceeded" 33296 "PDO not processed due to length error" 33104 "Transmit COB-ID collision" 33088 "Recovered from bus off state" 33072 "Life guard error or heartbeat error" 33056 "CAN in error passive mode" 33040 "CAN overrun (objects lost)" ;
VAL_ 1794 State 127 "PreOperational" 5 "Operational" 4 "Stopped" 0 "Bootup" ;
SG_MUL_VAL_ 1421 supported_drive_modes_6502 SubIndex_6502 0-0;
SG_MUL_VAL_ 1421 SubIndex_6502 Index 25858-25858;
SG_MUL_VAL_ 1421 motor_service_period_6407 SubIndex_6407 0-0;
SG_MUL_VAL_ 1421 SubIndex_6407 Index 25607-25607;
SG_MUL_VAL_ 1421 motor_type_6402 SubIndex_6402 0-0;
SG_MUL_VAL_ 1421 SubIndex_6402 Index 25602-25602;
SG_MUL_VAL_ 1421 bitmask_60FE_02 SubIndex_60FE 2-2;
SG_MUL_VAL_ 1421 physical_outputs_60FE_01 SubIndex_60FE 1-1;
SG_MUL_VAL_ 1421 NrOfObjects_60FE_00 SubIndex_60FE 0-0;
SG_MUL_VAL_ 1421 SubIndex_60FE Index 24830-24830;
SG_MUL_VAL_ 1421 digital_inputs_60FD SubIndex_60FD 0-0;
SG_MUL_VAL_ 1421 SubIndex_60FD Index 24829-24829;
SG_MUL_VAL_ 1421 polarity_607E SubIndex_607E 0-0;
SG_MUL_VAL_ 1421 SubIndex_607E Index 24702-24702;
SG_MUL_VAL_ 1421 position_window_6067 SubIndex_6067 0-0;
SG_MUL_VAL_ 1421 SubIndex_6067 Index 24679-24679;
SG_MUL_VAL_ 1421 position_actual_value_6064 SubIndex_6064 0-0;
SG_MUL_VAL_ 1421 SubIndex_6064 Index 24676-24676;
SG_MUL_VAL_ 1421 position_actual_value_6063 SubIndex_6063 0-0;
SG_MUL_VAL_ 1421 SubIndex_6063 Index 24675-24675;
SG_MUL_VAL_ 1421 position_demand_value_6062 SubIndex_6062 0-0;
SG_MUL_VAL_ 1421 SubIndex_6062 Index 24674-24674;
SG_MUL_VAL_ 1421 modes_of_operation_display_6061 SubIndex_6061 0-0;
SG_MUL_VAL_ 1421 SubIndex_6061 Index 24673-24673;
SG_MUL_VAL_ 1421 modes_of_operation_6060 SubIndex_6060 0-0;
SG_MUL_VAL_ 1421 SubIndex_6060 Index 24672-24672;
SG_MUL_VAL_ 1421 fault_reaction_option_code_605E SubIndex_605E 0-0;
SG_MUL_VAL_ 1421 SubIndex_605E Index 24670-24670;
SG_MUL_VAL_ 1421 stop_option_code_605D SubIndex_605D 0-0;
SG_MUL_VAL_ 1421 SubIndex_605D Index 24669-24669;
SG_MUL_VAL_ 1421 disable_operation_option_co_0003 SubIndex_605C 0-0;
SG_MUL_VAL_ 1421 SubIndex_605C Index 24668-24668;
SG_MUL_VAL_ 1421 shutdown_option_code_605B SubIndex_605B 0-0;
SG_MUL_VAL_ 1421 SubIndex_605B Index 24667-24667;
SG_MUL_VAL_ 1421 quick_stop_option_code_605A SubIndex_605A 0-0;
SG_MUL_VAL_ 1421 SubIndex_605A Index 24666-24666;
SG_MUL_VAL_ 1421 delta_time_6049_02 SubIndex_6049 2-2;
SG_MUL_VAL_ 1421 delta_speed_6049_01 SubIndex_6049 1-1;
SG_MUL_VAL_ 1421 NrOfObjects_6049_00 SubIndex_6049 0-0;
SG_MUL_VAL_ 1421 SubIndex_6049 Index 24649-24649;
SG_MUL_VAL_ 1421 delta_time_6048_02 SubIndex_6048 2-2;
SG_MUL_VAL_ 1421 delta_speed_6048_01 SubIndex_6048 1-1;
SG_MUL_VAL_ 1421 NrOfObjects_6048_00 SubIndex_6048 0-0;
SG_MUL_VAL_ 1421 SubIndex_6048 Index 24648-24648;
SG_MUL_VAL_ 1421 vl_velocity_max_amount_6046_02 SubIndex_6046 2-2;
SG_MUL_VAL_ 1421 vl_velocity_min_amount_6046_01 SubIndex_6046 1-1;
SG_MUL_VAL_ 1421 vl_velocity_min_max_amount__0003 SubIndex_6046 0-0;
SG_MUL_VAL_ 1421 SubIndex_6046 Index 24646-24646;
SG_MUL_VAL_ 1421 vl_control_effort_6044 SubIndex_6044 0-0;
SG_MUL_VAL_ 1421 SubIndex_6044 Index 24644-24644;
SG_MUL_VAL_ 1421 vl_velocity_demand_6043 SubIndex_6043 0-0;
SG_MUL_VAL_ 1421 SubIndex_6043 Index 24643-24643;
SG_MUL_VAL_ 1421 vl_target_velocity_6042 SubIndex_6042 0-0;
SG_MUL_VAL_ 1421 SubIndex_6042 Index 24642-24642;
SG_MUL_VAL_ 1421 statusword_6041 SubIndex_6041 0-0;
SG_MUL_VAL_ 1421 SubIndex_6041 Index 24641-24641;
SG_MUL_VAL_ 1421 controlword_6040 SubIndex_6040 0-0;
SG_MUL_VAL_ 1421 SubIndex_6040 Index 24640-24640;
SG_MUL_VAL_ 1421 error_code_603F SubIndex_603F 0-0;
SG_MUL_VAL_ 1421 SubIndex_603F Index 24639-24639;
SG_MUL_VAL_ 1421 abort_connection_option_cod_0003 SubIndex_6007 0-0;
SG_MUL_VAL_ 1421 SubIndex_6007 Index 24583-24583;
SG_MUL_VAL_ 1421 NrOfMappedObjects_1A06_00 SubIndex_1A06 0-0;
SG_MUL_VAL_ 1421 SubIndex_1A06 Index 6662-6662;
SG_MUL_VAL_ 1421 NrOfMappedObjects_1A05_00 SubIndex_1A05 0-0;
SG_MUL_VAL_ 1421 SubIndex_1A05 Index 6661-6661;
SG_MUL_VAL_ 1421 NrOfMappedObjects_1A04_00 SubIndex_1A04 0-0;
SG_MUL_VAL_ 1421 SubIndex_1A04 Index 6660-6660;
SG_MUL_VAL_ 1421 NrOfMappedObjects_1A03_00 SubIndex_1A03 0-0;
SG_MUL_VAL_ 1421 SubIndex_1A03 Index 6659-6659;
SG_MUL_VAL_ 1421 NrOfMappedObjects_1A02_00 SubIndex_1A02 0-0;
SG_MUL_VAL_ 1421 SubIndex_1A02 Index 6658-6658;
SG_MUL_VAL_ 1421 NrOfMappedObjects_1A01_00 SubIndex_1A01 0-0;
SG_MUL_VAL_ 1421 SubIndex_1A01 Index 6657-6657;
SG_MUL_VAL_ 1421 mappedObj2_1A00_02 SubIndex_1A00 2-2;
SG_MUL_VAL_ 1421 mappedObj1_1A00_01 SubIndex_1A00 1-1;
SG_MUL_VAL_ 1421 NrOfMappedObjects_1A00_00 SubIndex_1A00 0-0;
SG_MUL_VAL_ 1421 SubIndex_1A00 Index 6656-6656;
SG_MUL_VAL_ 1421 EventTimer_1806_05 SubIndex_1806 5-5;
SG_MUL_VAL_ 1421 TransmissionType_1806_02 SubIndex_1806 2-2;
SG_MUL_VAL_ 1421 COB_ID_1806_01 SubIndex_1806 1-1;
SG_MUL_VAL_ 1421 NrOfEntries_1806_00 SubIndex_1806 0-0;
SG_MUL_VAL_ 1421 SubIndex_1806 Index 6150-6150;
SG_MUL_VAL_ 1421 EventTimer_1805_05 SubIndex_1805 5-5;
SG_MUL_VAL_ 1421 TransmissionType_1805_02 SubIndex_1805 2-2;
SG_MUL_VAL_ 1421 COB_ID_1805_01 SubIndex_1805 1-1;
SG_MUL_VAL_ 1421 NrOfEntries_1805_00 SubIndex_1805 0-0;
SG_MUL_VAL_ 1421 SubIndex_1805 Index 6149-6149;
SG_MUL_VAL_ 1421 EventTimer_1804_05 SubIndex_1804 5-5;
SG_MUL_VAL_ 1421 TransmissionType_1804_02 SubIndex_1804 2-2;
SG_MUL_VAL_ 1421 COB_ID_1804_01 SubIndex_1804 1-1;
SG_MUL_VAL_ 1421 NrOfEntries_1804_00 SubIndex_1804 0-0;
SG_MUL_VAL_ 1421 SubIndex_1804 Index 6148-6148;
SG_MUL_VAL_ 1421 EventTimer_1803_05 SubIndex_1803 5-5;
SG_MUL_VAL_ 1421 TransmissionType_1803_02 SubIndex_1803 2-2;
SG_MUL_VAL_ 1421 COB_ID_1803_01 SubIndex_1803 1-1;
SG_MUL_VAL_ 1421 NrOfEntries_1803_00 SubIndex_1803 0-0;
SG_MUL_VAL_ 1421 SubIndex_1803 Index 6147-6147;
SG_MUL_VAL_ 1421 EventTimer_1802_05 SubIndex_1802 5-5;
SG_MUL_VAL_ 1421 TransmissionType_1802_02 SubIndex_1802 2-2;
SG_MUL_VAL_ 1421 COB_ID_1802_01 SubIndex_1802 1-1;
SG_MUL_VAL_ 1421 NrOfEntries_1802_00 SubIndex_1802 0-0;
SG_MUL_VAL_ 1421 SubIndex_1802 Index 6146-6146;
SG_MUL_VAL_ 1421 EventTimer_1801_05 SubIndex_1801 5-5;
SG_MUL_VAL_ 1421 TransmissionType_1801_02 SubIndex_1801 2-2;
SG_MUL_VAL_ 1421 COB_ID_1801_01 SubIndex_1801 1-1;
SG_MUL_VAL_ 1421 NrOfEntries_1801_00 SubIndex_1801 0-0;
SG_MUL_VAL_ 1421 SubIndex_1801 Index 6145-6145;
SG_MUL_VAL_ 1421 EventTimer_1800_05 SubIndex_1800 5-5;
SG_MUL_VAL_ 1421 TransmissionType_1800_02 SubIndex_1800 2-2;
SG_MUL_VAL_ 1421 COB_ID_1800_01 SubIndex_1800 1-1;
SG_MUL_VAL_ 1421 NrOfEntries_1800_00 SubIndex_1800 0-0;
SG_MUL_VAL_ 1421 SubIndex_1800 Index 6144-6144;
SG_MUL_VAL_ 1421 NrOfMappedObjects_1607_00 SubIndex_1607 0-0;
SG_MUL_VAL_ 1421 SubIndex_1607 Index 5639-5639;
SG_MUL_VAL_ 1421 NrOfMappedObjects_1606_00 SubIndex_1606 0-0;
SG_MUL_VAL_ 1421 SubIndex_1606 Index 5638-5638;
SG_MUL_VAL_ 1421 NrOfMappedObjects_1605_00 SubIndex_1605 0-0;
SG_MUL_VAL_ 1421 SubIndex_1605 Index 5637-5637;
SG_MUL_VAL_ 1421 NrOfMappedObjects_1604_00 SubIndex_1604 0-0;
SG_MUL_VAL_ 1421 SubIndex_1604 Index 5636-5636;
SG_MUL_VAL_ 1421 NrOfMappedObjects_1603_00 SubIndex_1603 0-0;
SG_MUL_VAL_ 1421 SubIndex_1603 Index 5635-5635;
SG_MUL_VAL_ 1421 NrOfMappedObjects_1602_00 SubIndex_1602 0-0;
SG_MUL_VAL_ 1421 SubIndex_1602 Index 5634-5634;
SG_MUL_VAL_ 1421 NrOfMappedObjects_1601_00 SubIndex_1601 0-0;
SG_MUL_VAL_ 1421 SubIndex_1601 Index 5633-5633;
SG_MUL_VAL_ 1421 mappedObj2_1600_02 SubIndex_1600 2-2;
SG_MUL_VAL_ 1421 mappedObj1_1600_01 SubIndex_1600 1-1;
SG_MUL_VAL_ 1421 NrOfMappedObjects_1600_00 SubIndex_1600 0-0;
SG_MUL_VAL_ 1421 SubIndex_1600 Index 5632-5632;
SG_MUL_VAL_ 1421 TransmissionType_1407_02 SubIndex_1407 2-2;
SG_MUL_VAL_ 1421 COB_ID_1407_01 SubIndex_1407 1-1;
SG_MUL_VAL_ 1421 NrOfEntries_1407_00 SubIndex_1407 0-0;
SG_MUL_VAL_ 1421 SubIndex_1407 Index 5127-5127;
SG_MUL_VAL_ 1421 TransmissionType_1406_02 SubIndex_1406 2-2;
SG_MUL_VAL_ 1421 COB_ID_1406_01 SubIndex_1406 1-1;
SG_MUL_VAL_ 1421 NrOfEntries_1406_00 SubIndex_1406 0-0;
SG_MUL_VAL_ 1421 SubIndex_1406 Index 5126-5126;
SG_MUL_VAL_ 1421 TransmissionType_1405_02 SubIndex_1405 2-2;
SG_MUL_VAL_ 1421 COB_ID_1405_01 SubIndex_1405 1-1;
SG_MUL_VAL_ 1421 NrOfEntries_1405_00 SubIndex_1405 0-0;
SG_MUL_VAL_ 1421 SubIndex_1405 Index 5125-5125;
SG_MUL_VAL_ 1421 TransmissionType_1404_02 SubIndex_1404 2-2;
SG_MUL_VAL_ 1421 COB_ID_1404_01 SubIndex_1404 1-1;
SG_MUL_VAL_ 1421 NrOfEntries_1404_00 SubIndex_1404 0-0;
SG_MUL_VAL_ 1421 SubIndex_1404 Index 5124-5124;
SG_MUL_VAL_ 1421 TransmissionType_1403_02 SubIndex_1403 2-2;
SG_MUL_VAL_ 1421 COB_ID_1403_01 SubIndex_1403 1-1;
SG_MUL_VAL_ 1421 NrOfEntries_1403_00 SubIndex_1403 0-0;
SG_MUL_VAL_ 1421 SubIndex_1403 Index 5123-5123;
SG_MUL_VAL_ 1421 TransmissionType_1402_02 SubIndex_1402 2-2;
SG_MUL_VAL_ 1421 COB_ID_1402_01 SubIndex_1402 1-1;
SG_MUL_VAL_ 1421 NrOfEntries_1402_00 SubIndex_1402 0-0;
SG_MUL_VAL_ 1421 SubIndex_1402 Index 5122-5122;
SG_MUL_VAL_ 1421 TransmissionType_1401_02 SubIndex_1401 2-2;
SG_MUL_VAL_ 1421 COB_ID_1401_01 SubIndex_1401 1-1;
SG_MUL_VAL_ 1421 NrOfEntries_1401_00 SubIndex_1401 0-0;
SG_MUL_VAL_ 1421 SubIndex_1401 Index 5121-5121;
SG_MUL_VAL_ 1421 TransmissionType_1400_02 SubIndex_1400 2-2;
SG_MUL_VAL_ 1421 COB_ID_1400_01 SubIndex_1400 1-1;
SG_MUL_VAL_ 1421 NrOfEntries_1400_00 SubIndex_1400 0-0;
SG_MUL_VAL_ 1421 SubIndex_1400 Index 5120-5120;
SG_MUL_VAL_ 1421 Serial_number_1018_04 SubIndex_1018 4-4;
SG_MUL_VAL_ 1421 Revision_number_1018_03 SubIndex_1018 3-3;
SG_MUL_VAL_ 1421 Product_Code_1018_02 SubIndex_1018 2-2;
SG_MUL_VAL_ 1421 Vendor_Id_1018_01 SubIndex_1018 1-1;
SG_MUL_VAL_ 1421 number_of_entries_1018_00 SubIndex_1018 0-0;
SG_MUL_VAL_ 1421 SubIndex_1018 Index 4120-4120;
SG_MUL_VAL_ 1421 Producer_Heartbeat_Time_1017 SubIndex_1017 0-0;
SG_MUL_VAL_ 1421 SubIndex_1017 Index 4119-4119;
SG_MUL_VAL_ 1421 Consumer_Heartbeat_Time126_1016_ SubIndex_1016 126-126;
SG_MUL_VAL_ 1421 Consumer_Heartbeat_Time125_1016_ SubIndex_1016 125-125;
SG_MUL_VAL_ 1421 Consumer_Heartbeat_Time124_1016_ SubIndex_1016 124-124;
SG_MUL_VAL_ 1421 Consumer_Heartbeat_Time123_1016_ SubIndex_1016 123-123;
SG_MUL_VAL_ 1421 Consumer_Heartbeat_Time122_1016_ SubIndex_1016 122-122;
SG_MUL_VAL_ 1421 Consumer_Heartbeat_Time121_1016_ SubIndex_1016 121-121;
SG_MUL_VAL_ 1421 Consumer_Heartbeat_Time120_1016_ SubIndex_1016 120-120;
SG_MUL_VAL_ 1421 Consumer_Heartbeat_Time119_1016_ SubIndex_1016 119-119;
SG_MUL_VAL_ 1421 Consumer_Heartbeat_Time118_1016_ SubIndex_1016 118-118;
SG_MUL_VAL_ 1421 Consumer_Heartbeat_Time117_1016_ SubIndex_1016 117-117;
SG_MUL_VAL_ 1421 Consumer_Heartbeat_Time116_1016_ SubIndex_1016 116-116;
SG_MUL_VAL_ 1421 Consumer_Heartbeat_Time115_1016_ SubIndex_1016 115-115;
SG_MUL_VAL_ 1421 Consumer_Heartbeat_Time114_1016_ SubIndex_1016 114-114;
SG_MUL_VAL_ 1421 Consumer_Heartbeat_Time113_1016_ SubIndex_1016 113-113;
SG_MUL_VAL_ 1421 Consumer_Heartbeat_Time112_1016_ SubIndex_1016 112-112;
SG_MUL_VAL_ 1421 Consumer_Heartbeat_Time111_1016_ SubIndex_1016 111-111;
SG_MUL_VAL_ 1421 Consumer_Heartbeat_Time110_1016_ SubIndex_1016 110-110;
SG_MUL_VAL_ 1421 Consumer_Heartbeat_Time109_1016_ SubIndex_1016 109-109;
SG_MUL_VAL_ 1421 Consumer_Heartbeat_Time108_1016_ SubIndex_1016 108-108;
SG_MUL_VAL_ 1421 Consumer_Heartbeat_Time107_1016_ SubIndex_1016 107-107;
SG_MUL_VAL_ 1421 Consumer_Heartbeat_Time106_1016_ SubIndex_1016 106-106;
SG_MUL_VAL_ 1421 Consumer_Heartbeat_Time105_1016_ SubIndex_1016 105-105;
SG_MUL_VAL_ 1421 Consumer_Heartbeat_Time104_1016_ SubIndex_1016 104-104;
SG_MUL_VAL_ 1421 Consumer_Heartbeat_Time103_1016_ SubIndex_1016 103-103;
SG_MUL_VAL_ 1421 Consumer_Heartbeat_Time102_1016_ SubIndex_1016 102-102;
SG_MUL_VAL_ 1421 Consumer_Heartbeat_Time101_1016_ SubIndex_1016 101-101;
SG_MUL_VAL_ 1421 Consumer_Heartbeat_Time100_1016_ SubIndex_1016 100-100;
SG_MUL_VAL_ 1421 Consumer_Heartbeat_Time99_1016_6 SubIndex_1016 99-99;
SG_MUL_VAL_ 1421 Consumer_Heartbeat_Time98_1016_6 SubIndex_1016 98-98;
SG_MUL_VAL_ 1421 Consumer_Heartbeat_Time97_1016_6 SubIndex_1016 97-97;
SG_MUL_VAL_ 1421 Consumer_Heartbeat_Time96_1016_6 SubIndex_1016 96-96;
SG_MUL_VAL_ 1421 Consumer_Heartbeat_Time95_1016_5 SubIndex_1016 95-95;
SG_MUL_VAL_ 1421 Consumer_Heartbeat_Time94_1016_5 SubIndex_1016 94-94;
SG_MUL_VAL_ 1421 Consumer_Heartbeat_Time93_1016_5 SubIndex_1016 93-93;
SG_MUL_VAL_ 1421 Consumer_Heartbeat_Time92_1016_5 SubIndex_1016 92-92;
SG_MUL_VAL_ 1421 Consumer_Heartbeat_Time91_1016_5 SubIndex_1016 91-91;
SG_MUL_VAL_ 1421 Consumer_Heartbeat_Time90_1016_5 SubIndex_1016 90-90;
SG_MUL_VAL_ 1421 Consumer_Heartbeat_Time89_1016_5 SubIndex_1016 89-89;
SG_MUL_VAL_ 1421 Consumer_Heartbeat_Time88_1016_5 SubIndex_1016 88-88;
SG_MUL_VAL_ 1421 Consumer_Heartbeat_Time87_1016_5 SubIndex_1016 87-87;
SG_MUL_VAL_ 1421 Consumer_Heartbeat_Time86_1016_5 SubIndex_1016 86-86;
SG_MUL_VAL_ 1421 Consumer_Heartbeat_Time85_1016_5 SubIndex_1016 85-85;
SG_MUL_VAL_ 1421 Consumer_Heartbeat_Time84_1016_5 SubIndex_1016 84-84;
SG_MUL_VAL_ 1421 Consumer_Heartbeat_Time83_1016_5 SubIndex_1016 83-83;
SG_MUL_VAL_ 1421 Consumer_Heartbeat_Time82_1016_5 SubIndex_1016 82-82;
SG_MUL_VAL_ 1421 Consumer_Heartbeat_Time81_1016_5 SubIndex_1016 81-81;
SG_MUL_VAL_ 1421 Consumer_Heartbeat_Time80_1016_5 SubIndex_1016 80-80;
SG_MUL_VAL_ 1421 Consumer_Heartbeat_Time79_1016_4 SubIndex_1016 79-79;
SG_MUL_VAL_ 1421 Consumer_Heartbeat_Time78_1016_4 SubIndex_1016 78-78;
SG_MUL_VAL_ 1421 Consumer_Heartbeat_Time77_1016_4 SubIndex_1016 77-77;
SG_MUL_VAL_ 1421 Consumer_Heartbeat_Time76_1016_4 SubIndex_1016 76-76;
SG_MUL_VAL_ 1421 Consumer_Heartbeat_Time75_1016_4 SubIndex_1016 75-75;
SG_MUL_VAL_ 1421 Consumer_Heartbeat_Time74_1016_4 SubIndex_1016 74-74;
SG_MUL_VAL_ 1421 Consumer_Heartbeat_Time73_1016_4 SubIndex_1016 73-73;
SG_MUL_VAL_ 1421 Consumer_Heartbeat_Time72_1016_4 SubIndex_1016 72-72;
SG_MUL_VAL_ 1421 Consumer_Heartbeat_Time71_1016_4 SubIndex_1016 71-71;
SG_MUL_VAL_ 1421 Consumer_Heartbeat_Time70_1016_4 SubIndex_1016 70-70;
SG_MUL_VAL_ 1421 Consumer_Heartbeat_Time69_1016_4 SubIndex_1016 69-69;
SG_MUL_VAL_ 1421 Consumer_Heartbeat_Time68_1016_4 SubIndex_1016 68-68;
SG_MUL_VAL_ 1421 Consumer_Heartbeat_Time67_1016_4 SubIndex_1016 67-67;
SG_MUL_VAL_ 1421 Consumer_Heartbeat_Time66_1016_4 SubIndex_1016 66-66;
SG_MUL_VAL_ 1421 Consumer_Heartbeat_Time65_1016_4 SubIndex_1016 65-65;
SG_MUL_VAL_ 1421 Consumer_Heartbeat_Time64_1016_4 SubIndex_1016 64-64;
SG_MUL_VAL_ 1421 Consumer_Heartbeat_Time63_1016_3 SubIndex_1016 63-63;
SG_MUL_VAL_ 1421 Consumer_Heartbeat_Time62_1016_3 SubIndex_1016 62-62;
SG_MUL_VAL_ 1421 Consumer_Heartbeat_Time61_1016_3 SubIndex_1016 61-61;
SG_MUL_VAL_ 1421 Consumer_Heartbeat_Time60_1016_3 SubIndex_1016 60-60;
SG_MUL_VAL_ 1421 Consumer_Heartbeat_Time59_1016_3 SubIndex_1016 59-59;
SG_MUL_VAL_ 1421 Consumer_Heartbeat_Time58_1016_3 SubIndex_1016 58-58;
SG_MUL_VAL_ 1421 Consumer_Heartbeat_Time57_1016_3 SubIndex_1016 57-57;
SG_MUL_VAL_ 1421 Consumer_Heartbeat_Time56_1016_3 SubIndex_1016 56-56;
SG_MUL_VAL_ 1421 Consumer_Heartbeat_Time55_1016_3 SubIndex_1016 55-55;
SG_MUL_VAL_ 1421 Consumer_Heartbeat_Time54_1016_3 SubIndex_1016 54-54;
SG_MUL_VAL_ 1421 Consumer_Heartbeat_Time53_1016_3 SubIndex_1016 53-53;
SG_MUL_VAL_ 1421 Consumer_Heartbeat_Time52_1016_3 SubIndex_1016 52-52;
SG_MUL_VAL_ 1421 Consumer_Heartbeat_Time51_1016_3 SubIndex_1016 51-51;
SG_MUL_VAL_ 1421 Consumer_Heartbeat_Time50_1016_3 SubIndex_1016 50-50;
SG_MUL_VAL_ 1421 Consumer_Heartbeat_Time49_1016_3 SubIndex_1016 49-49;
SG_MUL_VAL_ 1421 Consumer_Heartbeat_Time48_1016_3 SubIndex_1016 48-48;
SG_MUL_VAL_ 1421 Consumer_Heartbeat_Time47_1016_2 SubIndex_1016 47-47;
SG_MUL_VAL_ 1421 Consumer_Heartbeat_Time46_1016_2 SubIndex_1016 46-46;
SG_MUL_VAL_ 1421 Consumer_Heartbeat_Time45_1016_2 SubIndex_1016 45-45;
SG_MUL_VAL_ 1421 Consumer_Heartbeat_Time44_1016_2 SubIndex_1016 44-44;
SG_MUL_VAL_ 1421 Consumer_Heartbeat_Time43_1016_2 SubIndex_1016 43-43;
SG_MUL_VAL_ 1421 Consumer_Heartbeat_Time42_1016_2 SubIndex_1016 42-42;
SG_MUL_VAL_ 1421 Consumer_Heartbeat_Time41_1016_2 SubIndex_1016 41-41;
SG_MUL_VAL_ 1421 Consumer_Heartbeat_Time40_1016_2 SubIndex_1016 40-40;
SG_MUL_VAL_ 1421 Consumer_Heartbeat_Time39_1016_2 SubIndex_1016 39-39;
SG_MUL_VAL_ 1421 Consumer_Heartbeat_Time38_1016_2 SubIndex_1016 38-38;
SG_MUL_VAL_ 1421 Consumer_Heartbeat_Time37_1016_2 SubIndex_1016 37-37;
SG_MUL_VAL_ 1421 Consumer_Heartbeat_Time36_1016_2 SubIndex_1016 36-36;
SG_MUL_VAL_ 1421 Consumer_Heartbeat_Time35_1016_2 SubIndex_1016 35-35;
SG_MUL_VAL_ 1421 Consumer_Heartbeat_Time34_1016_2 SubIndex_1016 34-34;
SG_MUL_VAL_ 1421 Consumer_Heartbeat_Time33_1016_2 SubIndex_1016 33-33;
SG_MUL_VAL_ 1421 Consumer_Heartbeat_Time32_1016_2 SubIndex_1016 32-32;
SG_MUL_VAL_ 1421 Consumer_Heartbeat_Time31_1016_1 SubIndex_1016 31-31;
SG_MUL_VAL_ 1421 Consumer_Heartbeat_Time30_1016_1 SubIndex_1016 30-30;
SG_MUL_VAL_ 1421 Consumer_Heartbeat_Time29_1016_1 SubIndex_1016 29-29;
SG_MUL_VAL_ 1421 Consumer_Heartbeat_Time28_1016_1 SubIndex_1016 28-28;
SG_MUL_VAL_ 1421 Consumer_Heartbeat_Time27_1016_1 SubIndex_1016 27-27;
SG_MUL_VAL_ 1421 Consumer_Heartbeat_Time26_1016_1 SubIndex_1016 26-26;
SG_MUL_VAL_ 1421 Consumer_Heartbeat_Time25_1016_1 SubIndex_1016 25-25;
SG_MUL_VAL_ 1421 Consumer_Heartbeat_Time24_1016_1 SubIndex_1016 24-24;
SG_MUL_VAL_ 1421 Consumer_Heartbeat_Time23_1016_1 SubIndex_1016 23-23;
SG_MUL_VAL_ 1421 Consumer_Heartbeat_Time22_1016_1 SubIndex_1016 22-22;
SG_MUL_VAL_ 1421 Consumer_Heartbeat_Time21_1016_1 SubIndex_1016 21-21;
SG_MUL_VAL_ 1421 Consumer_Heartbeat_Time20_1016_1 SubIndex_1016 20-20;
SG_MUL_VAL_ 1421 Consumer_Heartbeat_Time19_1016_1 SubIndex_1016 19-19;
SG_MUL_VAL_ 1421 Consumer_Heartbeat_Time18_1016_1 SubIndex_1016 18-18;
SG_MUL_VAL_ 1421 Consumer_Heartbeat_Time17_1016_1 SubIndex_1016 17-17;
SG_MUL_VAL_ 1421 Consumer_Heartbeat_Time16_1016_1 SubIndex_1016 16-16;
SG_MUL_VAL_ 1421 Consumer_Heartbeat_Time15_1016_0 SubIndex_1016 15-15;
SG_MUL_VAL_ 1421 Consumer_Heartbeat_Time14_1016_0 SubIndex_1016 14-14;
SG_MUL_VAL_ 1421 Consumer_Heartbeat_Time13_1016_0 SubIndex_1016 13-13;
SG_MUL_VAL_ 1421 Consumer_Heartbeat_Time12_1016_0 SubIndex_1016 12-12;
SG_MUL_VAL_ 1421 Consumer_Heartbeat_Time11_1016_0 SubIndex_1016 11-11;
SG_MUL_VAL_ 1421 Consumer_Heartbeat_Time10_1016_0 SubIndex_1016 10-10;
SG_MUL_VAL_ 1421 Consumer_Heartbeat_Time_1016_09 SubIndex_1016 9-9;
SG_MUL_VAL_ 1421 Consumer_Heartbeat_Time_1016_08 SubIndex_1016 8-8;
SG_MUL_VAL_ 1421 Consumer_Heartbeat_Time_1016_07 SubIndex_1016 7-7;
SG_MUL_VAL_ 1421 Consumer_Heartbeat_Time_1016_06 SubIndex_1016 6-6;
SG_MUL_VAL_ 1421 Consumer_Heartbeat_Time_1016_05 SubIndex_1016 5-5;
SG_MUL_VAL_ 1421 Consumer_Heartbeat_Time_1016_04 SubIndex_1016 4-4;
SG_MUL_VAL_ 1421 Consumer_Heartbeat_Time_1016_03 SubIndex_1016 3-3;
SG_MUL_VAL_ 1421 Consumer_Heartbeat_Time_1016_02 SubIndex_1016 2-2;
SG_MUL_VAL_ 1421 Consumer_Heartbeat_Time_1016_01 SubIndex_1016 1-1;
SG_MUL_VAL_ 1421 NrOfObjects_1016_00 SubIndex_1016 0-0;
SG_MUL_VAL_ 1421 SubIndex_1016 Index 4118-4118;
SG_MUL_VAL_ 1421 Save_all_Parameters_1010_01 SubIndex_1010 1-1;
SG_MUL_VAL_ 1421 Number_of_Entries_1010_00 SubIndex_1010 0-0;
SG_MUL_VAL_ 1421 SubIndex_1010 Index 4112-4112;
SG_MUL_VAL_ 1421 Life_Time_Factor_100D SubIndex_100D 0-0;
SG_MUL_VAL_ 1421 SubIndex_100D Index 4109-4109;
SG_MUL_VAL_ 1421 Guard_Time_100C SubIndex_100C 0-0;
SG_MUL_VAL_ 1421 SubIndex_100C Index 4108-4108;
SG_MUL_VAL_ 1421 Sync_Window_Length_1007 SubIndex_1007 0-0;
SG_MUL_VAL_ 1421 SubIndex_1007 Index 4103-4103;
SG_MUL_VAL_ 1421 Communication_Cycle_Period_1006 SubIndex_1006 0-0;
SG_MUL_VAL_ 1421 SubIndex_1006 Index 4102-4102;
SG_MUL_VAL_ 1421 COB_ID_SYNC_1005 SubIndex_1005 0-0;
SG_MUL_VAL_ 1421 SubIndex_1005 Index 4101-4101;
SG_MUL_VAL_ 1421 Manufacturer_Status_Registe_0007 SubIndex_1002 0-0;
SG_MUL_VAL_ 1421 SubIndex_1002 Index 4098-4098;
SG_MUL_VAL_ 1421 Error_Register_1001 SubIndex_1001 0-0;
SG_MUL_VAL_ 1421 SubIndex_1001 Index 4097-4097;
SG_MUL_VAL_ 1421 Device_Type_1000 SubIndex_1000 0-0;
SG_MUL_VAL_ 1421 SubIndex_1000 Index 4096-4096;
SG_MUL_VAL_ 1421 Index TransferType 1-1;
SG_MUL_VAL_ 1421 TransferType SCS 1-2;
SG_MUL_VAL_ 1421 NotUsedBytes SCS 1-2;
SG_MUL_VAL_ 1421 SizeIndicator SCS 1-2;
SG_MUL_VAL_ 1549 supported_drive_modes_6502 SubIndex_6502 0-0;
SG_MUL_VAL_ 1549 SubIndex_6502 Index 25858-25858;
SG_MUL_VAL_ 1549 motor_service_period_6407 SubIndex_6407 0-0;
SG_MUL_VAL_ 1549 SubIndex_6407 Index 25607-25607;
SG_MUL_VAL_ 1549 motor_type_6402 SubIndex_6402 0-0;
SG_MUL_VAL_ 1549 SubIndex_6402 Index 25602-25602;
SG_MUL_VAL_ 1549 bitmask_60FE_02 SubIndex_60FE 2-2;
SG_MUL_VAL_ 1549 physical_outputs_60FE_01 SubIndex_60FE 1-1;
SG_MUL_VAL_ 1549 NrOfObjects_60FE_00 SubIndex_60FE 0-0;
SG_MUL_VAL_ 1549 SubIndex_60FE Index 24830-24830;
SG_MUL_VAL_ 1549 digital_inputs_60FD SubIndex_60FD 0-0;
SG_MUL_VAL_ 1549 SubIndex_60FD Index 24829-24829;
SG_MUL_VAL_ 1549 polarity_607E SubIndex_607E 0-0;
SG_MUL_VAL_ 1549 SubIndex_607E Index 24702-24702;
SG_MUL_VAL_ 1549 position_window_6067 SubIndex_6067 0-0;
SG_MUL_VAL_ 1549 SubIndex_6067 Index 24679-24679;
SG_MUL_VAL_ 1549 position_actual_value_6064 SubIndex_6064 0-0;
SG_MUL_VAL_ 1549 SubIndex_6064 Index 24676-24676;
SG_MUL_VAL_ 1549 position_actual_value_6063 SubIndex_6063 0-0;
SG_MUL_VAL_ 1549 SubIndex_6063 Index 24675-24675;
SG_MUL_VAL_ 1549 position_demand_value_6062 SubIndex_6062 0-0;
SG_MUL_VAL_ 1549 SubIndex_6062 Index 24674-24674;
SG_MUL_VAL_ 1549 modes_of_operation_display_6061 SubIndex_6061 0-0;
SG_MUL_VAL_ 1549 SubIndex_6061 Index 24673-24673;
SG_MUL_VAL_ 1549 modes_of_operation_6060 SubIndex_6060 0-0;
SG_MUL_VAL_ 1549 SubIndex_6060 Index 24672-24672;
SG_MUL_VAL_ 1549 fault_reaction_option_code_605E SubIndex_605E 0-0;
SG_MUL_VAL_ 1549 SubIndex_605E Index 24670-24670;
SG_MUL_VAL_ 1549 stop_option_code_605D SubIndex_605D 0-0;
SG_MUL_VAL_ 1549 SubIndex_605D Index 24669-24669;
SG_MUL_VAL_ 1549 disable_operation_option_co_0004 SubIndex_605C 0-0;
SG_MUL_VAL_ 1549 SubIndex_605C Index 24668-24668;
SG_MUL_VAL_ 1549 shutdown_option_code_605B SubIndex_605B 0-0;
SG_MUL_VAL_ 1549 SubIndex_605B Index 24667-24667;
SG_MUL_VAL_ 1549 quick_stop_option_code_605A SubIndex_605A 0-0;
SG_MUL_VAL_ 1549 SubIndex_605A Index 24666-24666;
SG_MUL_VAL_ 1549 delta_time_6049_02 SubIndex_6049 2-2;
SG_MUL_VAL_ 1549 delta_speed_6049_01 SubIndex_6049 1-1;
SG_MUL_VAL_ 1549 NrOfObjects_6049_00 SubIndex_6049 0-0;
SG_MUL_VAL_ 1549 SubIndex_6049 Index 24649-24649;
SG_MUL_VAL_ 1549 delta_time_6048_02 SubIndex_6048 2-2;
SG_MUL_VAL_ 1549 delta_speed_6048_01 SubIndex_6048 1-1;
SG_MUL_VAL_ 1549 NrOfObjects_6048_00 SubIndex_6048 0-0;
SG_MUL_VAL_ 1549 SubIndex_6048 Index 24648-24648;
SG_MUL_VAL_ 1549 vl_velocity_max_amount_6046_02 SubIndex_6046 2-2;
SG_MUL_VAL_ 1549 vl_velocity_min_amount_6046_01 SubIndex_6046 1-1;
SG_MUL_VAL_ 1549 vl_velocity_min_max_amount__0004 SubIndex_6046 0-0;
SG_MUL_VAL_ 1549 SubIndex_6046 Index 24646-24646;
SG_MUL_VAL_ 1549 vl_control_effort_6044 SubIndex_6044 0-0;
SG_MUL_VAL_ 1549 SubIndex_6044 Index 24644-24644;
SG_MUL_VAL_ 1549 vl_velocity_demand_6043 SubIndex_6043 0-0;
SG_MUL_VAL_ 1549 SubIndex_6043 Index 24643-24643;
SG_MUL_VAL_ 1549 vl_target_velocity_6042 SubIndex_6042 0-0;
SG_MUL_VAL_ 1549 SubIndex_6042 Index 24642-24642;
SG_MUL_VAL_ 1549 statusword_6041 SubIndex_6041 0-0;
SG_MUL_VAL_ 1549 SubIndex_6041 Index 24641-24641;
SG_MUL_VAL_ 1549 controlword_6040 SubIndex_6040 0-0;
SG_MUL_VAL_ 1549 SubIndex_6040 Index 24640-24640;
SG_MUL_VAL_ 1549 error_code_603F SubIndex_603F 0-0;
SG_MUL_VAL_ 1549 SubIndex_603F Index 24639-24639;
SG_MUL_VAL_ 1549 abort_connection_option_cod_0004 SubIndex_6007 0-0;
SG_MUL_VAL_ 1549 SubIndex_6007 Index 24583-24583;
SG_MUL_VAL_ 1549 NrOfMappedObjects_1A06_00 SubIndex_1A06 0-0;
SG_MUL_VAL_ 1549 SubIndex_1A06 Index 6662-6662;
SG_MUL_VAL_ 1549 NrOfMappedObjects_1A05_00 SubIndex_1A05 0-0;
SG_MUL_VAL_ 1549 SubIndex_1A05 Index 6661-6661;
SG_MUL_VAL_ 1549 NrOfMappedObjects_1A04_00 SubIndex_1A04 0-0;
SG_MUL_VAL_ 1549 SubIndex_1A04 Index 6660-6660;
SG_MUL_VAL_ 1549 NrOfMappedObjects_1A03_00 SubIndex_1A03 0-0;
SG_MUL_VAL_ 1549 SubIndex_1A03 Index 6659-6659;
SG_MUL_VAL_ 1549 NrOfMappedObjects_1A02_00 SubIndex_1A02 0-0;
SG_MUL_VAL_ 1549 SubIndex_1A02 Index 6658-6658;
SG_MUL_VAL_ 1549 NrOfMappedObjects_1A01_00 SubIndex_1A01 0-0;
SG_MUL_VAL_ 1549 SubIndex_1A01 Index 6657-6657;
SG_MUL_VAL_ 1549 mappedObj2_1A00_02 SubIndex_1A00 2-2;
SG_MUL_VAL_ 1549 mappedObj1_1A00_01 SubIndex_1A00 1-1;
SG_MUL_VAL_ 1549 NrOfMappedObjects_1A00_00 SubIndex_1A00 0-0;
SG_MUL_VAL_ 1549 SubIndex_1A00 Index 6656-6656;
SG_MUL_VAL_ 1549 EventTimer_1806_05 SubIndex_1806 5-5;
SG_MUL_VAL_ 1549 TransmissionType_1806_02 SubIndex_1806 2-2;
SG_MUL_VAL_ 1549 COB_ID_1806_01 SubIndex_1806 1-1;
SG_MUL_VAL_ 1549 NrOfEntries_1806_00 SubIndex_1806 0-0;
SG_MUL_VAL_ 1549 SubIndex_1806 Index 6150-6150;
SG_MUL_VAL_ 1549 EventTimer_1805_05 SubIndex_1805 5-5;
SG_MUL_VAL_ 1549 TransmissionType_1805_02 SubIndex_1805 2-2;
SG_MUL_VAL_ 1549 COB_ID_1805_01 SubIndex_1805 1-1;
SG_MUL_VAL_ 1549 NrOfEntries_1805_00 SubIndex_1805 0-0;
SG_MUL_VAL_ 1549 SubIndex_1805 Index 6149-6149;
SG_MUL_VAL_ 1549 EventTimer_1804_05 SubIndex_1804 5-5;
SG_MUL_VAL_ 1549 TransmissionType_1804_02 SubIndex_1804 2-2;
SG_MUL_VAL_ 1549 COB_ID_1804_01 SubIndex_1804 1-1;
SG_MUL_VAL_ 1549 NrOfEntries_1804_00 SubIndex_1804 0-0;
SG_MUL_VAL_ 1549 SubIndex_1804 Index 6148-6148;
SG_MUL_VAL_ 1549 EventTimer_1803_05 SubIndex_1803 5-5;
SG_MUL_VAL_ 1549 TransmissionType_1803_02 SubIndex_1803 2-2;
SG_MUL_VAL_ 1549 COB_ID_1803_01 SubIndex_1803 1-1;
SG_MUL_VAL_ 1549 NrOfEntries_1803_00 SubIndex_1803 0-0;
SG_MUL_VAL_ 1549 SubIndex_1803 Index 6147-6147;
SG_MUL_VAL_ 1549 EventTimer_1802_05 SubIndex_1802 5-5;
SG_MUL_VAL_ 1549 TransmissionType_1802_02 SubIndex_1802 2-2;
SG_MUL_VAL_ 1549 COB_ID_1802_01 SubIndex_1802 1-1;
SG_MUL_VAL_ 1549 NrOfEntries_1802_00 SubIndex_1802 0-0;
SG_MUL_VAL_ 1549 SubIndex_1802 Index 6146-6146;
SG_MUL_VAL_ 1549 EventTimer_1801_05 SubIndex_1801 5-5;
SG_MUL_VAL_ 1549 TransmissionType_1801_02 SubIndex_1801 2-2;
SG_MUL_VAL_ 1549 COB_ID_1801_01 SubIndex_1801 1-1;
SG_MUL_VAL_ 1549 NrOfEntries_1801_00 SubIndex_1801 0-0;
SG_MUL_VAL_ 1549 SubIndex_1801 Index 6145-6145;
SG_MUL_VAL_ 1549 EventTimer_1800_05 SubIndex_1800 5-5;
SG_MUL_VAL_ 1549 TransmissionType_1800_02 SubIndex_1800 2-2;
SG_MUL_VAL_ 1549 COB_ID_1800_01 SubIndex_1800 1-1;
SG_MUL_VAL_ 1549 NrOfEntries_1800_00 SubIndex_1800 0-0;
SG_MUL_VAL_ 1549 SubIndex_1800 Index 6144-6144;
SG_MUL_VAL_ 1549 NrOfMappedObjects_1607_00 SubIndex_1607 0-0;
SG_MUL_VAL_ 1549 SubIndex_1607 Index 5639-5639;
SG_MUL_VAL_ 1549 NrOfMappedObjects_1606_00 SubIndex_1606 0-0;
SG_MUL_VAL_ 1549 SubIndex_1606 Index 5638-5638;
SG_MUL_VAL_ 1549 NrOfMappedObjects_1605_00 SubIndex_1605 0-0;
SG_MUL_VAL_ 1549 SubIndex_1605 Index 5637-5637;
SG_MUL_VAL_ 1549 NrOfMappedObjects_1604_00 SubIndex_1604 0-0;
SG_MUL_VAL_ 1549 SubIndex_1604 Index 5636-5636;
SG_MUL_VAL_ 1549 NrOfMappedObjects_1603_00 SubIndex_1603 0-0;
SG_MUL_VAL_ 1549 SubIndex_1603 Index 5635-5635;
SG_MUL_VAL_ 1549 NrOfMappedObjects_1602_00 SubIndex_1602 0-0;
SG_MUL_VAL_ 1549 SubIndex_1602 Index 5634-5634;
SG_MUL_VAL_ 1549 NrOfMappedObjects_1601_00 SubIndex_1601 0-0;
SG_MUL_VAL_ 1549 SubIndex_1601 Index 5633-5633;
SG_MUL_VAL_ 1549 mappedObj2_1600_02 SubIndex_1600 2-2;
SG_MUL_VAL_ 1549 mappedObj1_1600_01 SubIndex_1600 1-1;
SG_MUL_VAL_ 1549 NrOfMappedObjects_1600_00 SubIndex_1600 0-0;
SG_MUL_VAL_ 1549 SubIndex_1600 Index 5632-5632;
SG_MUL_VAL_ 1549 TransmissionType_1407_02 SubIndex_1407 2-2;
SG_MUL_VAL_ 1549 COB_ID_1407_01 SubIndex_1407 1-1;
SG_MUL_VAL_ 1549 NrOfEntries_1407_00 SubIndex_1407 0-0;
SG_MUL_VAL_ 1549 SubIndex_1407 Index 5127-5127;
SG_MUL_VAL_ 1549 TransmissionType_1406_02 SubIndex_1406 2-2;
SG_MUL_VAL_ 1549 COB_ID_1406_01 SubIndex_1406 1-1;
SG_MUL_VAL_ 1549 NrOfEntries_1406_00 SubIndex_1406 0-0;
SG_MUL_VAL_ 1549 SubIndex_1406 Index 5126-5126;
SG_MUL_VAL_ 1549 TransmissionType_1405_02 SubIndex_1405 2-2;
SG_MUL_VAL_ 1549 COB_ID_1405_01 SubIndex_1405 1-1;
SG_MUL_VAL_ 1549 NrOfEntries_1405_00 SubIndex_1405 0-0;
SG_MUL_VAL_ 1549 SubIndex_1405 Index 5125-5125;
SG_MUL_VAL_ 1549 TransmissionType_1404_02 SubIndex_1404 2-2;
SG_MUL_VAL_ 1549 COB_ID_1404_01 SubIndex_1404 1-1;
SG_MUL_VAL_ 1549 NrOfEntries_1404_00 SubIndex_1404 0-0;
SG_MUL_VAL_ 1549 SubIndex_1404 Index 5124-5124;
SG_MUL_VAL_ 1549 TransmissionType_1403_02 SubIndex_1403 2-2;
SG_MUL_VAL_ 1549 COB_ID_1403_01 SubIndex_1403 1-1;
SG_MUL_VAL_ 1549 NrOfEntries_1403_00 SubIndex_1403 0-0;
SG_MUL_VAL_ 1549 SubIndex_1403 Index 5123-5123;
SG_MUL_VAL_ 1549 TransmissionType_1402_02 SubIndex_1402 2-2;
SG_MUL_VAL_ 1549 COB_ID_1402_01 SubIndex_1402 1-1;
SG_MUL_VAL_ 1549 NrOfEntries_1402_00 SubIndex_1402 0-0;
SG_MUL_VAL_ 1549 SubIndex_1402 Index 5122-5122;
SG_MUL_VAL_ 1549 TransmissionType_1401_02 SubIndex_1401 2-2;
SG_MUL_VAL_ 1549 COB_ID_1401_01 SubIndex_1401 1-1;
SG_MUL_VAL_ 1549 NrOfEntries_1401_00 SubIndex_1401 0-0;
SG_MUL_VAL_ 1549 SubIndex_1401 Index 5121-5121;
SG_MUL_VAL_ 1549 TransmissionType_1400_02 SubIndex_1400 2-2;
SG_MUL_VAL_ 1549 COB_ID_1400_01 SubIndex_1400 1-1;
SG_MUL_VAL_ 1549 NrOfEntries_1400_00 SubIndex_1400 0-0;
SG_MUL_VAL_ 1549 SubIndex_1400 Index 5120-5120;
SG_MUL_VAL_ 1549 Serial_number_1018_04 SubIndex_1018 4-4;
SG_MUL_VAL_ 1549 Revision_number_1018_03 SubIndex_1018 3-3;
SG_MUL_VAL_ 1549 Product_Code_1018_02 SubIndex_1018 2-2;
SG_MUL_VAL_ 1549 Vendor_Id_1018_01 SubIndex_1018 1-1;
SG_MUL_VAL_ 1549 number_of_entries_1018_00 SubIndex_1018 0-0;
SG_MUL_VAL_ 1549 SubIndex_1018 Index 4120-4120;
SG_MUL_VAL_ 1549 Producer_Heartbeat_Time_1017 SubIndex_1017 0-0;
SG_MUL_VAL_ 1549 SubIndex_1017 Index 4119-4119;
SG_MUL_VAL_ 1549 Consumer_Heartbeat_Time126__0000 SubIndex_1016 126-126;
SG_MUL_VAL_ 1549 Consumer_Heartbeat_Time125__0000 SubIndex_1016 125-125;
SG_MUL_VAL_ 1549 Consumer_Heartbeat_Time124__0000 SubIndex_1016 124-124;
SG_MUL_VAL_ 1549 Consumer_Heartbeat_Time123__0000 SubIndex_1016 123-123;
SG_MUL_VAL_ 1549 Consumer_Heartbeat_Time122__0000 SubIndex_1016 122-122;
SG_MUL_VAL_ 1549 Consumer_Heartbeat_Time121__0000 SubIndex_1016 121-121;
SG_MUL_VAL_ 1549 Consumer_Heartbeat_Time120__0000 SubIndex_1016 120-120;
SG_MUL_VAL_ 1549 Consumer_Heartbeat_Time119__0000 SubIndex_1016 119-119;
SG_MUL_VAL_ 1549 Consumer_Heartbeat_Time118__0000 SubIndex_1016 118-118;
SG_MUL_VAL_ 1549 Consumer_Heartbeat_Time117__0000 SubIndex_1016 117-117;
SG_MUL_VAL_ 1549 Consumer_Heartbeat_Time116__0000 SubIndex_1016 116-116;
SG_MUL_VAL_ 1549 Consumer_Heartbeat_Time115__0000 SubIndex_1016 115-115;
SG_MUL_VAL_ 1549 Consumer_Heartbeat_Time114__0000 SubIndex_1016 114-114;
SG_MUL_VAL_ 1549 Consumer_Heartbeat_Time113__0000 SubIndex_1016 113-113;
SG_MUL_VAL_ 1549 Consumer_Heartbeat_Time112__0000 SubIndex_1016 112-112;
SG_MUL_VAL_ 1549 Consumer_Heartbeat_Time111__0000 SubIndex_1016 111-111;
SG_MUL_VAL_ 1549 Consumer_Heartbeat_Time110__0000 SubIndex_1016 110-110;
SG_MUL_VAL_ 1549 Consumer_Heartbeat_Time109__0000 SubIndex_1016 109-109;
SG_MUL_VAL_ 1549 Consumer_Heartbeat_Time108__0000 SubIndex_1016 108-108;
SG_MUL_VAL_ 1549 Consumer_Heartbeat_Time107__0000 SubIndex_1016 107-107;
SG_MUL_VAL_ 1549 Consumer_Heartbeat_Time106__0000 SubIndex_1016 106-106;
SG_MUL_VAL_ 1549 Consumer_Heartbeat_Time105__0000 SubIndex_1016 105-105;
SG_MUL_VAL_ 1549 Consumer_Heartbeat_Time104__0000 SubIndex_1016 104-104;
SG_MUL_VAL_ 1549 Consumer_Heartbeat_Time103__0000 SubIndex_1016 103-103;
SG_MUL_VAL_ 1549 Consumer_Heartbeat_Time102__0000 SubIndex_1016 102-102;
SG_MUL_VAL_ 1549 Consumer_Heartbeat_Time101__0000 SubIndex_1016 101-101;
SG_MUL_VAL_ 1549 Consumer_Heartbeat_Time100__0000 SubIndex_1016 100-100;
SG_MUL_VAL_ 1549 Consumer_Heartbeat_Time99_1_0000 SubIndex_1016 99-99;
SG_MUL_VAL_ 1549 Consumer_Heartbeat_Time98_1_0000 SubIndex_1016 98-98;
SG_MUL_VAL_ 1549 Consumer_Heartbeat_Time97_1_0000 SubIndex_1016 97-97;
SG_MUL_VAL_ 1549 Consumer_Heartbeat_Time96_1_0000 SubIndex_1016 96-96;
SG_MUL_VAL_ 1549 Consumer_Heartbeat_Time95_1_0000 SubIndex_1016 95-95;
SG_MUL_VAL_ 1549 Consumer_Heartbeat_Time94_1_0000 SubIndex_1016 94-94;
SG_MUL_VAL_ 1549 Consumer_Heartbeat_Time93_1_0000 SubIndex_1016 93-93;
SG_MUL_VAL_ 1549 Consumer_Heartbeat_Time92_1_0000 SubIndex_1016 92-92;
SG_MUL_VAL_ 1549 Consumer_Heartbeat_Time91_1_0000 SubIndex_1016 91-91;
SG_MUL_VAL_ 1549 Consumer_Heartbeat_Time90_1_0000 SubIndex_1016 90-90;
SG_MUL_VAL_ 1549 Consumer_Heartbeat_Time89_1_0000 SubIndex_1016 89-89;
SG_MUL_VAL_ 1549 Consumer_Heartbeat_Time88_1_0000 SubIndex_1016 88-88;
SG_MUL_VAL_ 1549 Consumer_Heartbeat_Time87_1_0000 SubIndex_1016 87-87;
SG_MUL_VAL_ 1549 Consumer_Heartbeat_Time86_1_0000 SubIndex_1016 86-86;
SG_MUL_VAL_ 1549 Consumer_Heartbeat_Time85_1_0000 SubIndex_1016 85-85;
SG_MUL_VAL_ 1549 Consumer_Heartbeat_Time84_1_0000 SubIndex_1016 84-84;
SG_MUL_VAL_ 1549 Consumer_Heartbeat_Time83_1_0000 SubIndex_1016 83-83;
SG_MUL_VAL_ 1549 Consumer_Heartbeat_Time82_1_0000 SubIndex_1016 82-82;
SG_MUL_VAL_ 1549 Consumer_Heartbeat_Time81_1_0000 SubIndex_1016 81-81;
SG_MUL_VAL_ 1549 Consumer_Heartbeat_Time80_1_0000 SubIndex_1016 80-80;
SG_MUL_VAL_ 1549 Consumer_Heartbeat_Time79_1_0000 SubIndex_1016 79-79;
SG_MUL_VAL_ 1549 Consumer_Heartbeat_Time78_1_0000 SubIndex_1016 78-78;
SG_MUL_VAL_ 1549 Consumer_Heartbeat_Time77_1_0000 SubIndex_1016 77-77;
SG_MUL_VAL_ 1549 Consumer_Heartbeat_Time76_1_0000 SubIndex_1016 76-76;
SG_MUL_VAL_ 1549 Consumer_Heartbeat_Time75_1_0000 SubIndex_1016 75-75;
SG_MUL_VAL_ 1549 Consumer_Heartbeat_Time74_1_0000 SubIndex_1016 74-74;
SG_MUL_VAL_ 1549 Consumer_Heartbeat_Time73_1_0000 SubIndex_1016 73-73;
SG_MUL_VAL_ 1549 Consumer_Heartbeat_Time72_1_0000 SubIndex_1016 72-72;
SG_MUL_VAL_ 1549 Consumer_Heartbeat_Time71_1_0000 SubIndex_1016 71-71;
SG_MUL_VAL_ 1549 Consumer_Heartbeat_Time70_1_0000 SubIndex_1016 70-70;
SG_MUL_VAL_ 1549 Consumer_Heartbeat_Time69_1_0000 SubIndex_1016 69-69;
SG_MUL_VAL_ 1549 Consumer_Heartbeat_Time68_1_0000 SubIndex_1016 68-68;
SG_MUL_VAL_ 1549 Consumer_Heartbeat_Time67_1_0000 SubIndex_1016 67-67;
SG_MUL_VAL_ 1549 Consumer_Heartbeat_Time66_1_0000 SubIndex_1016 66-66;
SG_MUL_VAL_ 1549 Consumer_Heartbeat_Time65_1_0000 SubIndex_1016 65-65;
SG_MUL_VAL_ 1549 Consumer_Heartbeat_Time64_1_0000 SubIndex_1016 64-64;
SG_MUL_VAL_ 1549 Consumer_Heartbeat_Time63_1_0000 SubIndex_1016 63-63;
SG_MUL_VAL_ 1549 Consumer_Heartbeat_Time62_1_0000 SubIndex_1016 62-62;
SG_MUL_VAL_ 1549 Consumer_Heartbeat_Time61_1_0000 SubIndex_1016 61-61;
SG_MUL_VAL_ 1549 Consumer_Heartbeat_Time60_1_0000 SubIndex_1016 60-60;
SG_MUL_VAL_ 1549 Consumer_Heartbeat_Time59_1_0000 SubIndex_1016 59-59;
SG_MUL_VAL_ 1549 Consumer_Heartbeat_Time58_1_0000 SubIndex_1016 58-58;
SG_MUL_VAL_ 1549 Consumer_Heartbeat_Time57_1_0000 SubIndex_1016 57-57;
SG_MUL_VAL_ 1549 Consumer_Heartbeat_Time56_1_0000 SubIndex_1016 56-56;
SG_MUL_VAL_ 1549 Consumer_Heartbeat_Time55_1_0000 SubIndex_1016 55-55;
SG_MUL_VAL_ 1549 Consumer_Heartbeat_Time54_1_0000 SubIndex_1016 54-54;
SG_MUL_VAL_ 1549 Consumer_Heartbeat_Time53_1_0000 SubIndex_1016 53-53;
SG_MUL_VAL_ 1549 Consumer_Heartbeat_Time52_1_0000 SubIndex_1016 52-52;
SG_MUL_VAL_ 1549 Consumer_Heartbeat_Time51_1_0000 SubIndex_1016 51-51;
SG_MUL_VAL_ 1549 Consumer_Heartbeat_Time50_1_0000 SubIndex_1016 50-50;
SG_MUL_VAL_ 1549 Consumer_Heartbeat_Time49_1_0000 SubIndex_1016 49-49;
SG_MUL_VAL_ 1549 Consumer_Heartbeat_Time48_1_0000 SubIndex_1016 48-48;
SG_MUL_VAL_ 1549 Consumer_Heartbeat_Time47_1_0000 SubIndex_1016 47-47;
SG_MUL_VAL_ 1549 Consumer_Heartbeat_Time46_1_0000 SubIndex_1016 46-46;
SG_MUL_VAL_ 1549 Consumer_Heartbeat_Time45_1_0000 SubIndex_1016 45-45;
SG_MUL_VAL_ 1549 Consumer_Heartbeat_Time44_1_0000 SubIndex_1016 44-44;
SG_MUL_VAL_ 1549 Consumer_Heartbeat_Time43_1_0000 SubIndex_1016 43-43;
SG_MUL_VAL_ 1549 Consumer_Heartbeat_Time42_1_0000 SubIndex_1016 42-42;
SG_MUL_VAL_ 1549 Consumer_Heartbeat_Time41_1_0000 SubIndex_1016 41-41;
SG_MUL_VAL_ 1549 Consumer_Heartbeat_Time40_1_0000 SubIndex_1016 40-40;
SG_MUL_VAL_ 1549 Consumer_Heartbeat_Time39_1_0000 SubIndex_1016 39-39;
SG_MUL_VAL_ 1549 Consumer_Heartbeat_Time38_1_0000 SubIndex_1016 38-38;
SG_MUL_VAL_ 1549 Consumer_Heartbeat_Time37_1_0000 SubIndex_1016 37-37;
SG_MUL_VAL_ 1549 Consumer_Heartbeat_Time36_1_0000 SubIndex_1016 36-36;
SG_MUL_VAL_ 1549 Consumer_Heartbeat_Time35_1_0000 SubIndex_1016 35-35;
SG_MUL_VAL_ 1549 Consumer_Heartbeat_Time34_1_0000 SubIndex_1016 34-34;
SG_MUL_VAL_ 1549 Consumer_Heartbeat_Time33_1_0000 SubIndex_1016 33-33;
SG_MUL_VAL_ 1549 Consumer_Heartbeat_Time32_1_0000 SubIndex_1016 32-32;
SG_MUL_VAL_ 1549 Consumer_Heartbeat_Time31_1_0000 SubIndex_1016 31-31;
SG_MUL_VAL_ 1549 Consumer_Heartbeat_Time30_1_0000 SubIndex_1016 30-30;
SG_MUL_VAL_ 1549 Consumer_Heartbeat_Time29_1_0000 SubIndex_1016 29-29;
SG_MUL_VAL_ 1549 Consumer_Heartbeat_Time28_1_0000 SubIndex_1016 28-28;
SG_MUL_VAL_ 1549 Consumer_Heartbeat_Time27_1_0000 SubIndex_1016 27-27;
SG_MUL_VAL_ 1549 Consumer_Heartbeat_Time26_1_0000 SubIndex_1016 26-26;
SG_MUL_VAL_ 1549 Consumer_Heartbeat_Time25_1_0000 SubIndex_1016 25-25;
SG_MUL_VAL_ 1549 Consumer_Heartbeat_Time24_1_0000 SubIndex_1016 24-24;
SG_MUL_VAL_ 1549 Consumer_Heartbeat_Time23_1_0000 SubIndex_1016 23-23;
SG_MUL_VAL_ 1549 Consumer_Heartbeat_Time22_1_0000 SubIndex_1016 22-22;
SG_MUL_VAL_ 1549 Consumer_Heartbeat_Time21_1_0000 SubIndex_1016 21-21;
SG_MUL_VAL_ 1549 Consumer_Heartbeat_Time20_1_0000 SubIndex_1016 20-20;
SG_MUL_VAL_ 1549 Consumer_Heartbeat_Time19_1_0000 SubIndex_1016 19-19;
SG_MUL_VAL_ 1549 Consumer_Heartbeat_Time18_1_0000 SubIndex_1016 18-18;
SG_MUL_VAL_ 1549 Consumer_Heartbeat_Time17_1_0000 SubIndex_1016 17-17;
SG_MUL_VAL_ 1549 Consumer_Heartbeat_Time16_1_0000 SubIndex_1016 16-16;
SG_MUL_VAL_ 1549 Consumer_Heartbeat_Time15_1_0000 SubIndex_1016 15-15;
SG_MUL_VAL_ 1549 Consumer_Heartbeat_Time14_1_0000 SubIndex_1016 14-14;
SG_MUL_VAL_ 1549 Consumer_Heartbeat_Time13_1_0000 SubIndex_1016 13-13;
SG_MUL_VAL_ 1549 Consumer_Heartbeat_Time12_1_0000 SubIndex_1016 12-12;
SG_MUL_VAL_ 1549 Consumer_Heartbeat_Time11_1_0000 SubIndex_1016 11-11;
SG_MUL_VAL_ 1549 Consumer_Heartbeat_Time10_1_0000 SubIndex_1016 10-10;
SG_MUL_VAL_ 1549 Consumer_Heartbeat_Time_1016_09 SubIndex_1016 9-9;
SG_MUL_VAL_ 1549 Consumer_Heartbeat_Time_1016_08 SubIndex_1016 8-8;
SG_MUL_VAL_ 1549 Consumer_Heartbeat_Time_1016_07 SubIndex_1016 7-7;
SG_MUL_VAL_ 1549 Consumer_Heartbeat_Time_1016_06 SubIndex_1016 6-6;
SG_MUL_VAL_ 1549 Consumer_Heartbeat_Time_1016_05 SubIndex_1016 5-5;
SG_MUL_VAL_ 1549 Consumer_Heartbeat_Time_1016_04 SubIndex_1016 4-4;
SG_MUL_VAL_ 1549 Consumer_Heartbeat_Time_1016_03 SubIndex_1016 3-3;
SG_MUL_VAL_ 1549 Consumer_Heartbeat_Time_1016_02 SubIndex_1016 2-2;
SG_MUL_VAL_ 1549 Consumer_Heartbeat_Time_1016_01 SubIndex_1016 1-1;
SG_MUL_VAL_ 1549 NrOfObjects_1016_00 SubIndex_1016 0-0;
SG_MUL_VAL_ 1549 SubIndex_1016 Index 4118-4118;
SG_MUL_VAL_ 1549 Save_all_Parameters_1010_01 SubIndex_1010 1-1;
SG_MUL_VAL_ 1549 Number_of_Entries_1010_00 SubIndex_1010 0-0;
SG_MUL_VAL_ 1549 SubIndex_1010 Index 4112-4112;
SG_MUL_VAL_ 1549 Life_Time_Factor_100D SubIndex_100D 0-0;
SG_MUL_VAL_ 1549 SubIndex_100D Index 4109-4109;
SG_MUL_VAL_ 1549 Guard_Time_100C SubIndex_100C 0-0;
SG_MUL_VAL_ 1549 SubIndex_100C Index 4108-4108;
SG_MUL_VAL_ 1549 Sync_Window_Length_1007 SubIndex_1007 0-0;
SG_MUL_VAL_ 1549 SubIndex_1007 Index 4103-4103;
SG_MUL_VAL_ 1549 Communication_Cycle_Period_1006 SubIndex_1006 0-0;
SG_MUL_VAL_ 1549 SubIndex_1006 Index 4102-4102;
SG_MUL_VAL_ 1549 COB_ID_SYNC_1005 SubIndex_1005 0-0;
SG_MUL_VAL_ 1549 SubIndex_1005 Index 4101-4101;
SG_MUL_VAL_ 1549 Manufacturer_Status_Registe_0008 SubIndex_1002 0-0;
SG_MUL_VAL_ 1549 SubIndex_1002 Index 4098-4098;
SG_MUL_VAL_ 1549 Error_Register_1001 SubIndex_1001 0-0;
SG_MUL_VAL_ 1549 SubIndex_1001 Index 4097-4097;
SG_MUL_VAL_ 1549 Device_Type_1000 SubIndex_1000 0-0;
SG_MUL_VAL_ 1549 SubIndex_1000 Index 4096-4096;
SG_MUL_VAL_ 1549 Index TransferType 1-1;
SG_MUL_VAL_ 1549 TransferType CCS 1-2;
SG_MUL_VAL_ 1549 NotUsedBytes CCS 1-2;
SG_MUL_VAL_ 1549 SizeIndicator CCS 1-2;
